VERSION ""

NS_ :

BS_:

BU_: VMCU VGGSECUSystem TECU OBDScanT2 HMIIOM EMS ECUspare2 ECUspare1 DACU CIOM BBM

BO_ 2432645412 VMCU_BB2_02P: 8 VMCU
 SG_ LevelControlInformation_UB_ISig_ : 22|1@1+ (1,0) [0|0] ""  CIOM,HMIIOM,TECU
 SG_ LiftAxle2LiftFuncSelected_ISig_4 : 11|3@1+ (1,0) [0|0] ""  HMIIOM
 SG_ StopLevelChangeAck_ISig_4 : 6|2@1+ (1,0) [0|0] ""  CIOM
 SG_ HeightAdjustmentAllowed_ISig_4 : 38|2@1+ (1,0) [0|0] ""  CIOM
 SG_ LiftAxle2UpRequestACK_ISig_4 : 0|3@1+ (1,0) [0|0] ""  CIOM,HMIIOM
 SG_ RideHeightStatus_ISig_4 : 44|4@1+ (1,0) [0|0] ""  HMIIOM,CIOM,BBM
 SG_ RideHeightOutsideTargetRange_ISi : 32|3@1+ (1,0) [0|0] ""  HMIIOM,CIOM
 SG_ LoadDistributionFuncSelected_ISi : 56|4@1+ (1,0) [0|0] ""  CIOM
 SG_ RideHeightStorageAck_ISig_4 : 30|2@1+ (1,0) [0|0] ""  CIOM
 SG_ LiftAxle2LowerACK_ISig_4 : 27|3@1+ (1,0) [0|0] ""  HMIIOM
 SG_ LiftAxle1UpRequestACK_ISig_4 : 3|3@1+ (1,0) [0|0] ""  HMIIOM,CIOM
 SG_ LiftAxle1PositionStatus_ISig_4 : 16|3@1+ (1,0) [0|0] ""  BBM,CIOM,TECU,DACU,HMIIOM
 SG_ LiftAxle2AutoLiftSelected_ISig_4 : 54|2@1+ (1,0) [0|0] ""  HMIIOM
 SG_ LiftAxle1LowerACK_ISig_4 : 24|3@1+ (1,0) [0|0] ""  HMIIOM
 SG_ LiftAxle2PositionStatus_ISig_4 : 19|3@1+ (1,0) [0|0] ""  HMIIOM,BBM,CIOM
 SG_ LevelControlInformation_ISig_4 : 48|4@1+ (1,0) [0|0] ""  TECU,HMIIOM,CIOM
 SG_ LoadDistributionChangeACK_ISig_4 : 35|3@1+ (1,0) [0|0] ""  HMIIOM,CIOM
 SG_ LiftAxle1AutoLiftSelected_ISig_4 : 52|2@1+ (1,0) [0|0] ""  HMIIOM
 SG_ LiftAxle1LiftFuncSelected_ISig_4 : 8|3@1+ (1,0) [0|0] ""  HMIIOM
 SG_ RampLevelStorageAck_ISig_4 : 14|2@1+ (1,0) [0|0] ""  CIOM
 SG_ LoadDistributionSelected_ISig_4 : 60|4@1+ (1,0) [0|0] ""  HMIIOM,BBM,CIOM
 SG_ RideHeightFunctionStatus_ISig_4 : 40|4@1+ (1,0) [0|0] ""  HMIIOM,CIOM

BO_ 2432638500 VMCU_BB2_01P: 8 VMCU
 SG_ GearSplit_Status_UB_ISig_4 : 13|1@1+ (1,0) [0|0] ""  HMIIOM,BBM
 SG_ TransmLowRangeSenseSwitch_ISig_4 : 34|2@1+ (1,0) [0|0] ""  HMIIOM,EMS
 SG_ TransmSystemPowerDown_rqst : 30|2@1+ (1,0) [0|0] ""  TECU
 SG_ TransmissionNeutralSwitch_ISig_4 : 8|2@1+ (1,0) [0|0] ""  BBM,EMS
 SG_ SecuredNeutralPosition_ISig_4 : 36|2@1+ (1,0) [0|0] ""  EMS,HMIIOM,BBM
 SG_ EngineStopRequest_ISig_4 : 4|2@1+ (1,0) [0|0] ""  EMS
 SG_ DirectionIndicatorLights_rqst_IS : 19|3@1+ (1,0) [0|0] ""  HMIIOM,DACU
 SG_ TransmissionNeutralSwitch_UB_ISi : 32|1@1+ (1,0) [0|0] ""  EMS,BBM
 SG_ ReverseGearEngaged_ISig_4 : 0|2@1+ (1,0) [0|0] ""  DACU,EMS,CIOM,BBM,HMIIOM
 SG_ TransmSystemPowerDown_rqst_UB : 33|1@1+ (1,0) [0|0] ""  TECU
 SG_ EngineCrankRequest : 14|2@1+ (1,0) [0|0] ""  EMS
 SG_ ParkBrakeActuationStatus_UB_ISig : 39|1@1+ (1,0) [0|0] ""  HMIIOM,DACU,TECU,VGGSECUSystem,BBM
 SG_ ParkBrakeActuationStatus_ISig_4 : 40|3@1+ (1,0) [0|0] ""  VGGSECUSystem,DACU,TECU,BBM,HMIIOM
 SG_ EnginePreheat_rqst : 28|2@1+ (1,0) [0|0] ""  EMS
 SG_ ReverseGearEngaged_UB_ISig_4 : 12|1@1+ (1,0) [0|0] ""  EMS,DACU,HMIIOM,CIOM,BBM
 SG_ AcceleratorPedalPositionBackup : 56|8@1+ (0.4,0) [0|102] "Percent"  EMS,TECU
 SG_ KeyPosition_ISig_4 : 16|3@1+ (1,0) [0|0] ""  VGGSECUSystem,CIOM,HMIIOM
 SG_ GearSplit_Status_ISig_4 : 2|2@1+ (1,0) [0|0] ""  HMIIOM,BBM
 SG_ FerryFunctionSwitchChangeACK_ISi : 45|2@1+ (1,0) [0|0] ""  CIOM
 SG_ SecuredNeutralPosition_UB_ISig_4 : 38|1@1+ (1,0) [0|0] ""  BBM,HMIIOM,EMS
 SG_ DirectionIndication_cmd_ISig_4 : 24|4@1+ (1,0) [0|0] ""  HMIIOM
 SG_ IdleShutdownWarning_ISig_4 : 6|2@1+ (1,0) [0|0] ""  HMIIOM
 SG_ BackToDriveReqACK_ISig_4 : 43|2@1+ (1,0) [0|0] ""  CIOM
 SG_ EngineSystemPowerDownRequest_ISi : 22|2@1+ (1,0) [0|0] ""  EMS,HMIIOM

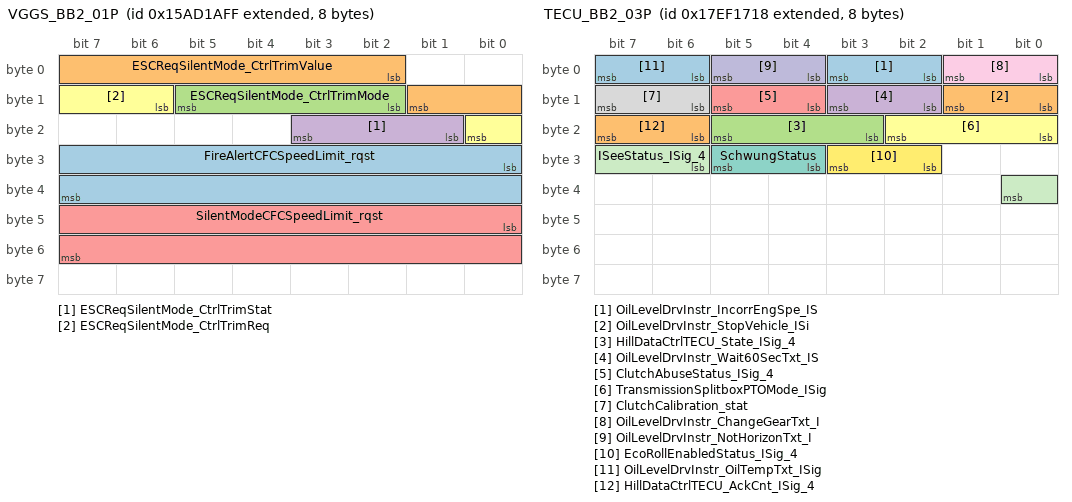
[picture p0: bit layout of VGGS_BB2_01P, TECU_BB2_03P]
BO_ 2511149823 VGGS_BB2_01P: 8 VGGSECUSystem
 SG_ FireAlertCFCSpeedLimit_rqst : 24|16@1+ (1,0) [0|65535] "rpm"  EMS
 SG_ ESCReqSilentMode_CtrlTrimValue : 2|8@1+ (10,0) [0|2550] ""  VMCU
 SG_ ESCReqSilentMode_CtrlTrimMode : 10|4@1+ (1,0) [0|0] ""  VMCU
 SG_ ESCReqSilentMode_CtrlTrimStat : 17|3@1+ (1,0) [0|0] ""  VMCU
 SG_ SilentModeCFCSpeedLimit_rqst : 40|16@1+ (1,0) [0|65535] "rpm"  EMS
 SG_ ESCReqSilentMode_CtrlTrimReq : 14|3@1+ (1,0) [0|0] ""  VMCU

BO_ 2671902706 TesterFuncDiagMsg_BB2: 8 VMCU
 SG_ FuncDiagDataTester_ISig_4 : 0|64@1+ (1,0) [0|0] ""  HMIIOM,BBM,EMS,DACU,CIOM,TECU

BO_ 2566356992 TECU_BB2_06S_FCM: 8 CIOM
 SG_ TECU_BB2_06S_FCS : 0|64@1+ (1,0) [0|0] ""  TECU

BO_ 2566356991 TECU_BB2_06S: 11 TECU
 SG_ ECU5VIN_stat : 0|88@1+ (1,0) [0|0] ""  CIOM

BO_ 2499794048 TECU_BB2_05S_FCM: 8 CIOM
 SG_ TECU_BB2_05S_FCS : 0|64@1+ (1,0) [0|0] ""  TECU

BO_ 2499794047 TECU_BB2_05S: 16 TECU
 SG_ KeyID_EncryptedGBUnlockAuth : 0|128@1+ (1,0) [0|0] ""  CIOM

BO_ 2583412505 TECU_BB2_04S_FCM: 8 HMIIOM
 SG_ TECU_BB2_04S_FCS : 0|64@1+ (1,0) [0|0] ""  TECU

BO_ 2583412504 TECU_BB2_04S: 284 TECU
 SG_ HillDataPkgTECU_ISig_4 : 0|2272@1+ (1,0) [0|0] ""  HMIIOM

BO_ 2549028632 TECU_BB2_03P: 8 TECU
 SG_ OilLevelDrvInstr_IncorrEngSpe_IS : 2|2@1+ (1,0) [0|0] ""  HMIIOM
 SG_ OilLevelDrvInstr_StopVehicle_ISi : 8|2@1+ (1,0) [0|0] ""  HMIIOM
 SG_ HillDataCtrlTECU_State_ISig_4 : 19|3@1+ (1,0) [0|0] ""  HMIIOM
 SG_ OilLevelDrvInstr_Wait60SecTxt_IS : 10|2@1+ (1,0) [0|0] ""  HMIIOM
 SG_ ClutchAbuseStatus_ISig_4 : 12|2@1+ (1,0) [0|0] ""  HMIIOM
 SG_ TransmissionSplitboxPTOMode_ISig : 16|3@1+ (1,0) [0|0] ""  HMIIOM
 SG_ SchwungStatus : 28|2@1+ (1,0) [0|0] ""  VMCU
 SG_ ClutchCalibration_stat : 14|2@1+ (1,0) [0|0] ""  HMIIOM
 SG_ OilLevelDrvInstr_ChangeGearTxt_I : 0|2@1+ (1,0) [0|0] ""  HMIIOM
 SG_ OilLevelDrvInstr_NotHorizonTxt_I : 4|2@1+ (1,0) [0|0] ""  HMIIOM
 SG_ ISeeStatus_ISig_4 : 30|3@1+ (1,0) [0|0] ""  HMIIOM
 SG_ EcoRollEnabledStatus_ISig_4 : 26|2@1+ (1,0) [0|0] ""  HMIIOM
 SG_ OilLevelDrvInstr_OilTempTxt_ISig : 6|2@1+ (1,0) [0|0] ""  HMIIOM
 SG_ HillDataCtrlTECU_AckCnt_ISig_4 : 22|2@1+ (1,0) [0|3] ""  HMIIOM

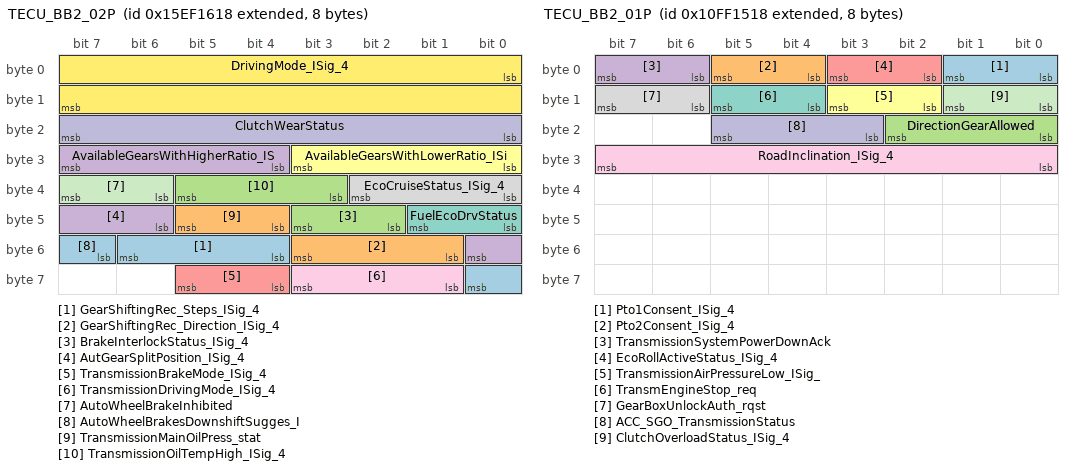
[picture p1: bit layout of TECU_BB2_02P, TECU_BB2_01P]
BO_ 2515473944 TECU_BB2_02P: 8 TECU
 SG_ GearShiftingRec_Steps_ISig_4 : 52|3@1+ (1,0) [0|0] ""  HMIIOM
 SG_ GearShiftingRec_Direction_ISig_4 : 49|3@1+ (1,0) [0|0] ""  HMIIOM
 SG_ BrakeInterlockStatus_ISig_4 : 42|2@1+ (1,0) [0|0] ""  HMIIOM
 SG_ AutGearSplitPosition_ISig_4 : 46|3@1+ (1,0) [0|0] ""  HMIIOM
 SG_ TransmissionBrakeMode_ISig_4 : 60|2@1+ (1,0) [0|0] ""  HMIIOM
 SG_ AvailableGearsWithLowerRatio_ISi : 24|4@1+ (1,0) [0|15] "Count"  HMIIOM
 SG_ FuelEcoDrvStatus : 40|2@1+ (1,0) [0|0] ""  VMCU
 SG_ EcoCruiseStatus_ISig_4 : 32|3@1+ (1,0) [0|0] ""  HMIIOM,EMS
 SG_ TransmissionDrivingMode_ISig_4 : 57|3@1+ (1,0) [0|0] ""  HMIIOM
 SG_ ClutchWearStatus : 16|8@1+ (0.4,0) [0|102] "Percent"  VMCU
 SG_ AutoWheelBrakeInhibited : 38|2@1+ (1,0) [0|0] ""  EMS
 SG_ DrivingMode_ISig_4 : 0|16@1+ (1,0) [0|0] ""  VMCU,HMIIOM
 SG_ AutoWheelBrakesDownshiftSugges_I : 55|2@1+ (1,0) [0|0] ""  HMIIOM
 SG_ TransmissionMainOilPress_stat : 44|2@1+ (1,0) [0|0] ""  HMIIOM
 SG_ TransmissionOilTempHigh_ISig_4 : 35|3@1+ (1,0) [0|0] ""  BBM,HMIIOM
 SG_ AvailableGearsWithHigherRatio_IS : 28|4@1+ (1,0) [0|15] "Count"  VMCU,HMIIOM

BO_ 2432636184 TECU_BB2_01P: 8 TECU
 SG_ Pto1Consent_ISig_4 : 0|2@1+ (1,0) [0|0] ""  BBM,VMCU
 SG_ Pto2Consent_ISig_4 : 4|2@1+ (1,0) [0|0] ""  BBM,VMCU
 SG_ DirectionGearAllowed : 16|3@1+ (1,0) [0|0] ""  HMIIOM
 SG_ TransmissionSystemPowerDownAck : 6|2@1+ (1,0) [0|0] ""  VMCU
 SG_ EcoRollActiveStatus_ISig_4 : 2|2@1+ (1,0) [0|0] ""  HMIIOM,VMCU
 SG_ TransmissionAirPressureLow_ISig_ : 10|2@1+ (1,0) [0|0] ""  HMIIOM
 SG_ TransmEngineStop_req : 12|2@1+ (1,0) [0|0] ""  EMS
 SG_ GearBoxUnlockAuth_rqst : 14|2@1+ (1,0) [0|0] ""  CIOM
 SG_ RoadInclination_ISig_4 : 24|8@1+ (0.2,-25) [-25|26] "Percent"  HMIIOM,VMCU,EMS,DACU
 SG_ ACC_SGO_TransmissionStatus : 19|3@1+ (1,0) [0|0] ""  EMS,DACU
 SG_ ClutchOverloadStatus_ISig_4 : 8|2@1+ (1,0) [0|0] ""  HMIIOM,BBM

BO_ 2365530173 Reserved_CANid_02_BB2: 8 Vector__XXX

BO_ 2365530429 Reserved_CANid_01_BB2: 8 Vector__XXX

BO_ 2671833830 PhysDiagRespMsg_F2_E6_BB2: 8 BBM
 SG_ PhysDiagRespSig_F2_E6_ISig_4 : 0|64@1+ (1,0) [0|0] ""  VMCU

BO_ 2671833829 PhysDiagRespMsg_F2_E5_BB2: 8 BBM
 SG_ PhysDiagRespSig_F2_E5_ISig_4 : 0|64@1+ (1,0) [0|0] ""  VMCU

BO_ 2671833792 PhysDiagRespMsg_F2_C0_BB2: 8 CIOM
 SG_ PhysDiagRespSig_F2_C0_ISig_4 : 0|64@1+ (1,0) [0|0] ""  VMCU

BO_ 2671833762 PhysDiagRespMsg_F2_A2_BB2: 8 CIOM
 SG_ PhysDiagRespSig_F2_A2_ISig_4 : 0|64@1+ (1,0) [0|0] ""  VMCU

BO_ 2671833761 PhysDiagRespMsg_F2_A1_BB2: 8 CIOM
 SG_ PhysDiagRespSig_F2_A1_ISig_4 : 0|64@1+ (1,0) [0|0] ""  VMCU

BO_ 2671833760 PhysDiagRespMsg_F2_A0_BB2: 8 CIOM
 SG_ PhysDiagRespSig_F2_A0_ISig_4 : 0|64@1+ (1,0) [0|0] ""  VMCU

BO_ 2671833752 PhysDiagRespMsg_F2_98_BB2: 8 CIOM
 SG_ PhysDiagRespSig_F2_98_ISig_4 : 0|64@1+ (1,0) [0|0] ""  VMCU

BO_ 2671833730 PhysDiagRespMsg_F2_82_BB2: 8 HMIIOM
 SG_ PhysDiagRespSig_F2_82_ISig_4 : 0|64@1+ (1,0) [0|0] ""  VMCU

BO_ 2671833728 PhysDiagRespMsg_F2_80_BB2: 8 HMIIOM
 SG_ PhysDiagRespSig_F2_80_ISig_4 : 0|64@1+ (1,0) [0|0] ""  VMCU

BO_ 2671833699 PhysDiagRespMsg_F2_63_BB2: 8 HMIIOM
 SG_ PhysDiagRespSig_F2_63_ISig_4 : 0|64@1+ (1,0) [0|0] ""  VMCU

BO_ 2671833698 PhysDiagRespMsg_F2_62_BB2: 8 HMIIOM
 SG_ PhysDiagRespSig_F2_62_ISig_4 : 0|64@1+ (1,0) [0|0] ""  VMCU

BO_ 2671833697 PhysDiagRespMsg_F2_61_BB2: 8 HMIIOM
 SG_ PhysDiagRespSig_F2_61_ISig_4 : 0|64@1+ (1,0) [0|0] ""  VMCU

BO_ 2671833696 PhysDiagRespMsg_F2_60_BB2: 8 HMIIOM
 SG_ PhysDiagRespSig_F2_60_ISig_4 : 0|64@1+ (1,0) [0|0] ""  VMCU

BO_ 2671833683 PhysDiagRespMsg_F2_53_BB2: 8 CIOM
 SG_ PhysDiagRespSig_F2_53_ISig_4 : 0|64@1+ (1,0) [0|0] ""  VMCU

BO_ 2671833682 PhysDiagRespMsg_F2_52_BB2: 8 DACU
 SG_ PhysDiagRespSig_F2_52_ISig_4 : 0|64@1+ (1,0) [0|0] ""  VMCU

BO_ 2671833681 PhysDiagRespMsg_F2_51_BB2: 8 DACU
 SG_ PhysDiagRespSig_F2_51_ISig_4 : 0|64@1+ (1,0) [0|0] ""  VMCU

BO_ 2671833680 PhysDiagRespMsg_F2_50_BB2: 8 DACU
 SG_ PhysDiagRespSig_F2_50_ISig_4 : 0|64@1+ (1,0) [0|0] ""  VMCU

BO_ 2671833665 PhysDiagRespMsg_F2_41_BB2: 8 HMIIOM
 SG_ PhysDiagRespSig_F2_41_ISig_4 : 0|64@1+ (1,0) [0|0] ""  VMCU

BO_ 2671833664 PhysDiagRespMsg_F2_40_BB2: 8 CIOM
 SG_ PhysDiagRespSig_F2_40_ISig_4 : 0|64@1+ (1,0) [0|0] ""  VMCU

BO_ 2671833638 PhysDiagRespMsg_F2_26_BB2: 8 CIOM
 SG_ PhysDiagRespSig_F2_26_ISig_4 : 0|64@1+ (1,0) [0|0] ""  VMCU

BO_ 2671833624 PhysDiagRespMsg_F2_18_BB2: 8 TECU
 SG_ PhysDiagRespSig_F2_18_ISig_4 : 0|64@1+ (1,0) [0|0] ""  VMCU

BO_ 2671833616 PhysDiagRespMsg_F2_10_BB2: 8 EMS
 SG_ PhysDiagRespSig_F2_10_ISig_4 : 0|64@1+ (1,0) [0|0] ""  VMCU

BO_ 2564485459 PhysDiagRespMsg_F1_53_BB2: 8 CIOM
 SG_ PhysDiagRespSig_F1_53_ISig_4 : 0|64@1+ (1,0) [0|0] ""  VMCU

BO_ 2564485392 PhysDiagRespMsg_F1_10_BB2_extra: 8 EMS
 SG_ PhysDiagRespSig_F1_10_extra : 0|64@1+ (1,0) [0|0] ""  OBDScanT2

BO_ 2671833360 PhysDiagRespMsg_F1_10_BB2: 8 EMS
 SG_ PhysDiagRespSig_F1_10_ISig_4 : 0|64@1+ (1,0) [0|0] ""  VMCU

BO_ 2671830770 PhysDiagReqMsg_E6_F2_BB2: 8 VMCU
 SG_ PhysDiagReqSig_E6_F2_ISig_4 : 0|64@1+ (1,0) [0|0] ""  BBM

BO_ 2671830514 PhysDiagReqMsg_E5_F2_BB2: 8 VMCU
 SG_ PhysDiagReqSig_E5_F2_ISig_4 : 0|64@1+ (1,0) [0|0] ""  BBM

BO_ 2671821042 PhysDiagReqMsg_C0_F2_BB2: 8 VMCU
 SG_ PhysDiagReqSig_C0_F2_ISig_4 : 0|64@1+ (1,0) [0|0] ""  CIOM

BO_ 2671813362 PhysDiagReqMsg_A2_F2_BB2: 8 VMCU
 SG_ PhysDiagReqSig_A2_F2_ISig_4 : 0|64@1+ (1,0) [0|0] ""  CIOM

BO_ 2671813106 PhysDiagReqMsg_A1_F2_BB2: 8 VMCU
 SG_ PhysDiagReqSig_A1_F2_ISig_4 : 0|64@1+ (1,0) [0|0] ""  CIOM

BO_ 2671812850 PhysDiagReqMsg_A0_F2_BB2: 8 VMCU
 SG_ PhysDiagReqSig_A0_F2_ISig_4 : 0|64@1+ (1,0) [0|0] ""  CIOM

BO_ 2671810802 PhysDiagReqMsg_98_F2_BB2: 8 VMCU
 SG_ PhysDiagReqSig_98_F2_ISig_4 : 0|64@1+ (1,0) [0|0] ""  CIOM

BO_ 2671805170 PhysDiagReqMsg_82_F2_BB2: 8 VMCU
 SG_ PhysDiagReqSig_82_F2_ISig_4 : 0|64@1+ (1,0) [0|0] ""  HMIIOM

BO_ 2671804658 PhysDiagReqMsg_80_F2_BB2: 8 VMCU
 SG_ PhysDiagReqSig_80_F2_ISig_4 : 0|64@1+ (1,0) [0|0] ""  HMIIOM

BO_ 2671797234 PhysDiagReqMsg_63_F2_BB2: 8 VMCU
 SG_ PhysDiagReqSig_63_F2_ISig_4 : 0|64@1+ (1,0) [0|0] ""  HMIIOM

BO_ 2671796978 PhysDiagReqMsg_62_F2_BB2: 8 VMCU
 SG_ PhysDiagReqSig_62_F2_ISig_4 : 0|64@1+ (1,0) [0|0] ""  HMIIOM

BO_ 2671796722 PhysDiagReqMsg_61_F2_BB2: 8 VMCU
 SG_ PhysDiagReqSig_61_F2_ISig_4 : 0|64@1+ (1,0) [0|0] ""  HMIIOM

BO_ 2671796466 PhysDiagReqMsg_60_F2_BB2: 8 VMCU
 SG_ PhysDiagReqSig_60_F2_ISig_4 : 0|64@1+ (1,0) [0|0] ""  HMIIOM

BO_ 2671793138 PhysDiagReqMsg_53_F2_BB2: 8 VMCU
 SG_ PhysDiagReqSig_53_F2_ISig_4 : 0|64@1+ (1,0) [0|0] ""  CIOM

BO_ 2564445169 PhysDiagReqMsg_53_F1_BB2: 8 VMCU
 SG_ PhysDiagReqSig_53_F1_ISig_4 : 0|64@1+ (1,0) [0|0] ""  CIOM

BO_ 2671792882 PhysDiagReqMsg_52_F2_BB2: 8 VMCU
 SG_ PhysDiagReqSig_52_F2_ISig_4 : 0|64@1+ (1,0) [0|0] ""  DACU

BO_ 2671792626 PhysDiagReqMsg_51_F2_BB2: 8 VMCU
 SG_ PhysDiagReqSig_51_F2_ISig_4 : 0|64@1+ (1,0) [0|0] ""  DACU

BO_ 2671792370 PhysDiagReqMsg_50_F2_BB2: 8 VMCU
 SG_ PhysDiagReqSig_50_F2_ISig_4 : 0|64@1+ (1,0) [0|0] ""  DACU

BO_ 2671788530 PhysDiagReqMsg_41_F2_BB2: 8 VMCU
 SG_ PhysDiagReqSig_41_F2_ISig_4 : 0|64@1+ (1,0) [0|0] ""  HMIIOM

BO_ 2671788274 PhysDiagReqMsg_40_F2_BB2: 8 VMCU
 SG_ PhysDiagReqSig_40_F2_ISig_4 : 0|64@1+ (1,0) [0|0] ""  CIOM

BO_ 2671781618 PhysDiagReqMsg_26_F2_BB2: 8 VMCU
 SG_ PhysDiagReqSig_26_F2_ISig_4 : 0|64@1+ (1,0) [0|0] ""  CIOM

BO_ 2671778034 PhysDiagReqMsg_18_F2_BB2: 8 VMCU
 SG_ PhysDiagReqSig_18_F2_ISig_4 : 0|64@1+ (1,0) [0|0] ""  TECU

BO_ 2671775986 PhysDiagReqMsg_10_F2_BB2: 8 VMCU
 SG_ PhysDiagReqSig_10_F2_ISig_4 : 0|64@1+ (1,0) [0|0] ""  EMS

BO_ 2564428017 PhysDiagReqMsg_10_F1_BB2_extra: 8 OBDScanT2
 SG_ PhysDiagReqSig_10_F1_extra : 0|64@1+ (1,0) [0|0] ""  EMS

BO_ 2671775985 PhysDiagReqMsg_10_F1_BB2: 8 VMCU
 SG_ PhysDiagReqSig_10_F1_ISig_4 : 0|64@1+ (1,0) [0|0] ""  EMS

BO_ 2564502513 OBDFuncDiagMsg_BB2_extra: 8 OBDScanT2
 SG_ FuncDiagDataOBD_extra : 0|64@1+ (1,0) [0|0] ""  EMS

BO_ 2671850481 OBDFuncDiagMsg_BB2: 8 VMCU
 SG_ FuncDiagDataOBD_ISig_4 : 0|64@1+ (1,0) [0|0] ""  EMS

BO_ 2633990180 NmAsr_VMCU_BB2: 1 VMCU

BO_ 2633990168 NmAsr_TECU_BB2: 1 TECU

BO_ 2633990240 NmAsr_HMIIOM_BB2: 1 HMIIOM

BO_ 2633990160 NmAsr_EMS_BB2: 1 EMS

BO_ 2633990224 NmAsr_DACU_BB2: 1 DACU

BO_ 2633990208 NmAsr_CIOM_BB2: 1 CIOM

BO_ 2633990374 NmAsr_BBM_BB2: 1 BBM

BO_ 2671902708 IntTesterTGW2FuncDiagMsg_BB2: 8 HMIIOM
 SG_ FuncDiagDataIntTesterTGW2_ISig_4 : 0|64@1+ (1,0) [0|0] ""  EMS,BBM,DACU,CIOM,TECU,VMCU

BO_ 2582855521 HMIIOM_BB2_S28_FCM: 8 TECU
 SG_ HMIIOM_BB2_S28_FCS : 0|64@1+ (1,0) [0|0] ""  HMIIOM

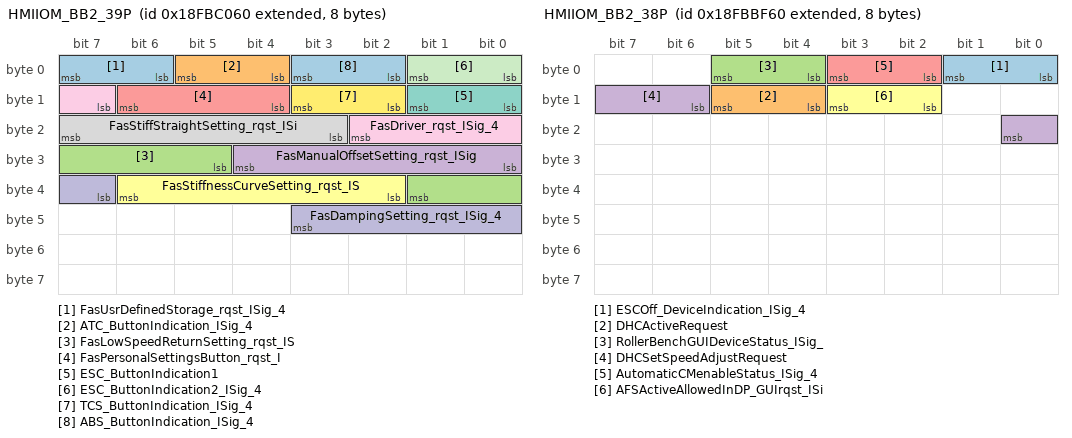
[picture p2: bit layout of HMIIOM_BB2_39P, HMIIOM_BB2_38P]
BO_ 2566635616 HMIIOM_BB2_39P: 8 HMIIOM
 SG_ FasUsrDefinedStorage_rqst_ISig_4 : 6|2@1+ (1,0) [0|0] ""  VMCU
 SG_ ATC_ButtonIndication_ISig_4 : 4|2@1+ (1,0) [0|0] ""  CIOM
 SG_ FasLowSpeedReturnSetting_rqst_IS : 29|5@1+ (1,-10) [-10|21] ""  VMCU
 SG_ FasManualOffsetSetting_rqst_ISig : 24|5@1+ (1,-10) [-10|21] ""  VMCU
 SG_ FasPersonalSettingsButton_rqst_I : 12|3@1+ (1,0) [0|0] ""  VMCU
 SG_ FasStiffnessCurveSetting_rqst_IS : 34|5@1+ (1,-10) [-10|21] ""  VMCU
 SG_ ESC_ButtonIndication1 : 8|2@1+ (1,0) [0|0] ""  CIOM
 SG_ FasStiffStraightSetting_rqst_ISi : 19|5@1+ (1,-10) [-10|21] ""  VMCU
 SG_ FasDriver_rqst_ISig_4 : 15|4@1+ (1,0) [0|0] ""  VMCU
 SG_ FasDampingSetting_rqst_ISig_4 : 39|5@1+ (1,-10) [-10|21] ""  VMCU
 SG_ ESC_ButtonIndication2_ISig_4 : 0|2@1+ (1,0) [0|0] ""  CIOM
 SG_ TCS_ButtonIndication_ISig_4 : 10|2@1+ (1,0) [0|0] ""  CIOM
 SG_ ABS_ButtonIndication_ISig_4 : 2|2@1+ (1,0) [0|0] ""  CIOM

BO_ 2566635360 HMIIOM_BB2_38P: 8 HMIIOM
 SG_ ESCOff_DeviceIndication_ISig_4 : 0|2@1+ (1,0) [0|0] ""  CIOM
 SG_ DHCActiveRequest : 12|2@1+ (1,0) [0|0] ""  VMCU
 SG_ RollerBenchGUIDeviceStatus_ISig_ : 4|2@1+ (1,0) [0|0] ""  CIOM
 SG_ DHCSetSpeedAdjustRequest : 14|3@1+ (1,0) [0|0] ""  VMCU
 SG_ AutomaticCMenableStatus_ISig_4 : 2|2@1+ (1,0) [0|0] ""  DACU
 SG_ AFSActiveAllowedInDP_GUIrqst_ISi : 10|2@1+ (1,0) [0|0] ""  VMCU

BO_ 2432637476 HMIIOM_BB2_37S: 8 HMIIOM
 SG_ AdasisMapData_ISig_4 : 7|64@0+ (1,0) [0|0] ""  TECU

BO_ 2566357089 HMIIOM_BB2_36S_FCM: 8 CIOM
 SG_ HMIIOM_BB2_36S_FCS : 0|64@1+ (1,0) [0|0] ""  HMIIOM

BO_ 2566357088 HMIIOM_BB2_36S: 36 HMIIOM
 SG_ SEM_DisplayText_stat_ISig_4 : 0|288@1+ (1,0) [0|0] ""  CIOM

BO_ 2499772257 HMIIOM_BB2_35S_FCM: 8 CIOM
 SG_ HMIIOM_BB2_35S_FCS : 0|64@1+ (1,0) [0|0] ""  HMIIOM

BO_ 2499772256 HMIIOM_BB2_35S: 98 HMIIOM
 SG_ MediaSourcesListRsp_sg_UB_ISig_4 : 782|1@1+ (1,0) [0|0] ""  CIOM
 SG_ MediaSourcesListRsp_SrcAttrib_IS : 392|384@1+ (1,0) [0|0] ""  CIOM
 SG_ MediaSourcesListRsp_SInfo_ISig_4 : 780|2@1+ (1,0) [0|0] ""  CIOM
 SG_ MediaSourcesListRsp_Name_ISig_4 : 8|384@1+ (1,0) [0|0] ""  CIOM
 SG_ MediaSourcesListRsp_PCI_ISig_4 : 0|8@1+ (1,0) [0|255] ""  CIOM
 SG_ MediaSourcesListRsp_ItemID_ISig_ : 776|4@1+ (1,0) [0|0] ""  CIOM

BO_ 2499788640 HMIIOM_BB2_34S: 8 HMIIOM
 SG_ MediaSourcesListNPRsp_ISig_4 : 0|8@1+ (1,0) [0|255] ""  CIOM
 SG_ MediaSourcesListNPRsp_UB_ISig_4 : 8|1@1+ (1,0) [0|0] ""  CIOM

BO_ 2477212768 HMIIOM_BB2_33P: 8 HMIIOM
 SG_ DirInd_StalkStatus_4 : 35|3@1+ (1,0) [0|0] ""  VMCU
 SG_ SEMMediaSourceAvail_Source04_ISi : 4|1@1+ (1,0) [0|0] ""  CIOM
 SG_ SEMMediaSourceAvail_Source10_ISi : 10|1@1+ (1,0) [0|0] ""  CIOM
 SG_ SEMMediaSourceAvail_SInfo_ISig_4 : 14|2@1+ (1,0) [0|0] ""  CIOM
 SG_ SEM_PresetIndicationCmd_ISig_4 : 25|6@1+ (1,0) [0|63] "Enumeration"  CIOM
 SG_ SEMMediaSourceAvail_Source09_ISi : 9|1@1+ (1,0) [0|0] ""  CIOM
 SG_ SEMMediaSourceAvail_Source12_ISi : 12|1@1+ (1,0) [0|0] ""  CIOM
 SG_ SEMMediaSourceAvail_Source07_ISi : 7|1@1+ (1,0) [0|0] ""  CIOM
 SG_ TripmeterReset_rqst1_ISig_4 : 38|3@1+ (1,0) [0|0] ""  VMCU
 SG_ SEMMediaSourceAvail_Source03_ISi : 3|1@1+ (1,0) [0|0] ""  CIOM
 SG_ SEMMediaSourceAvail_Source11_ISi : 11|1@1+ (1,0) [0|0] ""  CIOM
 SG_ SEM_AudioVolValIndCmd_ISig_4 : 19|6@1+ (1,0) [0|63] "Step"  CIOM
 SG_ SEMMediaSourceAvail_Source02_ISi : 2|1@1+ (1,0) [0|0] ""  CIOM
 SG_ AudioSourceStat_ISig_4 : 31|4@1+ (1,0) [0|0] ""  CIOM
 SG_ SEMMediaSourceAvail_Source06_ISi : 6|1@1+ (1,0) [0|0] ""  CIOM
 SG_ SEMMediaSourceAvail_Source00_ISi : 0|1@1+ (1,0) [0|0] ""  CIOM
 SG_ SEMMediaSourceAvail_Source01_ISi : 1|1@1+ (1,0) [0|0] ""  CIOM
 SG_ SEMMediaSourceAvail_Source08_ISi : 8|1@1+ (1,0) [0|0] ""  CIOM
 SG_ SEM_AudioMuteStat_ISig_4 : 16|3@1+ (1,0) [0|0] ""  CIOM
 SG_ SEMMediaSourceAvail_Source13_ISi : 13|1@1+ (1,0) [0|0] ""  CIOM
 SG_ SEMMediaSourceAvail_Source05_ISi : 5|1@1+ (1,0) [0|0] ""  CIOM

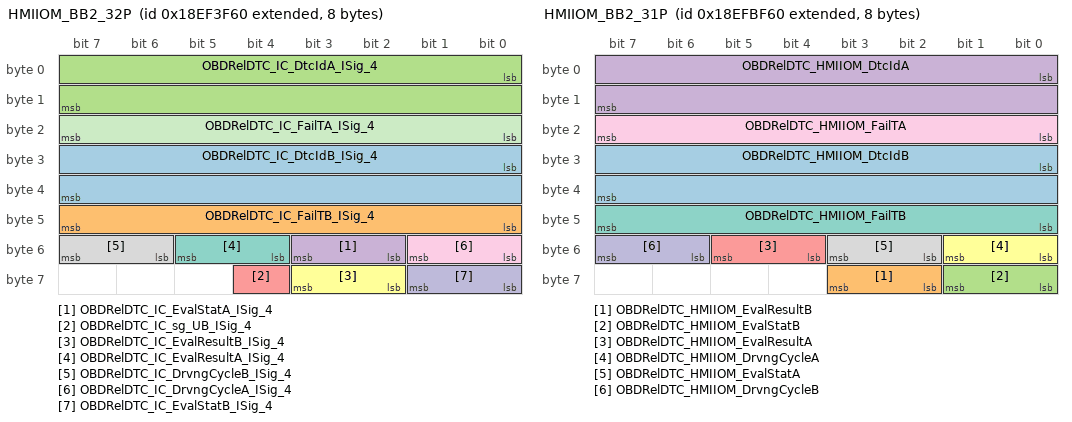
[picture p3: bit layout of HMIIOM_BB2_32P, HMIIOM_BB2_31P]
BO_ 2565816160 HMIIOM_BB2_32P: 8 HMIIOM
 SG_ OBDRelDTC_IC_DtcIdB_ISig_4 : 24|16@1+ (1,0) [0|65535] ""  VMCU
 SG_ OBDRelDTC_IC_FailTB_ISig_4 : 40|8@1+ (1,0) [0|255] ""  VMCU
 SG_ OBDRelDTC_IC_DtcIdA_ISig_4 : 0|16@1+ (1,0) [0|65535] ""  VMCU
 SG_ OBDRelDTC_IC_EvalStatA_ISig_4 : 50|2@1+ (1,0) [0|0] ""  VMCU
 SG_ OBDRelDTC_IC_sg_UB_ISig_4 : 60|1@1+ (1,0) [0|0] ""  VMCU
 SG_ OBDRelDTC_IC_EvalResultB_ISig_4 : 58|2@1+ (1,0) [0|0] ""  VMCU
 SG_ OBDRelDTC_IC_EvalResultA_ISig_4 : 52|2@1+ (1,0) [0|0] ""  VMCU
 SG_ OBDRelDTC_IC_DrvngCycleB_ISig_4 : 54|2@1+ (1,0) [0|0] ""  VMCU
 SG_ OBDRelDTC_IC_DrvngCycleA_ISig_4 : 48|2@1+ (1,0) [0|0] ""  VMCU
 SG_ OBDRelDTC_IC_EvalStatB_ISig_4 : 56|2@1+ (1,0) [0|0] ""  VMCU
 SG_ OBDRelDTC_IC_FailTA_ISig_4 : 16|8@1+ (1,0) [0|255] ""  VMCU

BO_ 2565848928 HMIIOM_BB2_31P: 8 HMIIOM
 SG_ OBDRelDTC_HMIIOM_DtcIdB : 24|16@1+ (1,0) [0|65535] ""  VMCU
 SG_ OBDRelDTC_HMIIOM_EvalResultB : 58|2@1+ (1,0) [0|0] ""  VMCU
 SG_ OBDRelDTC_HMIIOM_EvalStatB : 56|2@1+ (1,0) [0|0] ""  VMCU
 SG_ OBDRelDTC_HMIIOM_DtcIdA : 0|16@1+ (1,0) [0|65535] ""  VMCU
 SG_ OBDRelDTC_HMIIOM_EvalResultA : 52|2@1+ (1,0) [0|0] ""  VMCU
 SG_ OBDRelDTC_HMIIOM_DrvngCycleA : 48|2@1+ (1,0) [0|0] ""  VMCU
 SG_ OBDRelDTC_HMIIOM_FailTB : 40|8@1+ (1,0) [0|255] ""  VMCU
 SG_ OBDRelDTC_HMIIOM_EvalStatA : 50|2@1+ (1,0) [0|0] ""  VMCU
 SG_ OBDRelDTC_HMIIOM_FailTA : 16|8@1+ (1,0) [0|255] ""  VMCU
 SG_ OBDRelDTC_HMIIOM_DrvngCycleB : 54|2@1+ (1,0) [0|0] ""  VMCU

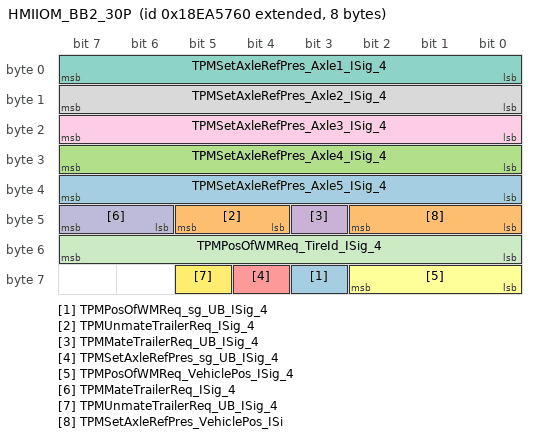
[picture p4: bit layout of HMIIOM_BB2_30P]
BO_ 2565494624 HMIIOM_BB2_30P: 8 HMIIOM
 SG_ TPMPosOfWMReq_sg_UB_ISig_4 : 59|1@1+ (1,0) [0|0] ""  VMCU
 SG_ TPMUnmateTrailerReq_ISig_4 : 44|2@1+ (1,0) [0|0] ""  VMCU
 SG_ TPMSetAxleRefPres_Axle4_ISig_4 : 24|8@1+ (10,0) [0|2550] "kPa"  VMCU
 SG_ TPMMateTrailerReq_UB_ISig_4 : 43|1@1+ (1,0) [0|0] ""  VMCU
 SG_ TPMSetAxleRefPres_sg_UB_ISig_4 : 60|1@1+ (1,0) [0|0] ""  VMCU
 SG_ TPMPosOfWMReq_VehiclePos_ISig_4 : 56|3@1+ (1,0) [0|0] ""  VMCU
 SG_ TPMSetAxleRefPres_Axle1_ISig_4 : 0|8@1+ (10,0) [0|2550] "kPa"  VMCU
 SG_ TPMSetAxleRefPres_Axle2_ISig_4 : 8|8@1+ (10,0) [0|2550] "kPa"  VMCU
 SG_ TPMSetAxleRefPres_Axle3_ISig_4 : 16|8@1+ (10,0) [0|2550] "kPa"  VMCU
 SG_ TPMMateTrailerReq_ISig_4 : 46|2@1+ (1,0) [0|0] ""  VMCU
 SG_ TPMPosOfWMReq_TireId_ISig_4 : 48|8@1+ (1,0) [0|255] "NotApplicable"  VMCU
 SG_ TPMUnmateTrailerReq_UB_ISig_4 : 61|1@1+ (1,0) [0|0] ""  VMCU
 SG_ TPMSetAxleRefPres_Axle5_ISig_4 : 32|8@1+ (10,0) [0|2550] "kPa"  VMCU
 SG_ TPMSetAxleRefPres_VehiclePos_ISi : 40|3@1+ (1,0) [0|0] ""  VMCU

CM_ SG_ 2515473944 AvailableGearsWithLowerRatio_ISi "14 Error ; 15 Not available";
CM_ SG_ 2515473944 ClutchWearStatus "254 Error ; 255 Not available";
CM_ SG_ 2515473944 AvailableGearsWithHigherRatio_IS "14 Error ; 15 Not available";
CM_ SG_ 2432636184 RoadInclination_ISig_4 "254 Error ; 255 Not available";
CM_ BO_ 2365530173 "Request to reserve CANid from Powertrain (ACM ECU)";
CM_ BO_ 2365530429 "Request to reserve CANid from Powertrain (ACM ECU)";
CM_ SG_ 2566635616 FasLowSpeedReturnSetting_rqst_IS "21-29 spare
30 Error
31 NotAvailbale";
CM_ SG_ 2566635616 FasManualOffsetSetting_rqst_ISig "21-29 spare
30 Error
31 NotAvailbale";
CM_ SG_ 2566635616 FasStiffnessCurveSetting_rqst_IS "21-29 spare
30 Error
31 NotAvailbale";
CM_ SG_ 2566635616 FasStiffStraightSetting_rqst_ISi "21-29 spare
30 Error
31 NotAvailbale";
CM_ SG_ 2566635616 FasDampingSetting_rqst_ISig_4 "21-29 spare
30 Error
31 NotAvailbale";
BA_DEF_ BO_  "GenMsgStartDelayTime" INT 0 0;
BA_DEF_ BO_  "GenMsgDelayTime" INT 0 0;
BA_DEF_ BO_  "GenMsgCycleTime" INT 0 0;
BA_DEF_ BO_  "GenMsgSendType" ENUM  "Cyclic","NotUsed","NotUsed","NotUsed","NotUsed","NotUsed","NotUsed","IfActive","NoMsgSendType","NotUsed";
BA_DEF_ SG_  "GenSigStartValue" INT 0 0;
BA_DEF_ SG_  "GenSigCycleTimeActive" INT 0 0;
BA_DEF_ SG_  "GenSigCycleTime" INT 0 0;
BA_DEF_ SG_  "GenSigSendType" ENUM  "Cyclic","OnWrite","OnWriteWithRepetition","OnChange","OnChangeWithRepetition","IfActive","IfActiveWithRepetition","NoSigSendType","NotUsed","NotUsed","NotUsed","NotUsed","NotUsed";
BA_DEF_ BO_  "VFrameFormat" ENUM  "StandardCAN","ExtendedCAN","reserved","J1939PG";
BA_DEF_ SG_  "SigType" ENUM  "Default","Range","RangeSigned","ASCII","Discrete","Control","ReferencePGN","DTC","StringDelimiter","StringLength","StringLengthControl";
BA_DEF_ SG_  "SeToolVersion_SIGNAL" STRING ;
BA_DEF_ SG_  "SeToolUniqueID_SIGNAL" STRING ;
BA_DEF_ SG_  "SeToolOwnerSigGroup_SIGNAL" STRING ;
BA_DEF_ SG_  "SeToolOwnerSigGroupID_SIGNAL" STRING ;
BA_DEF_ SG_  "SeToolName_SIGNAL" STRING ;
BA_DEF_ SG_  "SeToolItemID_SIGNAL" STRING ;
BA_DEF_ SG_  "SeToolAncestorID_SIGNAL" STRING ;
BA_DEF_ SG_  "Platform_VMCU1_Sig" ENUM  "No","Yes";
BA_DEF_ BO_  "NmAsrMessage" ENUM  "No","Yes";
BA_DEF_ SG_  "NeedsUpdateBit" ENUM  "No","Yes";
BA_DEF_ SG_  "MmAnSignal" ENUM  "No","Yes";
BA_DEF_ SG_  "GenSigMaxLatency" INT 0 65535;
BA_DEF_ SG_  "GenSigILSupport" ENUM  "Yes","No";
BA_DEF_ BO_  "GenMsgRequestable" INT 0 1;
BA_DEF_ BO_  "GenMsgILSupport" ENUM  "No","Yes";
BA_DEF_ BO_  "DiagUUDTResponse" ENUM  "No","Yes";
BA_DEF_ BO_  "DiagState" ENUM  "No","Yes";
BA_DEF_ BO_  "DiagResponse" ENUM  "No","Yes";
BA_DEF_ BO_  "DiagRequest" ENUM  "No","Yes";
BA_DEF_ BO_  "DiagConnection" HEX 0 65535;
BA_DEF_ BO_  "CanTpSTmin" INT 0 255;
BA_DEF_ BO_  "CanTpFcFrameId" HEX 0 2147483647;
BA_DEF_ BO_  "CanTpBs" INT 0 255;
BA_DEF_ SG_  "SystemSignalLongSymbol" STRING ;
BA_DEF_REL_ BU_SG_REL_  "GenSigTimeoutTime" INT 0 65535;
BA_DEF_REL_ BU_SG_REL_  "GenSigFirstTimeoutTime" INT 0 65535;
BA_DEF_DEF_  "GenMsgStartDelayTime" 0;
BA_DEF_DEF_  "GenMsgDelayTime" 0;
BA_DEF_DEF_  "GenMsgCycleTime" 0;
BA_DEF_DEF_  "GenMsgSendType" "Cyclic";
BA_DEF_DEF_  "GenSigStartValue" 0;
BA_DEF_DEF_  "GenSigCycleTimeActive" 0;
BA_DEF_DEF_  "GenSigCycleTime" 0;
BA_DEF_DEF_  "GenSigSendType" "Cyclic";
BA_DEF_DEF_  "VFrameFormat" "ExtendedCAN";
BA_DEF_DEF_  "SigType" "Default";
BA_DEF_DEF_  "SeToolVersion_SIGNAL" "";
BA_DEF_DEF_  "SeToolUniqueID_SIGNAL" "";
BA_DEF_DEF_  "SeToolOwnerSigGroup_SIGNAL" "";
BA_DEF_DEF_  "SeToolOwnerSigGroupID_SIGNAL" "";
BA_DEF_DEF_  "SeToolName_SIGNAL" "";
BA_DEF_DEF_  "SeToolItemID_SIGNAL" "";
BA_DEF_DEF_  "SeToolAncestorID_SIGNAL" "";
BA_DEF_DEF_  "Platform_VMCU1_Sig" "No";
BA_DEF_DEF_  "NmAsrMessage" "No";
BA_DEF_DEF_  "NeedsUpdateBit" "No";
BA_DEF_DEF_  "MmAnSignal" "No";
BA_DEF_DEF_  "GenSigMaxLatency" 0;
BA_DEF_DEF_  "GenSigILSupport" "Yes";
BA_DEF_DEF_  "GenMsgRequestable" 1;
BA_DEF_DEF_  "GenMsgILSupport" "Yes";
BA_DEF_DEF_  "DiagUUDTResponse" "No";
BA_DEF_DEF_  "DiagState" "No";
BA_DEF_DEF_  "DiagResponse" "No";
BA_DEF_DEF_  "DiagRequest" "No";
BA_DEF_DEF_  "DiagConnection" 0;
BA_DEF_DEF_  "CanTpSTmin" 0;
BA_DEF_DEF_  "CanTpFcFrameId" 2147483647;
BA_DEF_DEF_  "CanTpBs" 255;
BA_DEF_DEF_REL_ "GenSigTimeoutTime" 0;
BA_DEF_DEF_REL_ "GenSigFirstTimeoutTime" 0;
BA_DEF_DEF_  "SystemSignalLongSymbol" "";
BA_ "GenMsgCycleTime" BO_ 2432645412 25;
BA_ "GenMsgStartDelayTime" BO_ 2432645412 10;
BA_ "GenMsgCycleTime" BO_ 2432638500 20;
BA_ "GenMsgCycleTime" BO_ 2511149823 100;
BA_ "DiagConnection" BO_ 2671902706 62182;
BA_ "DiagState" BO_ 2671902706 1;
BA_ "GenMsgILSupport" BO_ 2671902706 0;
BA_ "GenMsgSendType" BO_ 2671902706 8;
BA_ "GenMsgILSupport" BO_ 2566356992 0;
BA_ "GenMsgSendType" BO_ 2566356992 8;
BA_ "CanTpFcFrameId" BO_ 2566356991 418873344;
BA_ "GenMsgSendType" BO_ 2566356991 8;
BA_ "GenMsgDelayTime" BO_ 2566356991 110;
BA_ "GenMsgStartDelayTime" BO_ 2566356991 50;
BA_ "GenMsgILSupport" BO_ 2499794048 0;
BA_ "GenMsgSendType" BO_ 2499794048 8;
BA_ "CanTpFcFrameId" BO_ 2499794047 352310400;
BA_ "GenMsgSendType" BO_ 2499794047 8;
BA_ "GenMsgDelayTime" BO_ 2499794047 20;
BA_ "CanTpSTmin" BO_ 2583412505 5;
BA_ "GenMsgILSupport" BO_ 2583412505 0;
BA_ "GenMsgSendType" BO_ 2583412505 8;
BA_ "CanTpFcFrameId" BO_ 2583412504 435928857;
BA_ "CanTpSTmin" BO_ 2583412504 5;
BA_ "GenMsgSendType" BO_ 2583412504 8;
BA_ "GenMsgDelayTime" BO_ 2583412504 2290;
BA_ "GenMsgStartDelayTime" BO_ 2583412504 50;
BA_ "GenMsgCycleTime" BO_ 2549028632 500;
BA_ "GenMsgStartDelayTime" BO_ 2549028632 100;
BA_ "GenMsgCycleTime" BO_ 2515473944 100;
BA_ "GenMsgStartDelayTime" BO_ 2515473944 10;
BA_ "GenMsgCycleTime" BO_ 2432636184 25;
BA_ "GenMsgStartDelayTime" BO_ 2432636184 5;
BA_ "DiagConnection" BO_ 2671833830 62182;
BA_ "DiagResponse" BO_ 2671833830 1;
BA_ "GenMsgILSupport" BO_ 2671833830 0;
BA_ "GenMsgSendType" BO_ 2671833830 8;
BA_ "DiagConnection" BO_ 2671833829 62181;
BA_ "DiagResponse" BO_ 2671833829 1;
BA_ "GenMsgILSupport" BO_ 2671833829 0;
BA_ "GenMsgSendType" BO_ 2671833829 8;
BA_ "DiagConnection" BO_ 2671833792 62144;
BA_ "DiagResponse" BO_ 2671833792 1;
BA_ "GenMsgILSupport" BO_ 2671833792 0;
BA_ "GenMsgSendType" BO_ 2671833792 8;
BA_ "DiagConnection" BO_ 2671833762 62114;
BA_ "DiagResponse" BO_ 2671833762 1;
BA_ "GenMsgILSupport" BO_ 2671833762 0;
BA_ "GenMsgSendType" BO_ 2671833762 8;
BA_ "DiagConnection" BO_ 2671833761 62113;
BA_ "DiagResponse" BO_ 2671833761 1;
BA_ "GenMsgILSupport" BO_ 2671833761 0;
BA_ "GenMsgSendType" BO_ 2671833761 8;
BA_ "DiagConnection" BO_ 2671833760 62112;
BA_ "DiagResponse" BO_ 2671833760 1;
BA_ "GenMsgILSupport" BO_ 2671833760 0;
BA_ "GenMsgSendType" BO_ 2671833760 8;
BA_ "DiagConnection" BO_ 2671833752 62104;
BA_ "DiagResponse" BO_ 2671833752 1;
BA_ "GenMsgILSupport" BO_ 2671833752 0;
BA_ "GenMsgSendType" BO_ 2671833752 8;
BA_ "DiagConnection" BO_ 2671833730 62082;
BA_ "DiagResponse" BO_ 2671833730 1;
BA_ "GenMsgILSupport" BO_ 2671833730 0;
BA_ "GenMsgSendType" BO_ 2671833730 8;
BA_ "DiagConnection" BO_ 2671833728 62080;
BA_ "DiagResponse" BO_ 2671833728 1;
BA_ "GenMsgILSupport" BO_ 2671833728 0;
BA_ "GenMsgSendType" BO_ 2671833728 8;
BA_ "DiagConnection" BO_ 2671833699 62051;
BA_ "DiagResponse" BO_ 2671833699 1;
BA_ "GenMsgILSupport" BO_ 2671833699 0;
BA_ "GenMsgSendType" BO_ 2671833699 8;
BA_ "DiagConnection" BO_ 2671833698 62050;
BA_ "DiagResponse" BO_ 2671833698 1;
BA_ "GenMsgILSupport" BO_ 2671833698 0;
BA_ "GenMsgSendType" BO_ 2671833698 8;
BA_ "DiagConnection" BO_ 2671833697 62049;
BA_ "DiagResponse" BO_ 2671833697 1;
BA_ "GenMsgILSupport" BO_ 2671833697 0;
BA_ "GenMsgSendType" BO_ 2671833697 8;
BA_ "DiagConnection" BO_ 2671833696 62048;
BA_ "DiagResponse" BO_ 2671833696 1;
BA_ "GenMsgILSupport" BO_ 2671833696 0;
BA_ "GenMsgSendType" BO_ 2671833696 8;
BA_ "DiagConnection" BO_ 2671833683 62035;
BA_ "DiagResponse" BO_ 2671833683 1;
BA_ "GenMsgILSupport" BO_ 2671833683 0;
BA_ "GenMsgSendType" BO_ 2671833683 8;
BA_ "DiagConnection" BO_ 2671833682 62034;
BA_ "DiagResponse" BO_ 2671833682 1;
BA_ "GenMsgILSupport" BO_ 2671833682 0;
BA_ "GenMsgSendType" BO_ 2671833682 8;
BA_ "DiagConnection" BO_ 2671833681 62033;
BA_ "DiagResponse" BO_ 2671833681 1;
BA_ "GenMsgILSupport" BO_ 2671833681 0;
BA_ "GenMsgSendType" BO_ 2671833681 8;
BA_ "DiagConnection" BO_ 2671833680 62032;
BA_ "DiagResponse" BO_ 2671833680 1;
BA_ "GenMsgILSupport" BO_ 2671833680 0;
BA_ "GenMsgSendType" BO_ 2671833680 8;
BA_ "DiagConnection" BO_ 2671833665 62017;
BA_ "DiagResponse" BO_ 2671833665 1;
BA_ "GenMsgILSupport" BO_ 2671833665 0;
BA_ "GenMsgSendType" BO_ 2671833665 8;
BA_ "DiagConnection" BO_ 2671833664 62016;
BA_ "DiagResponse" BO_ 2671833664 1;
BA_ "GenMsgILSupport" BO_ 2671833664 0;
BA_ "GenMsgSendType" BO_ 2671833664 8;
BA_ "DiagConnection" BO_ 2671833638 61990;
BA_ "DiagResponse" BO_ 2671833638 1;
BA_ "GenMsgILSupport" BO_ 2671833638 0;
BA_ "GenMsgSendType" BO_ 2671833638 8;
BA_ "DiagConnection" BO_ 2671833624 61976;
BA_ "DiagResponse" BO_ 2671833624 1;
BA_ "GenMsgILSupport" BO_ 2671833624 0;
BA_ "GenMsgSendType" BO_ 2671833624 8;
BA_ "DiagConnection" BO_ 2671833616 61968;
BA_ "DiagResponse" BO_ 2671833616 1;
BA_ "GenMsgILSupport" BO_ 2671833616 0;
BA_ "GenMsgSendType" BO_ 2671833616 8;
BA_ "DiagConnection" BO_ 2564485459 61779;
BA_ "DiagResponse" BO_ 2564485459 1;
BA_ "GenMsgILSupport" BO_ 2564485459 0;
BA_ "GenMsgSendType" BO_ 2564485459 8;
BA_ "DiagConnection" BO_ 2564485392 63504;
BA_ "DiagResponse" BO_ 2564485392 1;
BA_ "GenMsgILSupport" BO_ 2564485392 0;
BA_ "GenMsgSendType" BO_ 2564485392 8;
BA_ "DiagConnection" BO_ 2671833360 61712;
BA_ "DiagResponse" BO_ 2671833360 1;
BA_ "GenMsgILSupport" BO_ 2671833360 0;
BA_ "GenMsgSendType" BO_ 2671833360 8;
BA_ "DiagConnection" BO_ 2671830770 62182;
BA_ "DiagRequest" BO_ 2671830770 1;
BA_ "GenMsgILSupport" BO_ 2671830770 0;
BA_ "GenMsgSendType" BO_ 2671830770 8;
BA_ "DiagConnection" BO_ 2671830514 62181;
BA_ "DiagRequest" BO_ 2671830514 1;
BA_ "GenMsgILSupport" BO_ 2671830514 0;
BA_ "GenMsgSendType" BO_ 2671830514 8;
BA_ "DiagConnection" BO_ 2671821042 62144;
BA_ "DiagRequest" BO_ 2671821042 1;
BA_ "GenMsgILSupport" BO_ 2671821042 0;
BA_ "GenMsgSendType" BO_ 2671821042 8;
BA_ "DiagConnection" BO_ 2671813362 62114;
BA_ "DiagRequest" BO_ 2671813362 1;
BA_ "GenMsgILSupport" BO_ 2671813362 0;
BA_ "GenMsgSendType" BO_ 2671813362 8;
BA_ "DiagConnection" BO_ 2671813106 62113;
BA_ "DiagRequest" BO_ 2671813106 1;
BA_ "GenMsgILSupport" BO_ 2671813106 0;
BA_ "GenMsgSendType" BO_ 2671813106 8;
BA_ "DiagConnection" BO_ 2671812850 62112;
BA_ "DiagRequest" BO_ 2671812850 1;
BA_ "GenMsgILSupport" BO_ 2671812850 0;
BA_ "GenMsgSendType" BO_ 2671812850 8;
BA_ "DiagConnection" BO_ 2671810802 62104;
BA_ "DiagRequest" BO_ 2671810802 1;
BA_ "GenMsgILSupport" BO_ 2671810802 0;
BA_ "GenMsgSendType" BO_ 2671810802 8;
BA_ "DiagConnection" BO_ 2671805170 62082;
BA_ "DiagRequest" BO_ 2671805170 1;
BA_ "GenMsgILSupport" BO_ 2671805170 0;
BA_ "GenMsgSendType" BO_ 2671805170 8;
BA_ "DiagConnection" BO_ 2671804658 62080;
BA_ "DiagRequest" BO_ 2671804658 1;
BA_ "GenMsgILSupport" BO_ 2671804658 0;
BA_ "GenMsgSendType" BO_ 2671804658 8;
BA_ "DiagConnection" BO_ 2671797234 62051;
BA_ "DiagRequest" BO_ 2671797234 1;
BA_ "GenMsgILSupport" BO_ 2671797234 0;
BA_ "GenMsgSendType" BO_ 2671797234 8;
BA_ "DiagConnection" BO_ 2671796978 62050;
BA_ "DiagRequest" BO_ 2671796978 1;
BA_ "GenMsgILSupport" BO_ 2671796978 0;
BA_ "GenMsgSendType" BO_ 2671796978 8;
BA_ "DiagConnection" BO_ 2671796722 62049;
BA_ "DiagRequest" BO_ 2671796722 1;
BA_ "GenMsgILSupport" BO_ 2671796722 0;
BA_ "GenMsgSendType" BO_ 2671796722 8;
BA_ "DiagConnection" BO_ 2671796466 62048;
BA_ "DiagRequest" BO_ 2671796466 1;
BA_ "GenMsgILSupport" BO_ 2671796466 0;
BA_ "GenMsgSendType" BO_ 2671796466 8;
BA_ "DiagConnection" BO_ 2671793138 62035;
BA_ "DiagRequest" BO_ 2671793138 1;
BA_ "GenMsgILSupport" BO_ 2671793138 0;
BA_ "GenMsgSendType" BO_ 2671793138 8;
BA_ "DiagConnection" BO_ 2564445169 61779;
BA_ "DiagRequest" BO_ 2564445169 1;
BA_ "GenMsgILSupport" BO_ 2564445169 0;
BA_ "GenMsgSendType" BO_ 2564445169 8;
BA_ "DiagConnection" BO_ 2671792882 62034;
BA_ "DiagRequest" BO_ 2671792882 1;
BA_ "GenMsgILSupport" BO_ 2671792882 0;
BA_ "GenMsgSendType" BO_ 2671792882 8;
BA_ "DiagConnection" BO_ 2671792626 62033;
BA_ "DiagRequest" BO_ 2671792626 1;
BA_ "GenMsgILSupport" BO_ 2671792626 0;
BA_ "GenMsgSendType" BO_ 2671792626 8;
BA_ "DiagConnection" BO_ 2671792370 62032;
BA_ "DiagRequest" BO_ 2671792370 1;
BA_ "GenMsgILSupport" BO_ 2671792370 0;
BA_ "GenMsgSendType" BO_ 2671792370 8;
BA_ "DiagConnection" BO_ 2671788530 62017;
BA_ "DiagRequest" BO_ 2671788530 1;
BA_ "GenMsgILSupport" BO_ 2671788530 0;
BA_ "GenMsgSendType" BO_ 2671788530 8;
BA_ "DiagConnection" BO_ 2671788274 62016;
BA_ "DiagRequest" BO_ 2671788274 1;
BA_ "GenMsgILSupport" BO_ 2671788274 0;
BA_ "GenMsgSendType" BO_ 2671788274 8;
BA_ "DiagConnection" BO_ 2671781618 61990;
BA_ "DiagRequest" BO_ 2671781618 1;
BA_ "GenMsgILSupport" BO_ 2671781618 0;
BA_ "GenMsgSendType" BO_ 2671781618 8;
BA_ "DiagConnection" BO_ 2671778034 61976;
BA_ "DiagRequest" BO_ 2671778034 1;
BA_ "GenMsgILSupport" BO_ 2671778034 0;
BA_ "GenMsgSendType" BO_ 2671778034 8;
BA_ "DiagConnection" BO_ 2671775986 61968;
BA_ "DiagRequest" BO_ 2671775986 1;
BA_ "GenMsgILSupport" BO_ 2671775986 0;
BA_ "GenMsgSendType" BO_ 2671775986 8;
BA_ "DiagConnection" BO_ 2564428017 63504;
BA_ "DiagRequest" BO_ 2564428017 1;
BA_ "GenMsgILSupport" BO_ 2564428017 0;
BA_ "GenMsgSendType" BO_ 2564428017 8;
BA_ "DiagConnection" BO_ 2671775985 61712;
BA_ "DiagRequest" BO_ 2671775985 1;
BA_ "GenMsgILSupport" BO_ 2671775985 0;
BA_ "GenMsgSendType" BO_ 2671775985 8;
BA_ "DiagConnection" BO_ 2564502513 63504;
BA_ "DiagState" BO_ 2564502513 1;
BA_ "GenMsgILSupport" BO_ 2564502513 0;
BA_ "GenMsgSendType" BO_ 2564502513 8;
BA_ "DiagConnection" BO_ 2671850481 61712;
BA_ "DiagState" BO_ 2671850481 1;
BA_ "GenMsgILSupport" BO_ 2671850481 0;
BA_ "GenMsgSendType" BO_ 2671850481 8;
BA_ "GenMsgILSupport" BO_ 2633990180 0;
BA_ "NmAsrMessage" BO_ 2633990180 1;
BA_ "GenMsgSendType" BO_ 2633990180 8;
BA_ "GenMsgILSupport" BO_ 2633990168 0;
BA_ "NmAsrMessage" BO_ 2633990168 1;
BA_ "GenMsgSendType" BO_ 2633990168 8;
BA_ "GenMsgILSupport" BO_ 2633990240 0;
BA_ "NmAsrMessage" BO_ 2633990240 1;
BA_ "GenMsgSendType" BO_ 2633990240 8;
BA_ "GenMsgILSupport" BO_ 2633990160 0;
BA_ "NmAsrMessage" BO_ 2633990160 1;
BA_ "GenMsgSendType" BO_ 2633990160 8;
BA_ "GenMsgILSupport" BO_ 2633990224 0;
BA_ "NmAsrMessage" BO_ 2633990224 1;
BA_ "GenMsgSendType" BO_ 2633990224 8;
BA_ "GenMsgILSupport" BO_ 2633990208 0;
BA_ "NmAsrMessage" BO_ 2633990208 1;
BA_ "GenMsgSendType" BO_ 2633990208 8;
BA_ "GenMsgILSupport" BO_ 2633990374 0;
BA_ "NmAsrMessage" BO_ 2633990374 1;
BA_ "GenMsgSendType" BO_ 2633990374 8;
BA_ "DiagConnection" BO_ 2671902708 62468;
BA_ "DiagState" BO_ 2671902708 1;
BA_ "GenMsgILSupport" BO_ 2671902708 0;
BA_ "GenMsgSendType" BO_ 2671902708 8;
BA_ "CanTpSTmin" BO_ 2582855521 5;
BA_ "GenMsgILSupport" BO_ 2582855521 0;
BA_ "GenMsgSendType" BO_ 2582855521 8;
BA_ "GenMsgCycleTime" BO_ 2566635616 1000;
BA_ "GenMsgStartDelayTime" BO_ 2566635616 50;
BA_ "GenMsgCycleTime" BO_ 2566635360 100;
BA_ "GenMsgStartDelayTime" BO_ 2566635360 50;
BA_ "GenMsgSendType" BO_ 2432637476 8;
BA_ "GenMsgDelayTime" BO_ 2432637476 20;
BA_ "GenMsgILSupport" BO_ 2566357089 0;
BA_ "GenMsgSendType" BO_ 2566357089 8;
BA_ "CanTpFcFrameId" BO_ 2566357088 418873441;
BA_ "GenMsgSendType" BO_ 2566357088 8;
BA_ "GenMsgDelayTime" BO_ 2566357088 150;
BA_ "GenMsgILSupport" BO_ 2499772257 0;
BA_ "GenMsgSendType" BO_ 2499772257 8;
BA_ "CanTpFcFrameId" BO_ 2499772256 352288609;
BA_ "GenMsgSendType" BO_ 2499772256 8;
BA_ "GenMsgDelayTime" BO_ 2499772256 100;
BA_ "GenMsgSendType" BO_ 2499788640 8;
BA_ "GenMsgDelayTime" BO_ 2499788640 50;
BA_ "GenMsgCycleTime" BO_ 2477212768 50;
BA_ "GenMsgCycleTime" BO_ 2565816160 500;
BA_ "GenMsgStartDelayTime" BO_ 2565816160 75;
BA_ "GenMsgCycleTime" BO_ 2565848928 500;
BA_ "GenMsgStartDelayTime" BO_ 2565848928 65;
BA_ "GenMsgCycleTime" BO_ 2565494624 500;
BA_ "GenMsgStartDelayTime" BO_ 2565494624 120;
BA_ "GenSigSendType" SG_ 2432645412 LevelControlInformation_UB_ISig_ 7;
BA_ "Platform_VMCU1_Sig" SG_ 2432645412 LevelControlInformation_UB_ISig_ 1;
BA_ "SystemSignalLongSymbol" SG_ 2432645412 LevelControlInformation_UB_ISig_ "LevelControlInformation_UB_ISig_4";
BA_ "GenSigCycleTime" SG_ 2432645412 LiftAxle2LiftFuncSelected_ISig_4 100;
BA_ "GenSigCycleTimeActive" SG_ 2432645412 LiftAxle2LiftFuncSelected_ISig_4 100;
BA_ "GenSigStartValue" SG_ 2432645412 LiftAxle2LiftFuncSelected_ISig_4 7;
BA_ "GenSigMaxLatency" SG_ 2432645412 LiftAxle2LiftFuncSelected_ISig_4 28;
BA_ "Platform_VMCU1_Sig" SG_ 2432645412 LiftAxle2LiftFuncSelected_ISig_4 1;
BA_ "SeToolAncestorID_SIGNAL" SG_ 2432645412 LiftAxle2LiftFuncSelected_ISig_4 "x0000001D04134C4B";
BA_ "SeToolItemID_SIGNAL" SG_ 2432645412 LiftAxle2LiftFuncSelected_ISig_4 "x0000001D04134C4B";
BA_ "SeToolName_SIGNAL" SG_ 2432645412 LiftAxle2LiftFuncSelected_ISig_4 "LiftAxle2LiftAutoFunctionSelected";
BA_ "SeToolVersion_SIGNAL" SG_ 2432645412 LiftAxle2LiftFuncSelected_ISig_4 "1";
BA_ "GenSigCycleTime" SG_ 2432645412 StopLevelChangeAck_ISig_4 100;
BA_ "GenSigCycleTimeActive" SG_ 2432645412 StopLevelChangeAck_ISig_4 100;
BA_ "GenSigStartValue" SG_ 2432645412 StopLevelChangeAck_ISig_4 3;
BA_ "GenSigMaxLatency" SG_ 2432645412 StopLevelChangeAck_ISig_4 28;
BA_ "Platform_VMCU1_Sig" SG_ 2432645412 StopLevelChangeAck_ISig_4 1;
BA_ "SeToolAncestorID_SIGNAL" SG_ 2432645412 StopLevelChangeAck_ISig_4 "x0000001D0412ECBE";
BA_ "SeToolItemID_SIGNAL" SG_ 2432645412 StopLevelChangeAck_ISig_4 "x0000001D0412ECBE";
BA_ "SeToolName_SIGNAL" SG_ 2432645412 StopLevelChangeAck_ISig_4 "StopLevelChangeAck";
BA_ "SeToolVersion_SIGNAL" SG_ 2432645412 StopLevelChangeAck_ISig_4 "1";
BA_ "GenSigCycleTime" SG_ 2432645412 HeightAdjustmentAllowed_ISig_4 100;
BA_ "GenSigCycleTimeActive" SG_ 2432645412 HeightAdjustmentAllowed_ISig_4 100;
BA_ "GenSigStartValue" SG_ 2432645412 HeightAdjustmentAllowed_ISig_4 3;
BA_ "Platform_VMCU1_Sig" SG_ 2432645412 HeightAdjustmentAllowed_ISig_4 1;
BA_ "GenSigCycleTime" SG_ 2432645412 LiftAxle2UpRequestACK_ISig_4 100;
BA_ "GenSigCycleTimeActive" SG_ 2432645412 LiftAxle2UpRequestACK_ISig_4 100;
BA_ "GenSigStartValue" SG_ 2432645412 LiftAxle2UpRequestACK_ISig_4 7;
BA_ "GenSigMaxLatency" SG_ 2432645412 LiftAxle2UpRequestACK_ISig_4 28;
BA_ "Platform_VMCU1_Sig" SG_ 2432645412 LiftAxle2UpRequestACK_ISig_4 1;
BA_ "SeToolAncestorID_SIGNAL" SG_ 2432645412 LiftAxle2UpRequestACK_ISig_4 "x0000001D043E0E16";
BA_ "SeToolItemID_SIGNAL" SG_ 2432645412 LiftAxle2UpRequestACK_ISig_4 "x0000001D043E0E16";
BA_ "SeToolName_SIGNAL" SG_ 2432645412 LiftAxle2UpRequestACK_ISig_4 "LiftAxle2UpRequestACK";
BA_ "SeToolVersion_SIGNAL" SG_ 2432645412 LiftAxle2UpRequestACK_ISig_4 "1";
BA_ "GenSigCycleTime" SG_ 2432645412 RideHeightStatus_ISig_4 100;
BA_ "GenSigCycleTimeActive" SG_ 2432645412 RideHeightStatus_ISig_4 100;
BA_ "GenSigStartValue" SG_ 2432645412 RideHeightStatus_ISig_4 15;
BA_ "GenSigMaxLatency" SG_ 2432645412 RideHeightStatus_ISig_4 28;
BA_ "Platform_VMCU1_Sig" SG_ 2432645412 RideHeightStatus_ISig_4 1;
BA_ "SeToolAncestorID_SIGNAL" SG_ 2432645412 RideHeightStatus_ISig_4 "x0000001D041304DF";
BA_ "SeToolItemID_SIGNAL" SG_ 2432645412 RideHeightStatus_ISig_4 "x0000001D0442415B";
BA_ "SeToolName_SIGNAL" SG_ 2432645412 RideHeightStatus_ISig_4 "RideHeightStatus";
BA_ "SeToolVersion_SIGNAL" SG_ 2432645412 RideHeightStatus_ISig_4 "3";
BA_ "GenSigCycleTime" SG_ 2432645412 RideHeightOutsideTargetRange_ISi 100;
BA_ "GenSigCycleTimeActive" SG_ 2432645412 RideHeightOutsideTargetRange_ISi 100;
BA_ "GenSigStartValue" SG_ 2432645412 RideHeightOutsideTargetRange_ISi 7;
BA_ "GenSigMaxLatency" SG_ 2432645412 RideHeightOutsideTargetRange_ISi 28;
BA_ "Platform_VMCU1_Sig" SG_ 2432645412 RideHeightOutsideTargetRange_ISi 1;
BA_ "SeToolAncestorID_SIGNAL" SG_ 2432645412 RideHeightOutsideTargetRange_ISi "x0000001D041F15D9";
BA_ "SeToolItemID_SIGNAL" SG_ 2432645412 RideHeightOutsideTargetRange_ISi "x0000001D041F15D9";
BA_ "SeToolName_SIGNAL" SG_ 2432645412 RideHeightOutsideTargetRange_ISi "RideHeightOutsideTargetRange";
BA_ "SeToolVersion_SIGNAL" SG_ 2432645412 RideHeightOutsideTargetRange_ISi "1";
BA_ "SystemSignalLongSymbol" SG_ 2432645412 RideHeightOutsideTargetRange_ISi "RideHeightOutsideTargetRange_ISig_4";
BA_ "GenSigCycleTime" SG_ 2432645412 LoadDistributionFuncSelected_ISi 100;
BA_ "GenSigCycleTimeActive" SG_ 2432645412 LoadDistributionFuncSelected_ISi 100;
BA_ "GenSigStartValue" SG_ 2432645412 LoadDistributionFuncSelected_ISi 15;
BA_ "GenSigMaxLatency" SG_ 2432645412 LoadDistributionFuncSelected_ISi 28;
BA_ "Platform_VMCU1_Sig" SG_ 2432645412 LoadDistributionFuncSelected_ISi 1;
BA_ "SeToolAncestorID_SIGNAL" SG_ 2432645412 LoadDistributionFuncSelected_ISi "x0000001D04355313";
BA_ "SeToolItemID_SIGNAL" SG_ 2432645412 LoadDistributionFuncSelected_ISi "x0000001D043AB18A";
BA_ "SeToolName_SIGNAL" SG_ 2432645412 LoadDistributionFuncSelected_ISi "LoadDistributionRequested";
BA_ "SeToolVersion_SIGNAL" SG_ 2432645412 LoadDistributionFuncSelected_ISi "2";
BA_ "SystemSignalLongSymbol" SG_ 2432645412 LoadDistributionFuncSelected_ISi "LoadDistributionFuncSelected_ISig_4";
BA_ "GenSigCycleTime" SG_ 2432645412 RideHeightStorageAck_ISig_4 100;
BA_ "GenSigCycleTimeActive" SG_ 2432645412 RideHeightStorageAck_ISig_4 100;
BA_ "GenSigStartValue" SG_ 2432645412 RideHeightStorageAck_ISig_4 3;
BA_ "GenSigMaxLatency" SG_ 2432645412 RideHeightStorageAck_ISig_4 28;
BA_ "Platform_VMCU1_Sig" SG_ 2432645412 RideHeightStorageAck_ISig_4 1;
BA_ "SeToolAncestorID_SIGNAL" SG_ 2432645412 RideHeightStorageAck_ISig_4 "x0000001D0421D044";
BA_ "SeToolItemID_SIGNAL" SG_ 2432645412 RideHeightStorageAck_ISig_4 "x0000001D0421D044";
BA_ "SeToolName_SIGNAL" SG_ 2432645412 RideHeightStorageAck_ISig_4 "RideHeightStorageAck";
BA_ "SeToolVersion_SIGNAL" SG_ 2432645412 RideHeightStorageAck_ISig_4 "1";
BA_ "GenSigCycleTime" SG_ 2432645412 LiftAxle2LowerACK_ISig_4 100;
BA_ "GenSigCycleTimeActive" SG_ 2432645412 LiftAxle2LowerACK_ISig_4 100;
BA_ "GenSigStartValue" SG_ 2432645412 LiftAxle2LowerACK_ISig_4 7;
BA_ "Platform_VMCU1_Sig" SG_ 2432645412 LiftAxle2LowerACK_ISig_4 1;
BA_ "GenSigCycleTime" SG_ 2432645412 LiftAxle1UpRequestACK_ISig_4 100;
BA_ "GenSigCycleTimeActive" SG_ 2432645412 LiftAxle1UpRequestACK_ISig_4 100;
BA_ "GenSigStartValue" SG_ 2432645412 LiftAxle1UpRequestACK_ISig_4 7;
BA_ "GenSigMaxLatency" SG_ 2432645412 LiftAxle1UpRequestACK_ISig_4 28;
BA_ "Platform_VMCU1_Sig" SG_ 2432645412 LiftAxle1UpRequestACK_ISig_4 1;
BA_ "SeToolAncestorID_SIGNAL" SG_ 2432645412 LiftAxle1UpRequestACK_ISig_4 "x0000001D043E0DFD";
BA_ "SeToolItemID_SIGNAL" SG_ 2432645412 LiftAxle1UpRequestACK_ISig_4 "x0000001D043E0DFD";
BA_ "SeToolName_SIGNAL" SG_ 2432645412 LiftAxle1UpRequestACK_ISig_4 "LiftAxle1UpRequestACK";
BA_ "SeToolVersion_SIGNAL" SG_ 2432645412 LiftAxle1UpRequestACK_ISig_4 "1";
BA_ "GenSigCycleTime" SG_ 2432645412 LiftAxle1PositionStatus_ISig_4 100;
BA_ "GenSigCycleTimeActive" SG_ 2432645412 LiftAxle1PositionStatus_ISig_4 100;
BA_ "GenSigStartValue" SG_ 2432645412 LiftAxle1PositionStatus_ISig_4 7;
BA_ "GenSigMaxLatency" SG_ 2432645412 LiftAxle1PositionStatus_ISig_4 28;
BA_ "Platform_VMCU1_Sig" SG_ 2432645412 LiftAxle1PositionStatus_ISig_4 1;
BA_ "SeToolAncestorID_SIGNAL" SG_ 2432645412 LiftAxle1PositionStatus_ISig_4 "x0000001D04131A08";
BA_ "SeToolItemID_SIGNAL" SG_ 2432645412 LiftAxle1PositionStatus_ISig_4 "x0000001D0423C412";
BA_ "SeToolName_SIGNAL" SG_ 2432645412 LiftAxle1PositionStatus_ISig_4 "LiftAxle1PositionStatus";
BA_ "SeToolVersion_SIGNAL" SG_ 2432645412 LiftAxle1PositionStatus_ISig_4 "2";
BA_ "GenSigCycleTime" SG_ 2432645412 LiftAxle2AutoLiftSelected_ISig_4 100;
BA_ "GenSigCycleTimeActive" SG_ 2432645412 LiftAxle2AutoLiftSelected_ISig_4 100;
BA_ "GenSigStartValue" SG_ 2432645412 LiftAxle2AutoLiftSelected_ISig_4 3;
BA_ "Platform_VMCU1_Sig" SG_ 2432645412 LiftAxle2AutoLiftSelected_ISig_4 1;
BA_ "GenSigCycleTime" SG_ 2432645412 LiftAxle1LowerACK_ISig_4 100;
BA_ "GenSigCycleTimeActive" SG_ 2432645412 LiftAxle1LowerACK_ISig_4 100;
BA_ "GenSigStartValue" SG_ 2432645412 LiftAxle1LowerACK_ISig_4 7;
BA_ "Platform_VMCU1_Sig" SG_ 2432645412 LiftAxle1LowerACK_ISig_4 1;
BA_ "GenSigCycleTime" SG_ 2432645412 LiftAxle2PositionStatus_ISig_4 100;
BA_ "GenSigCycleTimeActive" SG_ 2432645412 LiftAxle2PositionStatus_ISig_4 100;
BA_ "GenSigStartValue" SG_ 2432645412 LiftAxle2PositionStatus_ISig_4 7;
BA_ "GenSigMaxLatency" SG_ 2432645412 LiftAxle2PositionStatus_ISig_4 28;
BA_ "Platform_VMCU1_Sig" SG_ 2432645412 LiftAxle2PositionStatus_ISig_4 1;
BA_ "SeToolAncestorID_SIGNAL" SG_ 2432645412 LiftAxle2PositionStatus_ISig_4 "x0000001D04131A0A";
BA_ "SeToolItemID_SIGNAL" SG_ 2432645412 LiftAxle2PositionStatus_ISig_4 "x0000001D04295880";
BA_ "SeToolName_SIGNAL" SG_ 2432645412 LiftAxle2PositionStatus_ISig_4 "LiftAxle2PositionStatus";
BA_ "SeToolVersion_SIGNAL" SG_ 2432645412 LiftAxle2PositionStatus_ISig_4 "3";
BA_ "GenSigCycleTime" SG_ 2432645412 LevelControlInformation_ISig_4 100;
BA_ "GenSigCycleTimeActive" SG_ 2432645412 LevelControlInformation_ISig_4 100;
BA_ "GenSigStartValue" SG_ 2432645412 LevelControlInformation_ISig_4 15;
BA_ "GenSigMaxLatency" SG_ 2432645412 LevelControlInformation_ISig_4 28;
BA_ "NeedsUpdateBit" SG_ 2432645412 LevelControlInformation_ISig_4 1;
BA_ "Platform_VMCU1_Sig" SG_ 2432645412 LevelControlInformation_ISig_4 1;
BA_ "SeToolAncestorID_SIGNAL" SG_ 2432645412 LevelControlInformation_ISig_4 "x0000001D04290369";
BA_ "SeToolItemID_SIGNAL" SG_ 2432645412 LevelControlInformation_ISig_4 "x0000001D04290369";
BA_ "SeToolName_SIGNAL" SG_ 2432645412 LevelControlInformation_ISig_4 "LevelControlInformation";
BA_ "SeToolVersion_SIGNAL" SG_ 2432645412 LevelControlInformation_ISig_4 "1";
BA_ "GenSigCycleTime" SG_ 2432645412 LoadDistributionChangeACK_ISig_4 100;
BA_ "GenSigCycleTimeActive" SG_ 2432645412 LoadDistributionChangeACK_ISig_4 100;
BA_ "GenSigStartValue" SG_ 2432645412 LoadDistributionChangeACK_ISig_4 7;
BA_ "GenSigMaxLatency" SG_ 2432645412 LoadDistributionChangeACK_ISig_4 28;
BA_ "Platform_VMCU1_Sig" SG_ 2432645412 LoadDistributionChangeACK_ISig_4 1;
BA_ "SeToolAncestorID_SIGNAL" SG_ 2432645412 LoadDistributionChangeACK_ISig_4 "x0000001D04176D2D";
BA_ "SeToolItemID_SIGNAL" SG_ 2432645412 LoadDistributionChangeACK_ISig_4 "x0000001D0440C942";
BA_ "SeToolName_SIGNAL" SG_ 2432645412 LoadDistributionChangeACK_ISig_4 "LoadDistributionChangeAck";
BA_ "SeToolVersion_SIGNAL" SG_ 2432645412 LoadDistributionChangeACK_ISig_4 "2";
BA_ "GenSigCycleTime" SG_ 2432645412 LiftAxle1AutoLiftSelected_ISig_4 100;
BA_ "GenSigCycleTimeActive" SG_ 2432645412 LiftAxle1AutoLiftSelected_ISig_4 100;
BA_ "GenSigStartValue" SG_ 2432645412 LiftAxle1AutoLiftSelected_ISig_4 3;
BA_ "Platform_VMCU1_Sig" SG_ 2432645412 LiftAxle1AutoLiftSelected_ISig_4 1;
BA_ "GenSigCycleTime" SG_ 2432645412 LiftAxle1LiftFuncSelected_ISig_4 100;
BA_ "GenSigCycleTimeActive" SG_ 2432645412 LiftAxle1LiftFuncSelected_ISig_4 100;
BA_ "GenSigStartValue" SG_ 2432645412 LiftAxle1LiftFuncSelected_ISig_4 7;
BA_ "GenSigMaxLatency" SG_ 2432645412 LiftAxle1LiftFuncSelected_ISig_4 28;
BA_ "Platform_VMCU1_Sig" SG_ 2432645412 LiftAxle1LiftFuncSelected_ISig_4 1;
BA_ "SeToolAncestorID_SIGNAL" SG_ 2432645412 LiftAxle1LiftFuncSelected_ISig_4 "x0000001D04134C43";
BA_ "SeToolItemID_SIGNAL" SG_ 2432645412 LiftAxle1LiftFuncSelected_ISig_4 "x0000001D04134C43";
BA_ "SeToolName_SIGNAL" SG_ 2432645412 LiftAxle1LiftFuncSelected_ISig_4 "LiftAxle1LiftAutoFunctionSelected";
BA_ "SeToolVersion_SIGNAL" SG_ 2432645412 LiftAxle1LiftFuncSelected_ISig_4 "1";
BA_ "GenSigCycleTime" SG_ 2432645412 RampLevelStorageAck_ISig_4 100;
BA_ "GenSigCycleTimeActive" SG_ 2432645412 RampLevelStorageAck_ISig_4 100;
BA_ "GenSigStartValue" SG_ 2432645412 RampLevelStorageAck_ISig_4 3;
BA_ "GenSigMaxLatency" SG_ 2432645412 RampLevelStorageAck_ISig_4 28;
BA_ "Platform_VMCU1_Sig" SG_ 2432645412 RampLevelStorageAck_ISig_4 1;
BA_ "SeToolAncestorID_SIGNAL" SG_ 2432645412 RampLevelStorageAck_ISig_4 "x0000001D0421FE10";
BA_ "SeToolItemID_SIGNAL" SG_ 2432645412 RampLevelStorageAck_ISig_4 "x0000001D0421FE10";
BA_ "SeToolName_SIGNAL" SG_ 2432645412 RampLevelStorageAck_ISig_4 "RampLevelStorageAck";
BA_ "SeToolVersion_SIGNAL" SG_ 2432645412 RampLevelStorageAck_ISig_4 "1";
BA_ "GenSigCycleTime" SG_ 2432645412 LoadDistributionSelected_ISig_4 100;
BA_ "GenSigCycleTimeActive" SG_ 2432645412 LoadDistributionSelected_ISig_4 100;
BA_ "GenSigStartValue" SG_ 2432645412 LoadDistributionSelected_ISig_4 15;
BA_ "GenSigMaxLatency" SG_ 2432645412 LoadDistributionSelected_ISig_4 112;
BA_ "Platform_VMCU1_Sig" SG_ 2432645412 LoadDistributionSelected_ISig_4 1;
BA_ "GenSigCycleTime" SG_ 2432645412 RideHeightFunctionStatus_ISig_4 100;
BA_ "GenSigCycleTimeActive" SG_ 2432645412 RideHeightFunctionStatus_ISig_4 100;
BA_ "GenSigStartValue" SG_ 2432645412 RideHeightFunctionStatus_ISig_4 15;
BA_ "GenSigMaxLatency" SG_ 2432645412 RideHeightFunctionStatus_ISig_4 28;
BA_ "Platform_VMCU1_Sig" SG_ 2432645412 RideHeightFunctionStatus_ISig_4 1;
BA_ "SeToolAncestorID_SIGNAL" SG_ 2432645412 RideHeightFunctionStatus_ISig_4 "x0000001D042186C7";
BA_ "SeToolItemID_SIGNAL" SG_ 2432645412 RideHeightFunctionStatus_ISig_4 "x0000001D043FB877";
BA_ "SeToolName_SIGNAL" SG_ 2432645412 RideHeightFunctionStatus_ISig_4 "RideHeightFunctionStatus";
BA_ "SeToolVersion_SIGNAL" SG_ 2432645412 RideHeightFunctionStatus_ISig_4 "2";
BA_ "GenSigSendType" SG_ 2432638500 GearSplit_Status_UB_ISig_4 7;
BA_ "Platform_VMCU1_Sig" SG_ 2432638500 GearSplit_Status_UB_ISig_4 1;
BA_ "GenSigCycleTime" SG_ 2432638500 TransmLowRangeSenseSwitch_ISig_4 100;
BA_ "GenSigCycleTimeActive" SG_ 2432638500 TransmLowRangeSenseSwitch_ISig_4 100;
BA_ "GenSigStartValue" SG_ 2432638500 TransmLowRangeSenseSwitch_ISig_4 3;
BA_ "Platform_VMCU1_Sig" SG_ 2432638500 TransmLowRangeSenseSwitch_ISig_4 1;
BA_ "GenSigCycleTime" SG_ 2432638500 TransmSystemPowerDown_rqst 100;
BA_ "GenSigCycleTimeActive" SG_ 2432638500 TransmSystemPowerDown_rqst 100;
BA_ "GenSigStartValue" SG_ 2432638500 TransmSystemPowerDown_rqst 3;
BA_ "GenSigMaxLatency" SG_ 2432638500 TransmSystemPowerDown_rqst 26;
BA_ "NeedsUpdateBit" SG_ 2432638500 TransmSystemPowerDown_rqst 1;
BA_ "Platform_VMCU1_Sig" SG_ 2432638500 TransmSystemPowerDown_rqst 1;
BA_ "SeToolAncestorID_SIGNAL" SG_ 2432638500 TransmSystemPowerDown_rqst "x0000001D0437CB03";
BA_ "SeToolItemID_SIGNAL" SG_ 2432638500 TransmSystemPowerDown_rqst "x0000001D0437CB03";
BA_ "SeToolName_SIGNAL" SG_ 2432638500 TransmSystemPowerDown_rqst "TransmissionSystemPowerDownRequest";
BA_ "SeToolVersion_SIGNAL" SG_ 2432638500 TransmSystemPowerDown_rqst "1";
BA_ "GenSigCycleTime" SG_ 2432638500 TransmissionNeutralSwitch_ISig_4 100;
BA_ "GenSigCycleTimeActive" SG_ 2432638500 TransmissionNeutralSwitch_ISig_4 100;
BA_ "GenSigStartValue" SG_ 2432638500 TransmissionNeutralSwitch_ISig_4 3;
BA_ "GenSigMaxLatency" SG_ 2432638500 TransmissionNeutralSwitch_ISig_4 26;
BA_ "NeedsUpdateBit" SG_ 2432638500 TransmissionNeutralSwitch_ISig_4 1;
BA_ "Platform_VMCU1_Sig" SG_ 2432638500 TransmissionNeutralSwitch_ISig_4 1;
BA_ "SeToolAncestorID_SIGNAL" SG_ 2432638500 TransmissionNeutralSwitch_ISig_4 "x0000001D0412E2B6";
BA_ "SeToolItemID_SIGNAL" SG_ 2432638500 TransmissionNeutralSwitch_ISig_4 "x0000001D042FD0C5";
BA_ "SeToolName_SIGNAL" SG_ 2432638500 TransmissionNeutralSwitch_ISig_4 "TransmissionNeutralSwitch";
BA_ "SeToolVersion_SIGNAL" SG_ 2432638500 TransmissionNeutralSwitch_ISig_4 "2";
BA_ "GenSigCycleTime" SG_ 2432638500 SecuredNeutralPosition_ISig_4 100;
BA_ "GenSigCycleTimeActive" SG_ 2432638500 SecuredNeutralPosition_ISig_4 100;
BA_ "GenSigStartValue" SG_ 2432638500 SecuredNeutralPosition_ISig_4 3;
BA_ "NeedsUpdateBit" SG_ 2432638500 SecuredNeutralPosition_ISig_4 1;
BA_ "Platform_VMCU1_Sig" SG_ 2432638500 SecuredNeutralPosition_ISig_4 1;
BA_ "SeToolAncestorID_SIGNAL" SG_ 2432638500 SecuredNeutralPosition_ISig_4 "x0000001D04127A25";
BA_ "SeToolItemID_SIGNAL" SG_ 2432638500 SecuredNeutralPosition_ISig_4 "x0000001D043C813E";
BA_ "SeToolName_SIGNAL" SG_ 2432638500 SecuredNeutralPosition_ISig_4 "SecuredNeutralPosition";
BA_ "SeToolVersion_SIGNAL" SG_ 2432638500 SecuredNeutralPosition_ISig_4 "2";
BA_ "GenSigCycleTime" SG_ 2432638500 EngineStopRequest_ISig_4 100;
BA_ "GenSigCycleTimeActive" SG_ 2432638500 EngineStopRequest_ISig_4 100;
BA_ "GenSigStartValue" SG_ 2432638500 EngineStopRequest_ISig_4 3;
BA_ "GenSigMaxLatency" SG_ 2432638500 EngineStopRequest_ISig_4 26;
BA_ "Platform_VMCU1_Sig" SG_ 2432638500 EngineStopRequest_ISig_4 1;
BA_ "SeToolAncestorID_SIGNAL" SG_ 2432638500 EngineStopRequest_ISig_4 "x0000001D042883AC";
BA_ "SeToolItemID_SIGNAL" SG_ 2432638500 EngineStopRequest_ISig_4 "x0000001D042883AC";
BA_ "SeToolName_SIGNAL" SG_ 2432638500 EngineStopRequest_ISig_4 "EngineStopRequest";
BA_ "SeToolVersion_SIGNAL" SG_ 2432638500 EngineStopRequest_ISig_4 "1";
BA_ "GenSigCycleTime" SG_ 2432638500 DirectionIndicatorLights_rqst_IS 100;
BA_ "GenSigCycleTimeActive" SG_ 2432638500 DirectionIndicatorLights_rqst_IS 100;
BA_ "GenSigStartValue" SG_ 2432638500 DirectionIndicatorLights_rqst_IS 7;
BA_ "GenSigMaxLatency" SG_ 2432638500 DirectionIndicatorLights_rqst_IS 26;
BA_ "Platform_VMCU1_Sig" SG_ 2432638500 DirectionIndicatorLights_rqst_IS 1;
BA_ "SeToolAncestorID_SIGNAL" SG_ 2432638500 DirectionIndicatorLights_rqst_IS "x0000001D04134ABF";
BA_ "SeToolItemID_SIGNAL" SG_ 2432638500 DirectionIndicatorLights_rqst_IS "x0000001D042DB5E8";
BA_ "SeToolName_SIGNAL" SG_ 2432638500 DirectionIndicatorLights_rqst_IS "DirectionIndicatorLights_rqst";
BA_ "SeToolVersion_SIGNAL" SG_ 2432638500 DirectionIndicatorLights_rqst_IS "3";
BA_ "SystemSignalLongSymbol" SG_ 2432638500 DirectionIndicatorLights_rqst_IS "DirectionIndicatorLights_rqst_ISig_4";
BA_ "GenSigSendType" SG_ 2432638500 TransmissionNeutralSwitch_UB_ISi 7;
BA_ "Platform_VMCU1_Sig" SG_ 2432638500 TransmissionNeutralSwitch_UB_ISi 1;
BA_ "SystemSignalLongSymbol" SG_ 2432638500 TransmissionNeutralSwitch_UB_ISi "TransmissionNeutralSwitch_UB_ISig_4";
BA_ "GenSigCycleTime" SG_ 2432638500 ReverseGearEngaged_ISig_4 100;
BA_ "GenSigCycleTimeActive" SG_ 2432638500 ReverseGearEngaged_ISig_4 100;
BA_ "GenSigStartValue" SG_ 2432638500 ReverseGearEngaged_ISig_4 3;
BA_ "GenSigMaxLatency" SG_ 2432638500 ReverseGearEngaged_ISig_4 26;
BA_ "NeedsUpdateBit" SG_ 2432638500 ReverseGearEngaged_ISig_4 1;
BA_ "Platform_VMCU1_Sig" SG_ 2432638500 ReverseGearEngaged_ISig_4 1;
BA_ "SeToolAncestorID_SIGNAL" SG_ 2432638500 ReverseGearEngaged_ISig_4 "x0000001D0413A2F1";
BA_ "SeToolItemID_SIGNAL" SG_ 2432638500 ReverseGearEngaged_ISig_4 "x0000001D0413A2F1";
BA_ "SeToolName_SIGNAL" SG_ 2432638500 ReverseGearEngaged_ISig_4 "ReverseGearEngaged";
BA_ "SeToolVersion_SIGNAL" SG_ 2432638500 ReverseGearEngaged_ISig_4 "1";
BA_ "GenSigSendType" SG_ 2432638500 TransmSystemPowerDown_rqst_UB 7;
BA_ "Platform_VMCU1_Sig" SG_ 2432638500 TransmSystemPowerDown_rqst_UB 1;
BA_ "GenSigCycleTime" SG_ 2432638500 EngineCrankRequest 100;
BA_ "GenSigCycleTimeActive" SG_ 2432638500 EngineCrankRequest 100;
BA_ "GenSigStartValue" SG_ 2432638500 EngineCrankRequest 3;
BA_ "GenSigMaxLatency" SG_ 2432638500 EngineCrankRequest 26;
BA_ "Platform_VMCU1_Sig" SG_ 2432638500 EngineCrankRequest 1;
BA_ "SeToolAncestorID_SIGNAL" SG_ 2432638500 EngineCrankRequest "x0000001D0418E20E";
BA_ "SeToolItemID_SIGNAL" SG_ 2432638500 EngineCrankRequest "x0000001D0421DFDE";
BA_ "SeToolName_SIGNAL" SG_ 2432638500 EngineCrankRequest "EngineCrankRequest";
BA_ "SeToolVersion_SIGNAL" SG_ 2432638500 EngineCrankRequest "2";
BA_ "GenSigSendType" SG_ 2432638500 ParkBrakeActuationStatus_UB_ISig 7;
BA_ "Platform_VMCU1_Sig" SG_ 2432638500 ParkBrakeActuationStatus_UB_ISig 1;
BA_ "SystemSignalLongSymbol" SG_ 2432638500 ParkBrakeActuationStatus_UB_ISig "ParkBrakeActuationStatus_UB_ISig_4";
BA_ "GenSigCycleTime" SG_ 2432638500 ParkBrakeActuationStatus_ISig_4 100;
BA_ "GenSigCycleTimeActive" SG_ 2432638500 ParkBrakeActuationStatus_ISig_4 100;
BA_ "GenSigStartValue" SG_ 2432638500 ParkBrakeActuationStatus_ISig_4 7;
BA_ "NeedsUpdateBit" SG_ 2432638500 ParkBrakeActuationStatus_ISig_4 1;
BA_ "Platform_VMCU1_Sig" SG_ 2432638500 ParkBrakeActuationStatus_ISig_4 1;
BA_ "SeToolAncestorID_SIGNAL" SG_ 2432638500 ParkBrakeActuationStatus_ISig_4 "x0000001D041497B7";
BA_ "SeToolItemID_SIGNAL" SG_ 2432638500 ParkBrakeActuationStatus_ISig_4 "x0000001D0433084A";
BA_ "SeToolName_SIGNAL" SG_ 2432638500 ParkBrakeActuationStatus_ISig_4 "ParkBrakeActuationStatus";
BA_ "SeToolVersion_SIGNAL" SG_ 2432638500 ParkBrakeActuationStatus_ISig_4 "2";
BA_ "GenSigCycleTime" SG_ 2432638500 EnginePreheat_rqst 100;
BA_ "GenSigCycleTimeActive" SG_ 2432638500 EnginePreheat_rqst 100;
BA_ "GenSigStartValue" SG_ 2432638500 EnginePreheat_rqst 3;
BA_ "GenSigMaxLatency" SG_ 2432638500 EnginePreheat_rqst 26;
BA_ "Platform_VMCU1_Sig" SG_ 2432638500 EnginePreheat_rqst 1;
BA_ "SeToolAncestorID_SIGNAL" SG_ 2432638500 EnginePreheat_rqst "x0000001D0419A3FC";
BA_ "SeToolItemID_SIGNAL" SG_ 2432638500 EnginePreheat_rqst "x0000001D04218951";
BA_ "SeToolName_SIGNAL" SG_ 2432638500 EnginePreheat_rqst "EnginePreheat_rqst";
BA_ "SeToolVersion_SIGNAL" SG_ 2432638500 EnginePreheat_rqst "2";
BA_ "GenSigSendType" SG_ 2432638500 ReverseGearEngaged_UB_ISig_4 7;
BA_ "Platform_VMCU1_Sig" SG_ 2432638500 ReverseGearEngaged_UB_ISig_4 1;
BA_ "GenSigCycleTime" SG_ 2432638500 AcceleratorPedalPositionBackup 100;
BA_ "GenSigCycleTimeActive" SG_ 2432638500 AcceleratorPedalPositionBackup 100;
BA_ "GenSigStartValue" SG_ 2432638500 AcceleratorPedalPositionBackup 255;
BA_ "Platform_VMCU1_Sig" SG_ 2432638500 AcceleratorPedalPositionBackup 1;
BA_ "GenSigCycleTime" SG_ 2432638500 KeyPosition_ISig_4 100;
BA_ "GenSigCycleTimeActive" SG_ 2432638500 KeyPosition_ISig_4 100;
BA_ "GenSigStartValue" SG_ 2432638500 KeyPosition_ISig_4 7;
BA_ "GenSigMaxLatency" SG_ 2432638500 KeyPosition_ISig_4 26;
BA_ "Platform_VMCU1_Sig" SG_ 2432638500 KeyPosition_ISig_4 1;
BA_ "SeToolAncestorID_SIGNAL" SG_ 2432638500 KeyPosition_ISig_4 "x0000001D0410D5F7";
BA_ "SeToolItemID_SIGNAL" SG_ 2432638500 KeyPosition_ISig_4 "x0000001D0410D5F7";
BA_ "SeToolName_SIGNAL" SG_ 2432638500 KeyPosition_ISig_4 "KeyPosition";
BA_ "SeToolVersion_SIGNAL" SG_ 2432638500 KeyPosition_ISig_4 "1";
BA_ "GenSigCycleTime" SG_ 2432638500 GearSplit_Status_ISig_4 100;
BA_ "GenSigCycleTimeActive" SG_ 2432638500 GearSplit_Status_ISig_4 100;
BA_ "GenSigStartValue" SG_ 2432638500 GearSplit_Status_ISig_4 3;
BA_ "NeedsUpdateBit" SG_ 2432638500 GearSplit_Status_ISig_4 1;
BA_ "Platform_VMCU1_Sig" SG_ 2432638500 GearSplit_Status_ISig_4 1;
BA_ "GenSigCycleTime" SG_ 2432638500 FerryFunctionSwitchChangeACK_ISi 100;
BA_ "GenSigCycleTimeActive" SG_ 2432638500 FerryFunctionSwitchChangeACK_ISi 100;
BA_ "GenSigStartValue" SG_ 2432638500 FerryFunctionSwitchChangeACK_ISi 3;
BA_ "Platform_VMCU1_Sig" SG_ 2432638500 FerryFunctionSwitchChangeACK_ISi 1;
BA_ "SystemSignalLongSymbol" SG_ 2432638500 FerryFunctionSwitchChangeACK_ISi "FerryFunctionSwitchChangeACK_ISig_4";
BA_ "GenSigSendType" SG_ 2432638500 SecuredNeutralPosition_UB_ISig_4 7;
BA_ "Platform_VMCU1_Sig" SG_ 2432638500 SecuredNeutralPosition_UB_ISig_4 1;
BA_ "GenSigCycleTime" SG_ 2432638500 DirectionIndication_cmd_ISig_4 100;
BA_ "GenSigCycleTimeActive" SG_ 2432638500 DirectionIndication_cmd_ISig_4 100;
BA_ "GenSigStartValue" SG_ 2432638500 DirectionIndication_cmd_ISig_4 15;
BA_ "GenSigMaxLatency" SG_ 2432638500 DirectionIndication_cmd_ISig_4 26;
BA_ "Platform_VMCU1_Sig" SG_ 2432638500 DirectionIndication_cmd_ISig_4 1;
BA_ "SeToolAncestorID_SIGNAL" SG_ 2432638500 DirectionIndication_cmd_ISig_4 "x0000001D042C9D17";
BA_ "SeToolItemID_SIGNAL" SG_ 2432638500 DirectionIndication_cmd_ISig_4 "x0000001D0433EF63";
BA_ "SeToolName_SIGNAL" SG_ 2432638500 DirectionIndication_cmd_ISig_4 "DirectionIndication_cmd";
BA_ "SeToolVersion_SIGNAL" SG_ 2432638500 DirectionIndication_cmd_ISig_4 "2";
BA_ "GenSigCycleTime" SG_ 2432638500 IdleShutdownWarning_ISig_4 100;
BA_ "GenSigCycleTimeActive" SG_ 2432638500 IdleShutdownWarning_ISig_4 100;
BA_ "GenSigStartValue" SG_ 2432638500 IdleShutdownWarning_ISig_4 3;
BA_ "GenSigMaxLatency" SG_ 2432638500 IdleShutdownWarning_ISig_4 26;
BA_ "Platform_VMCU1_Sig" SG_ 2432638500 IdleShutdownWarning_ISig_4 1;
BA_ "SeToolAncestorID_SIGNAL" SG_ 2432638500 IdleShutdownWarning_ISig_4 "x0000001D0417E7DE";
BA_ "SeToolItemID_SIGNAL" SG_ 2432638500 IdleShutdownWarning_ISig_4 "x0000001D0417E7DE";
BA_ "SeToolName_SIGNAL" SG_ 2432638500 IdleShutdownWarning_ISig_4 "IdleShutdownWarning";
BA_ "SeToolVersion_SIGNAL" SG_ 2432638500 IdleShutdownWarning_ISig_4 "1";
BA_ "GenSigCycleTime" SG_ 2432638500 BackToDriveReqACK_ISig_4 100;
BA_ "GenSigCycleTimeActive" SG_ 2432638500 BackToDriveReqACK_ISig_4 100;
BA_ "GenSigStartValue" SG_ 2432638500 BackToDriveReqACK_ISig_4 3;
BA_ "Platform_VMCU1_Sig" SG_ 2432638500 BackToDriveReqACK_ISig_4 1;
BA_ "GenSigCycleTime" SG_ 2432638500 EngineSystemPowerDownRequest_ISi 100;
BA_ "GenSigCycleTimeActive" SG_ 2432638500 EngineSystemPowerDownRequest_ISi 100;
BA_ "GenSigStartValue" SG_ 2432638500 EngineSystemPowerDownRequest_ISi 3;
BA_ "GenSigMaxLatency" SG_ 2432638500 EngineSystemPowerDownRequest_ISi 26;
BA_ "Platform_VMCU1_Sig" SG_ 2432638500 EngineSystemPowerDownRequest_ISi 1;
BA_ "SeToolAncestorID_SIGNAL" SG_ 2432638500 EngineSystemPowerDownRequest_ISi "x0000001D0436C642";
BA_ "SeToolItemID_SIGNAL" SG_ 2432638500 EngineSystemPowerDownRequest_ISi "x0000001D0436C642";
BA_ "SeToolName_SIGNAL" SG_ 2432638500 EngineSystemPowerDownRequest_ISi "EngineSystemPowerDownRequest";
BA_ "SeToolVersion_SIGNAL" SG_ 2432638500 EngineSystemPowerDownRequest_ISi "1";
BA_ "SystemSignalLongSymbol" SG_ 2432638500 EngineSystemPowerDownRequest_ISi "EngineSystemPowerDownRequest_ISig_4";
BA_ "GenSigCycleTime" SG_ 2511149823 FireAlertCFCSpeedLimit_rqst 100;
BA_ "GenSigCycleTimeActive" SG_ 2511149823 FireAlertCFCSpeedLimit_rqst 100;
BA_ "GenSigStartValue" SG_ 2511149823 FireAlertCFCSpeedLimit_rqst 65535;
BA_ "Platform_VMCU1_Sig" SG_ 2511149823 FireAlertCFCSpeedLimit_rqst 1;
BA_ "GenSigCycleTime" SG_ 2511149823 ESCReqSilentMode_CtrlTrimValue 100;
BA_ "GenSigCycleTimeActive" SG_ 2511149823 ESCReqSilentMode_CtrlTrimValue 100;
BA_ "GenSigStartValue" SG_ 2511149823 ESCReqSilentMode_CtrlTrimValue 255;
BA_ "Platform_VMCU1_Sig" SG_ 2511149823 ESCReqSilentMode_CtrlTrimValue 1;
BA_ "GenSigCycleTime" SG_ 2511149823 ESCReqSilentMode_CtrlTrimMode 100;
BA_ "GenSigCycleTimeActive" SG_ 2511149823 ESCReqSilentMode_CtrlTrimMode 100;
BA_ "GenSigStartValue" SG_ 2511149823 ESCReqSilentMode_CtrlTrimMode 15;
BA_ "Platform_VMCU1_Sig" SG_ 2511149823 ESCReqSilentMode_CtrlTrimMode 1;
BA_ "GenSigCycleTime" SG_ 2511149823 ESCReqSilentMode_CtrlTrimStat 100;
BA_ "GenSigCycleTimeActive" SG_ 2511149823 ESCReqSilentMode_CtrlTrimStat 100;
BA_ "GenSigStartValue" SG_ 2511149823 ESCReqSilentMode_CtrlTrimStat 7;
BA_ "Platform_VMCU1_Sig" SG_ 2511149823 ESCReqSilentMode_CtrlTrimStat 1;
BA_ "GenSigCycleTime" SG_ 2511149823 SilentModeCFCSpeedLimit_rqst 100;
BA_ "GenSigCycleTimeActive" SG_ 2511149823 SilentModeCFCSpeedLimit_rqst 100;
BA_ "GenSigStartValue" SG_ 2511149823 SilentModeCFCSpeedLimit_rqst 65535;
BA_ "Platform_VMCU1_Sig" SG_ 2511149823 SilentModeCFCSpeedLimit_rqst 1;
BA_ "GenSigCycleTime" SG_ 2511149823 ESCReqSilentMode_CtrlTrimReq 100;
BA_ "GenSigCycleTimeActive" SG_ 2511149823 ESCReqSilentMode_CtrlTrimReq 100;
BA_ "GenSigStartValue" SG_ 2511149823 ESCReqSilentMode_CtrlTrimReq 7;
BA_ "Platform_VMCU1_Sig" SG_ 2511149823 ESCReqSilentMode_CtrlTrimReq 1;
BA_ "GenSigSendType" SG_ 2671902706 FuncDiagDataTester_ISig_4 7;
BA_ "Platform_VMCU1_Sig" SG_ 2671902706 FuncDiagDataTester_ISig_4 1;
BA_ "GenSigSendType" SG_ 2566356992 TECU_BB2_06S_FCS 7;
BA_ "GenSigSendType" SG_ 2566356991 ECU5VIN_stat 1;
BA_ "GenSigMaxLatency" SG_ 2566356991 ECU5VIN_stat 137;
BA_ "GenSigSendType" SG_ 2499794048 TECU_BB2_05S_FCS 7;
BA_ "GenSigSendType" SG_ 2499794047 KeyID_EncryptedGBUnlockAuth 1;
BA_ "GenSigMaxLatency" SG_ 2499794047 KeyID_EncryptedGBUnlockAuth 100;
BA_ "GenSigSendType" SG_ 2583412505 TECU_BB2_04S_FCS 7;
BA_ "Platform_VMCU1_Sig" SG_ 2583412505 TECU_BB2_04S_FCS 1;
BA_ "GenSigSendType" SG_ 2583412504 HillDataPkgTECU_ISig_4 1;
BA_ "GenSigMaxLatency" SG_ 2583412504 HillDataPkgTECU_ISig_4 2500;
BA_ "Platform_VMCU1_Sig" SG_ 2583412504 HillDataPkgTECU_ISig_4 1;
BA_ "GenSigCycleTime" SG_ 2549028632 OilLevelDrvInstr_IncorrEngSpe_IS 100;
BA_ "GenSigCycleTimeActive" SG_ 2549028632 OilLevelDrvInstr_IncorrEngSpe_IS 100;
BA_ "GenSigStartValue" SG_ 2549028632 OilLevelDrvInstr_IncorrEngSpe_IS 3;
BA_ "Platform_VMCU1_Sig" SG_ 2549028632 OilLevelDrvInstr_IncorrEngSpe_IS 1;
BA_ "SystemSignalLongSymbol" SG_ 2549028632 OilLevelDrvInstr_IncorrEngSpe_IS "OilLevelDrvInstr_IncorrEngSpe_ISig_4";
BA_ "GenSigCycleTime" SG_ 2549028632 OilLevelDrvInstr_StopVehicle_ISi 100;
BA_ "GenSigCycleTimeActive" SG_ 2549028632 OilLevelDrvInstr_StopVehicle_ISi 100;
BA_ "GenSigStartValue" SG_ 2549028632 OilLevelDrvInstr_StopVehicle_ISi 3;
BA_ "Platform_VMCU1_Sig" SG_ 2549028632 OilLevelDrvInstr_StopVehicle_ISi 1;
BA_ "SystemSignalLongSymbol" SG_ 2549028632 OilLevelDrvInstr_StopVehicle_ISi "OilLevelDrvInstr_StopVehicle_ISig_4";
BA_ "GenSigCycleTime" SG_ 2549028632 HillDataCtrlTECU_State_ISig_4 100;
BA_ "GenSigCycleTimeActive" SG_ 2549028632 HillDataCtrlTECU_State_ISig_4 100;
BA_ "GenSigStartValue" SG_ 2549028632 HillDataCtrlTECU_State_ISig_4 7;
BA_ "Platform_VMCU1_Sig" SG_ 2549028632 HillDataCtrlTECU_State_ISig_4 1;
BA_ "GenSigCycleTime" SG_ 2549028632 OilLevelDrvInstr_Wait60SecTxt_IS 100;
BA_ "GenSigCycleTimeActive" SG_ 2549028632 OilLevelDrvInstr_Wait60SecTxt_IS 100;
BA_ "GenSigStartValue" SG_ 2549028632 OilLevelDrvInstr_Wait60SecTxt_IS 3;
BA_ "Platform_VMCU1_Sig" SG_ 2549028632 OilLevelDrvInstr_Wait60SecTxt_IS 1;
BA_ "SystemSignalLongSymbol" SG_ 2549028632 OilLevelDrvInstr_Wait60SecTxt_IS "OilLevelDrvInstr_Wait60SecTxt_ISig_4";
BA_ "GenSigCycleTime" SG_ 2549028632 ClutchAbuseStatus_ISig_4 100;
BA_ "GenSigCycleTimeActive" SG_ 2549028632 ClutchAbuseStatus_ISig_4 100;
BA_ "GenSigStartValue" SG_ 2549028632 ClutchAbuseStatus_ISig_4 3;
BA_ "Platform_VMCU1_Sig" SG_ 2549028632 ClutchAbuseStatus_ISig_4 1;
BA_ "GenSigCycleTime" SG_ 2549028632 TransmissionSplitboxPTOMode_ISig 100;
BA_ "GenSigCycleTimeActive" SG_ 2549028632 TransmissionSplitboxPTOMode_ISig 100;
BA_ "GenSigStartValue" SG_ 2549028632 TransmissionSplitboxPTOMode_ISig 7;
BA_ "SystemSignalLongSymbol" SG_ 2549028632 TransmissionSplitboxPTOMode_ISig "TransmissionSplitboxPTOMode_ISig_4";
BA_ "GenSigCycleTime" SG_ 2549028632 SchwungStatus 100;
BA_ "GenSigCycleTimeActive" SG_ 2549028632 SchwungStatus 100;
BA_ "GenSigStartValue" SG_ 2549028632 SchwungStatus 3;
BA_ "GenSigCycleTime" SG_ 2549028632 ClutchCalibration_stat 100;
BA_ "GenSigCycleTimeActive" SG_ 2549028632 ClutchCalibration_stat 100;
BA_ "GenSigStartValue" SG_ 2549028632 ClutchCalibration_stat 3;
BA_ "GenSigCycleTime" SG_ 2549028632 OilLevelDrvInstr_ChangeGearTxt_I 100;
BA_ "GenSigCycleTimeActive" SG_ 2549028632 OilLevelDrvInstr_ChangeGearTxt_I 100;
BA_ "GenSigStartValue" SG_ 2549028632 OilLevelDrvInstr_ChangeGearTxt_I 3;
BA_ "Platform_VMCU1_Sig" SG_ 2549028632 OilLevelDrvInstr_ChangeGearTxt_I 1;
BA_ "SystemSignalLongSymbol" SG_ 2549028632 OilLevelDrvInstr_ChangeGearTxt_I "OilLevelDrvInstr_ChangeGearTxt_ISig_4";
BA_ "GenSigCycleTime" SG_ 2549028632 OilLevelDrvInstr_NotHorizonTxt_I 100;
BA_ "GenSigCycleTimeActive" SG_ 2549028632 OilLevelDrvInstr_NotHorizonTxt_I 100;
BA_ "GenSigStartValue" SG_ 2549028632 OilLevelDrvInstr_NotHorizonTxt_I 3;
BA_ "Platform_VMCU1_Sig" SG_ 2549028632 OilLevelDrvInstr_NotHorizonTxt_I 1;
BA_ "SystemSignalLongSymbol" SG_ 2549028632 OilLevelDrvInstr_NotHorizonTxt_I "OilLevelDrvInstr_NotHorizonTxt_ISig_4";
BA_ "GenSigCycleTime" SG_ 2549028632 ISeeStatus_ISig_4 100;
BA_ "GenSigCycleTimeActive" SG_ 2549028632 ISeeStatus_ISig_4 100;
BA_ "GenSigStartValue" SG_ 2549028632 ISeeStatus_ISig_4 7;
BA_ "GenSigCycleTime" SG_ 2549028632 EcoRollEnabledStatus_ISig_4 100;
BA_ "GenSigCycleTimeActive" SG_ 2549028632 EcoRollEnabledStatus_ISig_4 100;
BA_ "GenSigStartValue" SG_ 2549028632 EcoRollEnabledStatus_ISig_4 3;
BA_ "GenSigCycleTime" SG_ 2549028632 OilLevelDrvInstr_OilTempTxt_ISig 100;
BA_ "GenSigCycleTimeActive" SG_ 2549028632 OilLevelDrvInstr_OilTempTxt_ISig 100;
BA_ "GenSigStartValue" SG_ 2549028632 OilLevelDrvInstr_OilTempTxt_ISig 3;
BA_ "Platform_VMCU1_Sig" SG_ 2549028632 OilLevelDrvInstr_OilTempTxt_ISig 1;
BA_ "SystemSignalLongSymbol" SG_ 2549028632 OilLevelDrvInstr_OilTempTxt_ISig "OilLevelDrvInstr_OilTempTxt_ISig_4";
BA_ "GenSigCycleTime" SG_ 2549028632 HillDataCtrlTECU_AckCnt_ISig_4 100;
BA_ "GenSigCycleTimeActive" SG_ 2549028632 HillDataCtrlTECU_AckCnt_ISig_4 100;
BA_ "Platform_VMCU1_Sig" SG_ 2549028632 HillDataCtrlTECU_AckCnt_ISig_4 1;
BA_ "GenSigCycleTime" SG_ 2515473944 GearShiftingRec_Steps_ISig_4 100;
BA_ "GenSigCycleTimeActive" SG_ 2515473944 GearShiftingRec_Steps_ISig_4 100;
BA_ "GenSigStartValue" SG_ 2515473944 GearShiftingRec_Steps_ISig_4 7;
BA_ "GenSigCycleTime" SG_ 2515473944 GearShiftingRec_Direction_ISig_4 100;
BA_ "GenSigCycleTimeActive" SG_ 2515473944 GearShiftingRec_Direction_ISig_4 100;
BA_ "GenSigStartValue" SG_ 2515473944 GearShiftingRec_Direction_ISig_4 7;
BA_ "GenSigCycleTime" SG_ 2515473944 BrakeInterlockStatus_ISig_4 100;
BA_ "GenSigCycleTimeActive" SG_ 2515473944 BrakeInterlockStatus_ISig_4 100;
BA_ "Platform_VMCU1_Sig" SG_ 2515473944 BrakeInterlockStatus_ISig_4 1;
BA_ "GenSigCycleTime" SG_ 2515473944 AutGearSplitPosition_ISig_4 100;
BA_ "GenSigCycleTimeActive" SG_ 2515473944 AutGearSplitPosition_ISig_4 100;
BA_ "GenSigStartValue" SG_ 2515473944 AutGearSplitPosition_ISig_4 7;
BA_ "Platform_VMCU1_Sig" SG_ 2515473944 AutGearSplitPosition_ISig_4 1;
BA_ "GenSigCycleTime" SG_ 2515473944 TransmissionBrakeMode_ISig_4 100;
BA_ "GenSigCycleTimeActive" SG_ 2515473944 TransmissionBrakeMode_ISig_4 100;
BA_ "GenSigStartValue" SG_ 2515473944 TransmissionBrakeMode_ISig_4 3;
BA_ "GenSigCycleTime" SG_ 2515473944 AvailableGearsWithLowerRatio_ISi 100;
BA_ "GenSigCycleTimeActive" SG_ 2515473944 AvailableGearsWithLowerRatio_ISi 100;
BA_ "GenSigStartValue" SG_ 2515473944 AvailableGearsWithLowerRatio_ISi 15;
BA_ "GenSigMaxLatency" SG_ 2515473944 AvailableGearsWithLowerRatio_ISi 26;
BA_ "Platform_VMCU1_Sig" SG_ 2515473944 AvailableGearsWithLowerRatio_ISi 1;
BA_ "SeToolAncestorID_SIGNAL" SG_ 2515473944 AvailableGearsWithLowerRatio_ISi "x0000001D0416F544";
BA_ "SeToolItemID_SIGNAL" SG_ 2515473944 AvailableGearsWithLowerRatio_ISi "x0000001D0436DC28";
BA_ "SeToolName_SIGNAL" SG_ 2515473944 AvailableGearsWithLowerRatio_ISi "NumberOfAvailableGearsWithLowerRatio";
BA_ "SeToolVersion_SIGNAL" SG_ 2515473944 AvailableGearsWithLowerRatio_ISi "2";
BA_ "SystemSignalLongSymbol" SG_ 2515473944 AvailableGearsWithLowerRatio_ISi "AvailableGearsWithLowerRatio_ISig_4";
BA_ "GenSigCycleTime" SG_ 2515473944 FuelEcoDrvStatus 100;
BA_ "GenSigCycleTimeActive" SG_ 2515473944 FuelEcoDrvStatus 100;
BA_ "GenSigStartValue" SG_ 2515473944 FuelEcoDrvStatus 3;
BA_ "Platform_VMCU1_Sig" SG_ 2515473944 FuelEcoDrvStatus 1;
BA_ "GenSigCycleTime" SG_ 2515473944 EcoCruiseStatus_ISig_4 100;
BA_ "GenSigCycleTimeActive" SG_ 2515473944 EcoCruiseStatus_ISig_4 100;
BA_ "GenSigStartValue" SG_ 2515473944 EcoCruiseStatus_ISig_4 7;
BA_ "Platform_VMCU1_Sig" SG_ 2515473944 EcoCruiseStatus_ISig_4 1;
BA_ "GenSigCycleTime" SG_ 2515473944 TransmissionDrivingMode_ISig_4 100;
BA_ "GenSigCycleTimeActive" SG_ 2515473944 TransmissionDrivingMode_ISig_4 100;
BA_ "GenSigStartValue" SG_ 2515473944 TransmissionDrivingMode_ISig_4 7;
BA_ "GenSigCycleTime" SG_ 2515473944 ClutchWearStatus 100;
BA_ "GenSigCycleTimeActive" SG_ 2515473944 ClutchWearStatus 100;
BA_ "GenSigStartValue" SG_ 2515473944 ClutchWearStatus 255;
BA_ "GenSigMaxLatency" SG_ 2515473944 ClutchWearStatus 26;
BA_ "Platform_VMCU1_Sig" SG_ 2515473944 ClutchWearStatus 1;
BA_ "SeToolAncestorID_SIGNAL" SG_ 2515473944 ClutchWearStatus "x0000001D0419DCE7";
BA_ "SeToolItemID_SIGNAL" SG_ 2515473944 ClutchWearStatus "x0000001D0419DCE7";
BA_ "SeToolName_SIGNAL" SG_ 2515473944 ClutchWearStatus "ClutchWearStatus";
BA_ "SeToolVersion_SIGNAL" SG_ 2515473944 ClutchWearStatus "1";
BA_ "GenSigCycleTime" SG_ 2515473944 AutoWheelBrakeInhibited 100;
BA_ "GenSigCycleTimeActive" SG_ 2515473944 AutoWheelBrakeInhibited 100;
BA_ "GenSigStartValue" SG_ 2515473944 AutoWheelBrakeInhibited 3;
BA_ "Platform_VMCU1_Sig" SG_ 2515473944 AutoWheelBrakeInhibited 1;
BA_ "GenSigCycleTime" SG_ 2515473944 DrivingMode_ISig_4 100;
BA_ "GenSigCycleTimeActive" SG_ 2515473944 DrivingMode_ISig_4 100;
BA_ "GenSigMaxLatency" SG_ 2515473944 DrivingMode_ISig_4 26;
BA_ "Platform_VMCU1_Sig" SG_ 2515473944 DrivingMode_ISig_4 1;
BA_ "SigType" SG_ 2515473944 DrivingMode_ISig_4 3;
BA_ "SeToolAncestorID_SIGNAL" SG_ 2515473944 DrivingMode_ISig_4 "x0000001D0413D7DC";
BA_ "SeToolItemID_SIGNAL" SG_ 2515473944 DrivingMode_ISig_4 "x0000001D0435EBD7";
BA_ "SeToolName_SIGNAL" SG_ 2515473944 DrivingMode_ISig_4 "DrivingMode";
BA_ "SeToolVersion_SIGNAL" SG_ 2515473944 DrivingMode_ISig_4 "4";
BA_ "GenSigCycleTime" SG_ 2515473944 AutoWheelBrakesDownshiftSugges_I 100;
BA_ "GenSigCycleTimeActive" SG_ 2515473944 AutoWheelBrakesDownshiftSugges_I 100;
BA_ "GenSigStartValue" SG_ 2515473944 AutoWheelBrakesDownshiftSugges_I 3;
BA_ "SystemSignalLongSymbol" SG_ 2515473944 AutoWheelBrakesDownshiftSugges_I "AutoWheelBrakesDownshiftSugges_ISig_4";
BA_ "GenSigCycleTime" SG_ 2515473944 TransmissionMainOilPress_stat 100;
BA_ "GenSigCycleTimeActive" SG_ 2515473944 TransmissionMainOilPress_stat 100;
BA_ "GenSigStartValue" SG_ 2515473944 TransmissionMainOilPress_stat 3;
BA_ "Platform_VMCU1_Sig" SG_ 2515473944 TransmissionMainOilPress_stat 1;
BA_ "GenSigCycleTime" SG_ 2515473944 TransmissionOilTempHigh_ISig_4 100;
BA_ "GenSigCycleTimeActive" SG_ 2515473944 TransmissionOilTempHigh_ISig_4 100;
BA_ "GenSigStartValue" SG_ 2515473944 TransmissionOilTempHigh_ISig_4 7;
BA_ "GenSigMaxLatency" SG_ 2515473944 TransmissionOilTempHigh_ISig_4 26;
BA_ "Platform_VMCU1_Sig" SG_ 2515473944 TransmissionOilTempHigh_ISig_4 1;
BA_ "SeToolAncestorID_SIGNAL" SG_ 2515473944 TransmissionOilTempHigh_ISig_4 "x0000001D0415A8B5";
BA_ "SeToolItemID_SIGNAL" SG_ 2515473944 TransmissionOilTempHigh_ISig_4 "x0000001D04239BC4";
BA_ "SeToolName_SIGNAL" SG_ 2515473944 TransmissionOilTempHigh_ISig_4 "TransmissionOilTempHigh";
BA_ "SeToolVersion_SIGNAL" SG_ 2515473944 TransmissionOilTempHigh_ISig_4 "2";
BA_ "GenSigCycleTime" SG_ 2515473944 AvailableGearsWithHigherRatio_IS 100;
BA_ "GenSigCycleTimeActive" SG_ 2515473944 AvailableGearsWithHigherRatio_IS 100;
BA_ "GenSigStartValue" SG_ 2515473944 AvailableGearsWithHigherRatio_IS 15;
BA_ "GenSigMaxLatency" SG_ 2515473944 AvailableGearsWithHigherRatio_IS 26;
BA_ "Platform_VMCU1_Sig" SG_ 2515473944 AvailableGearsWithHigherRatio_IS 1;
BA_ "SeToolAncestorID_SIGNAL" SG_ 2515473944 AvailableGearsWithHigherRatio_IS "x0000001D0416F542";
BA_ "SeToolItemID_SIGNAL" SG_ 2515473944 AvailableGearsWithHigherRatio_IS "x0000001D0436D7D6";
BA_ "SeToolName_SIGNAL" SG_ 2515473944 AvailableGearsWithHigherRatio_IS "NumberOfAvailableGearsWithHigherRatio";
BA_ "SeToolVersion_SIGNAL" SG_ 2515473944 AvailableGearsWithHigherRatio_IS "2";
BA_ "SystemSignalLongSymbol" SG_ 2515473944 AvailableGearsWithHigherRatio_IS "AvailableGearsWithHigherRatio_ISig_4";
BA_ "GenSigCycleTime" SG_ 2432636184 Pto1Consent_ISig_4 100;
BA_ "GenSigCycleTimeActive" SG_ 2432636184 Pto1Consent_ISig_4 100;
BA_ "GenSigStartValue" SG_ 2432636184 Pto1Consent_ISig_4 3;
BA_ "GenSigMaxLatency" SG_ 2432636184 Pto1Consent_ISig_4 26;
BA_ "Platform_VMCU1_Sig" SG_ 2432636184 Pto1Consent_ISig_4 1;
BA_ "SeToolAncestorID_SIGNAL" SG_ 2432636184 Pto1Consent_ISig_4 "x0000001D04156EBD";
BA_ "SeToolItemID_SIGNAL" SG_ 2432636184 Pto1Consent_ISig_4 "x0000001D043A5CEC";
BA_ "SeToolName_SIGNAL" SG_ 2432636184 Pto1Consent_ISig_4 "Pto1Consent";
BA_ "SeToolVersion_SIGNAL" SG_ 2432636184 Pto1Consent_ISig_4 "2";
BA_ "GenSigCycleTime" SG_ 2432636184 Pto2Consent_ISig_4 100;
BA_ "GenSigCycleTimeActive" SG_ 2432636184 Pto2Consent_ISig_4 100;
BA_ "GenSigStartValue" SG_ 2432636184 Pto2Consent_ISig_4 3;
BA_ "GenSigMaxLatency" SG_ 2432636184 Pto2Consent_ISig_4 26;
BA_ "Platform_VMCU1_Sig" SG_ 2432636184 Pto2Consent_ISig_4 1;
BA_ "SeToolAncestorID_SIGNAL" SG_ 2432636184 Pto2Consent_ISig_4 "x0000001D04156EBF";
BA_ "SeToolItemID_SIGNAL" SG_ 2432636184 Pto2Consent_ISig_4 "x0000001D043A5D14";
BA_ "SeToolName_SIGNAL" SG_ 2432636184 Pto2Consent_ISig_4 "Pto2Consent";
BA_ "SeToolVersion_SIGNAL" SG_ 2432636184 Pto2Consent_ISig_4 "2";
BA_ "GenSigCycleTime" SG_ 2432636184 DirectionGearAllowed 100;
BA_ "GenSigCycleTimeActive" SG_ 2432636184 DirectionGearAllowed 100;
BA_ "GenSigStartValue" SG_ 2432636184 DirectionGearAllowed 7;
BA_ "GenSigMaxLatency" SG_ 2432636184 DirectionGearAllowed 26;
BA_ "Platform_VMCU1_Sig" SG_ 2432636184 DirectionGearAllowed 1;
BA_ "SeToolAncestorID_SIGNAL" SG_ 2432636184 DirectionGearAllowed "x0000001D0416F6B7";
BA_ "SeToolItemID_SIGNAL" SG_ 2432636184 DirectionGearAllowed "x0000001D0416F6B7";
BA_ "SeToolName_SIGNAL" SG_ 2432636184 DirectionGearAllowed "DirectionGearAllowed";
BA_ "SeToolVersion_SIGNAL" SG_ 2432636184 DirectionGearAllowed "1";
BA_ "GenSigCycleTime" SG_ 2432636184 TransmissionSystemPowerDownAck 100;
BA_ "GenSigCycleTimeActive" SG_ 2432636184 TransmissionSystemPowerDownAck 100;
BA_ "GenSigStartValue" SG_ 2432636184 TransmissionSystemPowerDownAck 3;
BA_ "GenSigMaxLatency" SG_ 2432636184 TransmissionSystemPowerDownAck 26;
BA_ "Platform_VMCU1_Sig" SG_ 2432636184 TransmissionSystemPowerDownAck 1;
BA_ "SeToolAncestorID_SIGNAL" SG_ 2432636184 TransmissionSystemPowerDownAck "x0000001D0437CB4B";
BA_ "SeToolItemID_SIGNAL" SG_ 2432636184 TransmissionSystemPowerDownAck "x0000001D0437CB4B";
BA_ "SeToolName_SIGNAL" SG_ 2432636184 TransmissionSystemPowerDownAck "TransmissionSystemPowerDownAck";
BA_ "SeToolVersion_SIGNAL" SG_ 2432636184 TransmissionSystemPowerDownAck "1";
BA_ "GenSigCycleTime" SG_ 2432636184 EcoRollActiveStatus_ISig_4 100;
BA_ "GenSigCycleTimeActive" SG_ 2432636184 EcoRollActiveStatus_ISig_4 100;
BA_ "GenSigStartValue" SG_ 2432636184 EcoRollActiveStatus_ISig_4 3;
BA_ "GenSigMaxLatency" SG_ 2432636184 EcoRollActiveStatus_ISig_4 26;
BA_ "Platform_VMCU1_Sig" SG_ 2432636184 EcoRollActiveStatus_ISig_4 1;
BA_ "SeToolAncestorID_SIGNAL" SG_ 2432636184 EcoRollActiveStatus_ISig_4 "x0000001D043EEFC6";
BA_ "SeToolItemID_SIGNAL" SG_ 2432636184 EcoRollActiveStatus_ISig_4 "x0000001D043EEFC6";
BA_ "SeToolName_SIGNAL" SG_ 2432636184 EcoRollActiveStatus_ISig_4 "Eco-RollActiveStatus";
BA_ "SeToolVersion_SIGNAL" SG_ 2432636184 EcoRollActiveStatus_ISig_4 "1";
BA_ "GenSigCycleTime" SG_ 2432636184 TransmissionAirPressureLow_ISig_ 100;
BA_ "GenSigCycleTimeActive" SG_ 2432636184 TransmissionAirPressureLow_ISig_ 100;
BA_ "GenSigStartValue" SG_ 2432636184 TransmissionAirPressureLow_ISig_ 3;
BA_ "GenSigMaxLatency" SG_ 2432636184 TransmissionAirPressureLow_ISig_ 26;
BA_ "Platform_VMCU1_Sig" SG_ 2432636184 TransmissionAirPressureLow_ISig_ 1;
BA_ "SeToolAncestorID_SIGNAL" SG_ 2432636184 TransmissionAirPressureLow_ISig_ "x0000001D04215F7D";
BA_ "SeToolItemID_SIGNAL" SG_ 2432636184 TransmissionAirPressureLow_ISig_ "x0000001D04215F7D";
BA_ "SeToolName_SIGNAL" SG_ 2432636184 TransmissionAirPressureLow_ISig_ "TransmissionAirPressureLow";
BA_ "SeToolVersion_SIGNAL" SG_ 2432636184 TransmissionAirPressureLow_ISig_ "1";
BA_ "SystemSignalLongSymbol" SG_ 2432636184 TransmissionAirPressureLow_ISig_ "TransmissionAirPressureLow_ISig_4";
BA_ "GenSigCycleTime" SG_ 2432636184 TransmEngineStop_req 100;
BA_ "GenSigCycleTimeActive" SG_ 2432636184 TransmEngineStop_req 100;
BA_ "GenSigStartValue" SG_ 2432636184 TransmEngineStop_req 3;
BA_ "GenSigMaxLatency" SG_ 2432636184 TransmEngineStop_req 26;
BA_ "Platform_VMCU1_Sig" SG_ 2432636184 TransmEngineStop_req 1;
BA_ "GenSigCycleTime" SG_ 2432636184 GearBoxUnlockAuth_rqst 100;
BA_ "GenSigCycleTimeActive" SG_ 2432636184 GearBoxUnlockAuth_rqst 100;
BA_ "GenSigStartValue" SG_ 2432636184 GearBoxUnlockAuth_rqst 3;
BA_ "GenSigMaxLatency" SG_ 2432636184 GearBoxUnlockAuth_rqst 100;
BA_ "GenSigCycleTime" SG_ 2432636184 RoadInclination_ISig_4 100;
BA_ "GenSigCycleTimeActive" SG_ 2432636184 RoadInclination_ISig_4 100;
BA_ "GenSigStartValue" SG_ 2432636184 RoadInclination_ISig_4 255;
BA_ "GenSigMaxLatency" SG_ 2432636184 RoadInclination_ISig_4 26;
BA_ "Platform_VMCU1_Sig" SG_ 2432636184 RoadInclination_ISig_4 1;
BA_ "SeToolAncestorID_SIGNAL" SG_ 2432636184 RoadInclination_ISig_4 "x0000001D043FA322";
BA_ "SeToolItemID_SIGNAL" SG_ 2432636184 RoadInclination_ISig_4 "x0000001D043FA322";
BA_ "SeToolName_SIGNAL" SG_ 2432636184 RoadInclination_ISig_4 "RoadInclination";
BA_ "SeToolVersion_SIGNAL" SG_ 2432636184 RoadInclination_ISig_4 "1";
BA_ "GenSigCycleTime" SG_ 2432636184 ACC_SGO_TransmissionStatus 100;
BA_ "GenSigCycleTimeActive" SG_ 2432636184 ACC_SGO_TransmissionStatus 100;
BA_ "GenSigStartValue" SG_ 2432636184 ACC_SGO_TransmissionStatus 7;
BA_ "Platform_VMCU1_Sig" SG_ 2432636184 ACC_SGO_TransmissionStatus 1;
BA_ "GenSigCycleTime" SG_ 2432636184 ClutchOverloadStatus_ISig_4 100;
BA_ "GenSigCycleTimeActive" SG_ 2432636184 ClutchOverloadStatus_ISig_4 100;
BA_ "GenSigStartValue" SG_ 2432636184 ClutchOverloadStatus_ISig_4 3;
BA_ "GenSigMaxLatency" SG_ 2432636184 ClutchOverloadStatus_ISig_4 26;
BA_ "Platform_VMCU1_Sig" SG_ 2432636184 ClutchOverloadStatus_ISig_4 1;
BA_ "SeToolAncestorID_SIGNAL" SG_ 2432636184 ClutchOverloadStatus_ISig_4 "x0000001D041744A1";
BA_ "SeToolItemID_SIGNAL" SG_ 2432636184 ClutchOverloadStatus_ISig_4 "x0000001D041744A1";
BA_ "SeToolName_SIGNAL" SG_ 2432636184 ClutchOverloadStatus_ISig_4 "ClutchOverloadStatus";
BA_ "SeToolVersion_SIGNAL" SG_ 2432636184 ClutchOverloadStatus_ISig_4 "1";
BA_ "GenSigSendType" SG_ 2671833830 PhysDiagRespSig_F2_E6_ISig_4 7;
BA_ "Platform_VMCU1_Sig" SG_ 2671833830 PhysDiagRespSig_F2_E6_ISig_4 1;
BA_ "GenSigSendType" SG_ 2671833829 PhysDiagRespSig_F2_E5_ISig_4 7;
BA_ "GenSigSendType" SG_ 2671833792 PhysDiagRespSig_F2_C0_ISig_4 7;
BA_ "Platform_VMCU1_Sig" SG_ 2671833792 PhysDiagRespSig_F2_C0_ISig_4 1;
BA_ "GenSigSendType" SG_ 2671833762 PhysDiagRespSig_F2_A2_ISig_4 7;
BA_ "Platform_VMCU1_Sig" SG_ 2671833762 PhysDiagRespSig_F2_A2_ISig_4 1;
BA_ "GenSigSendType" SG_ 2671833761 PhysDiagRespSig_F2_A1_ISig_4 7;
BA_ "Platform_VMCU1_Sig" SG_ 2671833761 PhysDiagRespSig_F2_A1_ISig_4 1;
BA_ "GenSigSendType" SG_ 2671833760 PhysDiagRespSig_F2_A0_ISig_4 7;
BA_ "Platform_VMCU1_Sig" SG_ 2671833760 PhysDiagRespSig_F2_A0_ISig_4 1;
BA_ "GenSigSendType" SG_ 2671833752 PhysDiagRespSig_F2_98_ISig_4 7;
BA_ "Platform_VMCU1_Sig" SG_ 2671833752 PhysDiagRespSig_F2_98_ISig_4 1;
BA_ "GenSigSendType" SG_ 2671833730 PhysDiagRespSig_F2_82_ISig_4 7;
BA_ "Platform_VMCU1_Sig" SG_ 2671833730 PhysDiagRespSig_F2_82_ISig_4 1;
BA_ "GenSigSendType" SG_ 2671833728 PhysDiagRespSig_F2_80_ISig_4 7;
BA_ "Platform_VMCU1_Sig" SG_ 2671833728 PhysDiagRespSig_F2_80_ISig_4 1;
BA_ "GenSigSendType" SG_ 2671833699 PhysDiagRespSig_F2_63_ISig_4 7;
BA_ "Platform_VMCU1_Sig" SG_ 2671833699 PhysDiagRespSig_F2_63_ISig_4 1;
BA_ "GenSigSendType" SG_ 2671833698 PhysDiagRespSig_F2_62_ISig_4 7;
BA_ "Platform_VMCU1_Sig" SG_ 2671833698 PhysDiagRespSig_F2_62_ISig_4 1;
BA_ "GenSigSendType" SG_ 2671833697 PhysDiagRespSig_F2_61_ISig_4 7;
BA_ "Platform_VMCU1_Sig" SG_ 2671833697 PhysDiagRespSig_F2_61_ISig_4 1;
BA_ "GenSigSendType" SG_ 2671833696 PhysDiagRespSig_F2_60_ISig_4 7;
BA_ "Platform_VMCU1_Sig" SG_ 2671833696 PhysDiagRespSig_F2_60_ISig_4 1;
BA_ "GenSigSendType" SG_ 2671833683 PhysDiagRespSig_F2_53_ISig_4 7;
BA_ "Platform_VMCU1_Sig" SG_ 2671833683 PhysDiagRespSig_F2_53_ISig_4 1;
BA_ "GenSigSendType" SG_ 2671833682 PhysDiagRespSig_F2_52_ISig_4 7;
BA_ "Platform_VMCU1_Sig" SG_ 2671833682 PhysDiagRespSig_F2_52_ISig_4 1;
BA_ "GenSigSendType" SG_ 2671833681 PhysDiagRespSig_F2_51_ISig_4 7;
BA_ "Platform_VMCU1_Sig" SG_ 2671833681 PhysDiagRespSig_F2_51_ISig_4 1;
BA_ "GenSigSendType" SG_ 2671833680 PhysDiagRespSig_F2_50_ISig_4 7;
BA_ "Platform_VMCU1_Sig" SG_ 2671833680 PhysDiagRespSig_F2_50_ISig_4 1;
BA_ "GenSigSendType" SG_ 2671833665 PhysDiagRespSig_F2_41_ISig_4 7;
BA_ "Platform_VMCU1_Sig" SG_ 2671833665 PhysDiagRespSig_F2_41_ISig_4 1;
BA_ "GenSigSendType" SG_ 2671833664 PhysDiagRespSig_F2_40_ISig_4 7;
BA_ "Platform_VMCU1_Sig" SG_ 2671833664 PhysDiagRespSig_F2_40_ISig_4 1;
BA_ "GenSigSendType" SG_ 2671833638 PhysDiagRespSig_F2_26_ISig_4 7;
BA_ "Platform_VMCU1_Sig" SG_ 2671833638 PhysDiagRespSig_F2_26_ISig_4 1;
BA_ "GenSigSendType" SG_ 2671833624 PhysDiagRespSig_F2_18_ISig_4 7;
BA_ "Platform_VMCU1_Sig" SG_ 2671833624 PhysDiagRespSig_F2_18_ISig_4 1;
BA_ "GenSigSendType" SG_ 2671833616 PhysDiagRespSig_F2_10_ISig_4 7;
BA_ "Platform_VMCU1_Sig" SG_ 2671833616 PhysDiagRespSig_F2_10_ISig_4 1;
BA_ "GenSigSendType" SG_ 2564485459 PhysDiagRespSig_F1_53_ISig_4 7;
BA_ "Platform_VMCU1_Sig" SG_ 2564485459 PhysDiagRespSig_F1_53_ISig_4 1;
BA_ "GenSigSendType" SG_ 2564485392 PhysDiagRespSig_F1_10_extra 7;
BA_ "Platform_VMCU1_Sig" SG_ 2564485392 PhysDiagRespSig_F1_10_extra 1;
BA_ "GenSigSendType" SG_ 2671833360 PhysDiagRespSig_F1_10_ISig_4 7;
BA_ "Platform_VMCU1_Sig" SG_ 2671833360 PhysDiagRespSig_F1_10_ISig_4 1;
BA_ "GenSigSendType" SG_ 2671830770 PhysDiagReqSig_E6_F2_ISig_4 7;
BA_ "Platform_VMCU1_Sig" SG_ 2671830770 PhysDiagReqSig_E6_F2_ISig_4 1;
BA_ "GenSigSendType" SG_ 2671830514 PhysDiagReqSig_E5_F2_ISig_4 7;
BA_ "GenSigSendType" SG_ 2671821042 PhysDiagReqSig_C0_F2_ISig_4 7;
BA_ "Platform_VMCU1_Sig" SG_ 2671821042 PhysDiagReqSig_C0_F2_ISig_4 1;
BA_ "GenSigSendType" SG_ 2671813362 PhysDiagReqSig_A2_F2_ISig_4 7;
BA_ "Platform_VMCU1_Sig" SG_ 2671813362 PhysDiagReqSig_A2_F2_ISig_4 1;
BA_ "GenSigSendType" SG_ 2671813106 PhysDiagReqSig_A1_F2_ISig_4 7;
BA_ "Platform_VMCU1_Sig" SG_ 2671813106 PhysDiagReqSig_A1_F2_ISig_4 1;
BA_ "GenSigSendType" SG_ 2671812850 PhysDiagReqSig_A0_F2_ISig_4 7;
BA_ "Platform_VMCU1_Sig" SG_ 2671812850 PhysDiagReqSig_A0_F2_ISig_4 1;
BA_ "GenSigSendType" SG_ 2671810802 PhysDiagReqSig_98_F2_ISig_4 7;
BA_ "Platform_VMCU1_Sig" SG_ 2671810802 PhysDiagReqSig_98_F2_ISig_4 1;
BA_ "GenSigSendType" SG_ 2671805170 PhysDiagReqSig_82_F2_ISig_4 7;
BA_ "Platform_VMCU1_Sig" SG_ 2671805170 PhysDiagReqSig_82_F2_ISig_4 1;
BA_ "GenSigSendType" SG_ 2671804658 PhysDiagReqSig_80_F2_ISig_4 7;
BA_ "Platform_VMCU1_Sig" SG_ 2671804658 PhysDiagReqSig_80_F2_ISig_4 1;
BA_ "GenSigSendType" SG_ 2671797234 PhysDiagReqSig_63_F2_ISig_4 7;
BA_ "Platform_VMCU1_Sig" SG_ 2671797234 PhysDiagReqSig_63_F2_ISig_4 1;
BA_ "GenSigSendType" SG_ 2671796978 PhysDiagReqSig_62_F2_ISig_4 7;
BA_ "Platform_VMCU1_Sig" SG_ 2671796978 PhysDiagReqSig_62_F2_ISig_4 1;
BA_ "GenSigSendType" SG_ 2671796722 PhysDiagReqSig_61_F2_ISig_4 7;
BA_ "Platform_VMCU1_Sig" SG_ 2671796722 PhysDiagReqSig_61_F2_ISig_4 1;
BA_ "GenSigSendType" SG_ 2671796466 PhysDiagReqSig_60_F2_ISig_4 7;
BA_ "Platform_VMCU1_Sig" SG_ 2671796466 PhysDiagReqSig_60_F2_ISig_4 1;
BA_ "GenSigSendType" SG_ 2671793138 PhysDiagReqSig_53_F2_ISig_4 7;
BA_ "Platform_VMCU1_Sig" SG_ 2671793138 PhysDiagReqSig_53_F2_ISig_4 1;
BA_ "GenSigSendType" SG_ 2564445169 PhysDiagReqSig_53_F1_ISig_4 7;
BA_ "Platform_VMCU1_Sig" SG_ 2564445169 PhysDiagReqSig_53_F1_ISig_4 1;
BA_ "GenSigSendType" SG_ 2671792882 PhysDiagReqSig_52_F2_ISig_4 7;
BA_ "Platform_VMCU1_Sig" SG_ 2671792882 PhysDiagReqSig_52_F2_ISig_4 1;
BA_ "GenSigSendType" SG_ 2671792626 PhysDiagReqSig_51_F2_ISig_4 7;
BA_ "Platform_VMCU1_Sig" SG_ 2671792626 PhysDiagReqSig_51_F2_ISig_4 1;
BA_ "GenSigSendType" SG_ 2671792370 PhysDiagReqSig_50_F2_ISig_4 7;
BA_ "Platform_VMCU1_Sig" SG_ 2671792370 PhysDiagReqSig_50_F2_ISig_4 1;
BA_ "GenSigSendType" SG_ 2671788530 PhysDiagReqSig_41_F2_ISig_4 7;
BA_ "Platform_VMCU1_Sig" SG_ 2671788530 PhysDiagReqSig_41_F2_ISig_4 1;
BA_ "GenSigSendType" SG_ 2671788274 PhysDiagReqSig_40_F2_ISig_4 7;
BA_ "Platform_VMCU1_Sig" SG_ 2671788274 PhysDiagReqSig_40_F2_ISig_4 1;
BA_ "GenSigSendType" SG_ 2671781618 PhysDiagReqSig_26_F2_ISig_4 7;
BA_ "Platform_VMCU1_Sig" SG_ 2671781618 PhysDiagReqSig_26_F2_ISig_4 1;
BA_ "GenSigSendType" SG_ 2671778034 PhysDiagReqSig_18_F2_ISig_4 7;
BA_ "Platform_VMCU1_Sig" SG_ 2671778034 PhysDiagReqSig_18_F2_ISig_4 1;
BA_ "GenSigSendType" SG_ 2671775986 PhysDiagReqSig_10_F2_ISig_4 7;
BA_ "Platform_VMCU1_Sig" SG_ 2671775986 PhysDiagReqSig_10_F2_ISig_4 1;
BA_ "GenSigSendType" SG_ 2564428017 PhysDiagReqSig_10_F1_extra 7;
BA_ "Platform_VMCU1_Sig" SG_ 2564428017 PhysDiagReqSig_10_F1_extra 1;
BA_ "GenSigSendType" SG_ 2671775985 PhysDiagReqSig_10_F1_ISig_4 7;
BA_ "Platform_VMCU1_Sig" SG_ 2671775985 PhysDiagReqSig_10_F1_ISig_4 1;
BA_ "GenSigSendType" SG_ 2564502513 FuncDiagDataOBD_extra 7;
BA_ "Platform_VMCU1_Sig" SG_ 2564502513 FuncDiagDataOBD_extra 1;
BA_ "GenSigSendType" SG_ 2671850481 FuncDiagDataOBD_ISig_4 7;
BA_ "Platform_VMCU1_Sig" SG_ 2671850481 FuncDiagDataOBD_ISig_4 1;
BA_ "GenSigSendType" SG_ 2671902708 FuncDiagDataIntTesterTGW2_ISig_4 7;
BA_ "Platform_VMCU1_Sig" SG_ 2671902708 FuncDiagDataIntTesterTGW2_ISig_4 1;
BA_ "GenSigSendType" SG_ 2582855521 HMIIOM_BB2_S28_FCS 7;
BA_ "Platform_VMCU1_Sig" SG_ 2582855521 HMIIOM_BB2_S28_FCS 1;
BA_ "GenSigCycleTime" SG_ 2566635616 FasUsrDefinedStorage_rqst_ISig_4 100;
BA_ "GenSigCycleTimeActive" SG_ 2566635616 FasUsrDefinedStorage_rqst_ISig_4 100;
BA_ "GenSigStartValue" SG_ 2566635616 FasUsrDefinedStorage_rqst_ISig_4 3;
BA_ "GenSigMaxLatency" SG_ 2566635616 FasUsrDefinedStorage_rqst_ISig_4 1037;
BA_ "GenSigCycleTime" SG_ 2566635616 ATC_ButtonIndication_ISig_4 100;
BA_ "GenSigCycleTimeActive" SG_ 2566635616 ATC_ButtonIndication_ISig_4 100;
BA_ "GenSigMaxLatency" SG_ 2566635616 ATC_ButtonIndication_ISig_4 1037;
BA_ "GenSigCycleTime" SG_ 2566635616 FasLowSpeedReturnSetting_rqst_IS 100;
BA_ "GenSigCycleTimeActive" SG_ 2566635616 FasLowSpeedReturnSetting_rqst_IS 100;
BA_ "GenSigStartValue" SG_ 2566635616 FasLowSpeedReturnSetting_rqst_IS 31;
BA_ "GenSigMaxLatency" SG_ 2566635616 FasLowSpeedReturnSetting_rqst_IS 1037;
BA_ "SystemSignalLongSymbol" SG_ 2566635616 FasLowSpeedReturnSetting_rqst_IS "FasLowSpeedReturnSetting_rqst_ISig_4";
BA_ "GenSigCycleTime" SG_ 2566635616 FasManualOffsetSetting_rqst_ISig 100;
BA_ "GenSigCycleTimeActive" SG_ 2566635616 FasManualOffsetSetting_rqst_ISig 100;
BA_ "GenSigStartValue" SG_ 2566635616 FasManualOffsetSetting_rqst_ISig 31;
BA_ "GenSigMaxLatency" SG_ 2566635616 FasManualOffsetSetting_rqst_ISig 1037;
BA_ "SystemSignalLongSymbol" SG_ 2566635616 FasManualOffsetSetting_rqst_ISig "FasManualOffsetSetting_rqst_ISig_4";
BA_ "GenSigCycleTime" SG_ 2566635616 FasPersonalSettingsButton_rqst_I 100;
BA_ "GenSigCycleTimeActive" SG_ 2566635616 FasPersonalSettingsButton_rqst_I 100;
BA_ "GenSigStartValue" SG_ 2566635616 FasPersonalSettingsButton_rqst_I 7;
BA_ "GenSigMaxLatency" SG_ 2566635616 FasPersonalSettingsButton_rqst_I 1037;
BA_ "SystemSignalLongSymbol" SG_ 2566635616 FasPersonalSettingsButton_rqst_I "FasPersonalSettingsButton_rqst_ISig_4";
BA_ "GenSigCycleTime" SG_ 2566635616 FasStiffnessCurveSetting_rqst_IS 100;
BA_ "GenSigCycleTimeActive" SG_ 2566635616 FasStiffnessCurveSetting_rqst_IS 100;
BA_ "GenSigStartValue" SG_ 2566635616 FasStiffnessCurveSetting_rqst_IS 31;
BA_ "GenSigMaxLatency" SG_ 2566635616 FasStiffnessCurveSetting_rqst_IS 1037;
BA_ "SystemSignalLongSymbol" SG_ 2566635616 FasStiffnessCurveSetting_rqst_IS "FasStiffnessCurveSetting_rqst_ISig_4";
BA_ "GenSigCycleTime" SG_ 2566635616 ESC_ButtonIndication1 100;
BA_ "GenSigCycleTimeActive" SG_ 2566635616 ESC_ButtonIndication1 100;
BA_ "GenSigMaxLatency" SG_ 2566635616 ESC_ButtonIndication1 1037;
BA_ "GenSigCycleTime" SG_ 2566635616 FasStiffStraightSetting_rqst_ISi 100;
BA_ "GenSigCycleTimeActive" SG_ 2566635616 FasStiffStraightSetting_rqst_ISi 100;
BA_ "GenSigStartValue" SG_ 2566635616 FasStiffStraightSetting_rqst_ISi 31;
BA_ "GenSigMaxLatency" SG_ 2566635616 FasStiffStraightSetting_rqst_ISi 1037;
BA_ "SystemSignalLongSymbol" SG_ 2566635616 FasStiffStraightSetting_rqst_ISi "FasStiffStraightSetting_rqst_ISig_4";
BA_ "GenSigCycleTime" SG_ 2566635616 FasDriver_rqst_ISig_4 100;
BA_ "GenSigCycleTimeActive" SG_ 2566635616 FasDriver_rqst_ISig_4 100;
BA_ "GenSigStartValue" SG_ 2566635616 FasDriver_rqst_ISig_4 15;
BA_ "GenSigMaxLatency" SG_ 2566635616 FasDriver_rqst_ISig_4 1037;
BA_ "GenSigCycleTime" SG_ 2566635616 FasDampingSetting_rqst_ISig_4 100;
BA_ "GenSigCycleTimeActive" SG_ 2566635616 FasDampingSetting_rqst_ISig_4 100;
BA_ "GenSigStartValue" SG_ 2566635616 FasDampingSetting_rqst_ISig_4 31;
BA_ "GenSigMaxLatency" SG_ 2566635616 FasDampingSetting_rqst_ISig_4 1037;
BA_ "GenSigCycleTime" SG_ 2566635616 ESC_ButtonIndication2_ISig_4 100;
BA_ "GenSigCycleTimeActive" SG_ 2566635616 ESC_ButtonIndication2_ISig_4 100;
BA_ "GenSigMaxLatency" SG_ 2566635616 ESC_ButtonIndication2_ISig_4 1037;
BA_ "GenSigCycleTime" SG_ 2566635616 TCS_ButtonIndication_ISig_4 100;
BA_ "GenSigCycleTimeActive" SG_ 2566635616 TCS_ButtonIndication_ISig_4 100;
BA_ "GenSigMaxLatency" SG_ 2566635616 TCS_ButtonIndication_ISig_4 1037;
BA_ "GenSigCycleTime" SG_ 2566635616 ABS_ButtonIndication_ISig_4 100;
BA_ "GenSigCycleTimeActive" SG_ 2566635616 ABS_ButtonIndication_ISig_4 100;
BA_ "GenSigMaxLatency" SG_ 2566635616 ABS_ButtonIndication_ISig_4 1037;
BA_ "GenSigCycleTime" SG_ 2566635360 ESCOff_DeviceIndication_ISig_4 100;
BA_ "GenSigCycleTimeActive" SG_ 2566635360 ESCOff_DeviceIndication_ISig_4 100;
BA_ "GenSigStartValue" SG_ 2566635360 ESCOff_DeviceIndication_ISig_4 3;
BA_ "GenSigMaxLatency" SG_ 2566635360 ESCOff_DeviceIndication_ISig_4 102;
BA_ "Platform_VMCU1_Sig" SG_ 2566635360 ESCOff_DeviceIndication_ISig_4 1;
BA_ "GenSigCycleTime" SG_ 2566635360 DHCActiveRequest 100;
BA_ "GenSigCycleTimeActive" SG_ 2566635360 DHCActiveRequest 100;
BA_ "GenSigStartValue" SG_ 2566635360 DHCActiveRequest 3;
BA_ "GenSigCycleTime" SG_ 2566635360 RollerBenchGUIDeviceStatus_ISig_ 100;
BA_ "GenSigCycleTimeActive" SG_ 2566635360 RollerBenchGUIDeviceStatus_ISig_ 100;
BA_ "GenSigStartValue" SG_ 2566635360 RollerBenchGUIDeviceStatus_ISig_ 3;
BA_ "GenSigMaxLatency" SG_ 2566635360 RollerBenchGUIDeviceStatus_ISig_ 102;
BA_ "Platform_VMCU1_Sig" SG_ 2566635360 RollerBenchGUIDeviceStatus_ISig_ 1;
BA_ "SystemSignalLongSymbol" SG_ 2566635360 RollerBenchGUIDeviceStatus_ISig_ "RollerBenchGUIDeviceStatus_ISig_4";
BA_ "GenSigCycleTime" SG_ 2566635360 DHCSetSpeedAdjustRequest 100;
BA_ "GenSigCycleTimeActive" SG_ 2566635360 DHCSetSpeedAdjustRequest 100;
BA_ "GenSigStartValue" SG_ 2566635360 DHCSetSpeedAdjustRequest 7;
BA_ "GenSigCycleTime" SG_ 2566635360 AutomaticCMenableStatus_ISig_4 100;
BA_ "GenSigCycleTimeActive" SG_ 2566635360 AutomaticCMenableStatus_ISig_4 100;
BA_ "GenSigStartValue" SG_ 2566635360 AutomaticCMenableStatus_ISig_4 3;
BA_ "GenSigMaxLatency" SG_ 2566635360 AutomaticCMenableStatus_ISig_4 102;
BA_ "Platform_VMCU1_Sig" SG_ 2566635360 AutomaticCMenableStatus_ISig_4 1;
BA_ "GenSigCycleTime" SG_ 2566635360 AFSActiveAllowedInDP_GUIrqst_ISi 100;
BA_ "GenSigCycleTimeActive" SG_ 2566635360 AFSActiveAllowedInDP_GUIrqst_ISi 100;
BA_ "GenSigStartValue" SG_ 2566635360 AFSActiveAllowedInDP_GUIrqst_ISi 3;
BA_ "SystemSignalLongSymbol" SG_ 2566635360 AFSActiveAllowedInDP_GUIrqst_ISi "AFSActiveAllowedInDP_GUIrqst_ISig_4";
BA_ "GenSigSendType" SG_ 2432637476 AdasisMapData_ISig_4 1;
BA_ "GenSigCycleTime" SG_ 2432637476 AdasisMapData_ISig_4 100;
BA_ "GenSigCycleTimeActive" SG_ 2432637476 AdasisMapData_ISig_4 100;
BA_ "Platform_VMCU1_Sig" SG_ 2432637476 AdasisMapData_ISig_4 1;
BA_ "GenSigSendType" SG_ 2566357089 HMIIOM_BB2_36S_FCS 7;
BA_ "Platform_VMCU1_Sig" SG_ 2566357089 HMIIOM_BB2_36S_FCS 1;
BA_ "GenSigSendType" SG_ 2566357088 SEM_DisplayText_stat_ISig_4 1;
BA_ "GenSigMaxLatency" SG_ 2566357088 SEM_DisplayText_stat_ISig_4 170;
BA_ "Platform_VMCU1_Sig" SG_ 2566357088 SEM_DisplayText_stat_ISig_4 1;
BA_ "GenSigSendType" SG_ 2499772257 HMIIOM_BB2_35S_FCS 7;
BA_ "Platform_VMCU1_Sig" SG_ 2499772257 HMIIOM_BB2_35S_FCS 1;
BA_ "GenSigSendType" SG_ 2499772256 MediaSourcesListRsp_sg_UB_ISig_4 7;
BA_ "Platform_VMCU1_Sig" SG_ 2499772256 MediaSourcesListRsp_sg_UB_ISig_4 1;
BA_ "GenSigSendType" SG_ 2499772256 MediaSourcesListRsp_SrcAttrib_IS 1;
BA_ "GenSigMaxLatency" SG_ 2499772256 MediaSourcesListRsp_SrcAttrib_IS 100;
BA_ "NeedsUpdateBit" SG_ 2499772256 MediaSourcesListRsp_SrcAttrib_IS 1;
BA_ "Platform_VMCU1_Sig" SG_ 2499772256 MediaSourcesListRsp_SrcAttrib_IS 1;
BA_ "SystemSignalLongSymbol" SG_ 2499772256 MediaSourcesListRsp_SrcAttrib_IS "MediaSourcesListRsp_SrcAttrib_ISig_4";
BA_ "GenSigSendType" SG_ 2499772256 MediaSourcesListRsp_SInfo_ISig_4 1;
BA_ "GenSigStartValue" SG_ 2499772256 MediaSourcesListRsp_SInfo_ISig_4 3;
BA_ "GenSigMaxLatency" SG_ 2499772256 MediaSourcesListRsp_SInfo_ISig_4 100;
BA_ "NeedsUpdateBit" SG_ 2499772256 MediaSourcesListRsp_SInfo_ISig_4 1;
BA_ "Platform_VMCU1_Sig" SG_ 2499772256 MediaSourcesListRsp_SInfo_ISig_4 1;
BA_ "GenSigSendType" SG_ 2499772256 MediaSourcesListRsp_Name_ISig_4 1;
BA_ "GenSigMaxLatency" SG_ 2499772256 MediaSourcesListRsp_Name_ISig_4 100;
BA_ "NeedsUpdateBit" SG_ 2499772256 MediaSourcesListRsp_Name_ISig_4 1;
BA_ "Platform_VMCU1_Sig" SG_ 2499772256 MediaSourcesListRsp_Name_ISig_4 1;
BA_ "GenSigSendType" SG_ 2499772256 MediaSourcesListRsp_PCI_ISig_4 1;
BA_ "GenSigMaxLatency" SG_ 2499772256 MediaSourcesListRsp_PCI_ISig_4 100;
BA_ "NeedsUpdateBit" SG_ 2499772256 MediaSourcesListRsp_PCI_ISig_4 1;
BA_ "Platform_VMCU1_Sig" SG_ 2499772256 MediaSourcesListRsp_PCI_ISig_4 1;
BA_ "GenSigSendType" SG_ 2499772256 MediaSourcesListRsp_ItemID_ISig_ 1;
BA_ "GenSigMaxLatency" SG_ 2499772256 MediaSourcesListRsp_ItemID_ISig_ 100;
BA_ "NeedsUpdateBit" SG_ 2499772256 MediaSourcesListRsp_ItemID_ISig_ 1;
BA_ "Platform_VMCU1_Sig" SG_ 2499772256 MediaSourcesListRsp_ItemID_ISig_ 1;
BA_ "SystemSignalLongSymbol" SG_ 2499772256 MediaSourcesListRsp_ItemID_ISig_ "MediaSourcesListRsp_ItemID_ISig_4";
BA_ "GenSigSendType" SG_ 2499788640 MediaSourcesListNPRsp_ISig_4 1;
BA_ "GenSigMaxLatency" SG_ 2499788640 MediaSourcesListNPRsp_ISig_4 50;
BA_ "NeedsUpdateBit" SG_ 2499788640 MediaSourcesListNPRsp_ISig_4 1;
BA_ "Platform_VMCU1_Sig" SG_ 2499788640 MediaSourcesListNPRsp_ISig_4 1;
BA_ "GenSigSendType" SG_ 2499788640 MediaSourcesListNPRsp_UB_ISig_4 7;
BA_ "Platform_VMCU1_Sig" SG_ 2499788640 MediaSourcesListNPRsp_UB_ISig_4 1;
BA_ "GenSigCycleTime" SG_ 2477212768 DirInd_StalkStatus_4 100;
BA_ "GenSigCycleTimeActive" SG_ 2477212768 DirInd_StalkStatus_4 100;
BA_ "GenSigStartValue" SG_ 2477212768 DirInd_StalkStatus_4 7;
BA_ "Platform_VMCU1_Sig" SG_ 2477212768 DirInd_StalkStatus_4 1;
BA_ "GenSigCycleTime" SG_ 2477212768 SEMMediaSourceAvail_Source04_ISi 100;
BA_ "GenSigCycleTimeActive" SG_ 2477212768 SEMMediaSourceAvail_Source04_ISi 100;
BA_ "Platform_VMCU1_Sig" SG_ 2477212768 SEMMediaSourceAvail_Source04_ISi 1;
BA_ "SystemSignalLongSymbol" SG_ 2477212768 SEMMediaSourceAvail_Source04_ISi "SEMMediaSourceAvail_Source04_ISig_4";
BA_ "GenSigCycleTime" SG_ 2477212768 SEMMediaSourceAvail_Source10_ISi 100;
BA_ "GenSigCycleTimeActive" SG_ 2477212768 SEMMediaSourceAvail_Source10_ISi 100;
BA_ "Platform_VMCU1_Sig" SG_ 2477212768 SEMMediaSourceAvail_Source10_ISi 1;
BA_ "SystemSignalLongSymbol" SG_ 2477212768 SEMMediaSourceAvail_Source10_ISi "SEMMediaSourceAvail_Source10_ISig_4";
BA_ "GenSigCycleTime" SG_ 2477212768 SEMMediaSourceAvail_SInfo_ISig_4 100;
BA_ "GenSigCycleTimeActive" SG_ 2477212768 SEMMediaSourceAvail_SInfo_ISig_4 100;
BA_ "GenSigStartValue" SG_ 2477212768 SEMMediaSourceAvail_SInfo_ISig_4 3;
BA_ "Platform_VMCU1_Sig" SG_ 2477212768 SEMMediaSourceAvail_SInfo_ISig_4 1;
BA_ "GenSigCycleTime" SG_ 2477212768 SEM_PresetIndicationCmd_ISig_4 100;
BA_ "GenSigCycleTimeActive" SG_ 2477212768 SEM_PresetIndicationCmd_ISig_4 100;
BA_ "GenSigStartValue" SG_ 2477212768 SEM_PresetIndicationCmd_ISig_4 63;
BA_ "Platform_VMCU1_Sig" SG_ 2477212768 SEM_PresetIndicationCmd_ISig_4 1;
BA_ "GenSigCycleTime" SG_ 2477212768 SEMMediaSourceAvail_Source09_ISi 100;
BA_ "GenSigCycleTimeActive" SG_ 2477212768 SEMMediaSourceAvail_Source09_ISi 100;
BA_ "Platform_VMCU1_Sig" SG_ 2477212768 SEMMediaSourceAvail_Source09_ISi 1;
BA_ "SystemSignalLongSymbol" SG_ 2477212768 SEMMediaSourceAvail_Source09_ISi "SEMMediaSourceAvail_Source09_ISig_4";
BA_ "GenSigCycleTime" SG_ 2477212768 SEMMediaSourceAvail_Source12_ISi 100;
BA_ "GenSigCycleTimeActive" SG_ 2477212768 SEMMediaSourceAvail_Source12_ISi 100;
BA_ "Platform_VMCU1_Sig" SG_ 2477212768 SEMMediaSourceAvail_Source12_ISi 1;
BA_ "SystemSignalLongSymbol" SG_ 2477212768 SEMMediaSourceAvail_Source12_ISi "SEMMediaSourceAvail_Source12_ISig_4";
BA_ "GenSigCycleTime" SG_ 2477212768 SEMMediaSourceAvail_Source07_ISi 100;
BA_ "GenSigCycleTimeActive" SG_ 2477212768 SEMMediaSourceAvail_Source07_ISi 100;
BA_ "Platform_VMCU1_Sig" SG_ 2477212768 SEMMediaSourceAvail_Source07_ISi 1;
BA_ "SystemSignalLongSymbol" SG_ 2477212768 SEMMediaSourceAvail_Source07_ISi "SEMMediaSourceAvail_Source07_ISig_4";
BA_ "GenSigCycleTime" SG_ 2477212768 TripmeterReset_rqst1_ISig_4 100;
BA_ "GenSigCycleTimeActive" SG_ 2477212768 TripmeterReset_rqst1_ISig_4 100;
BA_ "GenSigStartValue" SG_ 2477212768 TripmeterReset_rqst1_ISig_4 7;
BA_ "Platform_VMCU1_Sig" SG_ 2477212768 TripmeterReset_rqst1_ISig_4 1;
BA_ "GenSigCycleTime" SG_ 2477212768 SEMMediaSourceAvail_Source03_ISi 100;
BA_ "GenSigCycleTimeActive" SG_ 2477212768 SEMMediaSourceAvail_Source03_ISi 100;
BA_ "Platform_VMCU1_Sig" SG_ 2477212768 SEMMediaSourceAvail_Source03_ISi 1;
BA_ "SystemSignalLongSymbol" SG_ 2477212768 SEMMediaSourceAvail_Source03_ISi "SEMMediaSourceAvail_Source03_ISig_4";
BA_ "GenSigCycleTime" SG_ 2477212768 SEMMediaSourceAvail_Source11_ISi 100;
BA_ "GenSigCycleTimeActive" SG_ 2477212768 SEMMediaSourceAvail_Source11_ISi 100;
BA_ "Platform_VMCU1_Sig" SG_ 2477212768 SEMMediaSourceAvail_Source11_ISi 1;
BA_ "SystemSignalLongSymbol" SG_ 2477212768 SEMMediaSourceAvail_Source11_ISi "SEMMediaSourceAvail_Source11_ISig_4";
BA_ "GenSigCycleTime" SG_ 2477212768 SEM_AudioVolValIndCmd_ISig_4 100;
BA_ "GenSigCycleTimeActive" SG_ 2477212768 SEM_AudioVolValIndCmd_ISig_4 100;
BA_ "Platform_VMCU1_Sig" SG_ 2477212768 SEM_AudioVolValIndCmd_ISig_4 1;
BA_ "GenSigCycleTime" SG_ 2477212768 SEMMediaSourceAvail_Source02_ISi 100;
BA_ "GenSigCycleTimeActive" SG_ 2477212768 SEMMediaSourceAvail_Source02_ISi 100;
BA_ "Platform_VMCU1_Sig" SG_ 2477212768 SEMMediaSourceAvail_Source02_ISi 1;
BA_ "SystemSignalLongSymbol" SG_ 2477212768 SEMMediaSourceAvail_Source02_ISi "SEMMediaSourceAvail_Source02_ISig_4";
BA_ "GenSigCycleTime" SG_ 2477212768 AudioSourceStat_ISig_4 100;
BA_ "GenSigCycleTimeActive" SG_ 2477212768 AudioSourceStat_ISig_4 100;
BA_ "GenSigStartValue" SG_ 2477212768 AudioSourceStat_ISig_4 15;
BA_ "Platform_VMCU1_Sig" SG_ 2477212768 AudioSourceStat_ISig_4 1;
BA_ "GenSigCycleTime" SG_ 2477212768 SEMMediaSourceAvail_Source06_ISi 100;
BA_ "GenSigCycleTimeActive" SG_ 2477212768 SEMMediaSourceAvail_Source06_ISi 100;
BA_ "Platform_VMCU1_Sig" SG_ 2477212768 SEMMediaSourceAvail_Source06_ISi 1;
BA_ "SystemSignalLongSymbol" SG_ 2477212768 SEMMediaSourceAvail_Source06_ISi "SEMMediaSourceAvail_Source06_ISig_4";
BA_ "GenSigCycleTime" SG_ 2477212768 SEMMediaSourceAvail_Source00_ISi 100;
BA_ "GenSigCycleTimeActive" SG_ 2477212768 SEMMediaSourceAvail_Source00_ISi 100;
BA_ "Platform_VMCU1_Sig" SG_ 2477212768 SEMMediaSourceAvail_Source00_ISi 1;
BA_ "SystemSignalLongSymbol" SG_ 2477212768 SEMMediaSourceAvail_Source00_ISi "SEMMediaSourceAvail_Source00_ISig_4";
BA_ "GenSigCycleTime" SG_ 2477212768 SEMMediaSourceAvail_Source01_ISi 100;
BA_ "GenSigCycleTimeActive" SG_ 2477212768 SEMMediaSourceAvail_Source01_ISi 100;
BA_ "Platform_VMCU1_Sig" SG_ 2477212768 SEMMediaSourceAvail_Source01_ISi 1;
BA_ "SystemSignalLongSymbol" SG_ 2477212768 SEMMediaSourceAvail_Source01_ISi "SEMMediaSourceAvail_Source01_ISig_4";
BA_ "GenSigCycleTime" SG_ 2477212768 SEMMediaSourceAvail_Source08_ISi 100;
BA_ "GenSigCycleTimeActive" SG_ 2477212768 SEMMediaSourceAvail_Source08_ISi 100;
BA_ "Platform_VMCU1_Sig" SG_ 2477212768 SEMMediaSourceAvail_Source08_ISi 1;
BA_ "SystemSignalLongSymbol" SG_ 2477212768 SEMMediaSourceAvail_Source08_ISi "SEMMediaSourceAvail_Source08_ISig_4";
BA_ "GenSigCycleTime" SG_ 2477212768 SEM_AudioMuteStat_ISig_4 100;
BA_ "GenSigCycleTimeActive" SG_ 2477212768 SEM_AudioMuteStat_ISig_4 100;
BA_ "GenSigStartValue" SG_ 2477212768 SEM_AudioMuteStat_ISig_4 7;
BA_ "Platform_VMCU1_Sig" SG_ 2477212768 SEM_AudioMuteStat_ISig_4 1;
BA_ "GenSigCycleTime" SG_ 2477212768 SEMMediaSourceAvail_Source13_ISi 100;
BA_ "GenSigCycleTimeActive" SG_ 2477212768 SEMMediaSourceAvail_Source13_ISi 100;
BA_ "Platform_VMCU1_Sig" SG_ 2477212768 SEMMediaSourceAvail_Source13_ISi 1;
BA_ "SystemSignalLongSymbol" SG_ 2477212768 SEMMediaSourceAvail_Source13_ISi "SEMMediaSourceAvail_Source13_ISig_4";
BA_ "GenSigCycleTime" SG_ 2477212768 SEMMediaSourceAvail_Source05_ISi 100;
BA_ "GenSigCycleTimeActive" SG_ 2477212768 SEMMediaSourceAvail_Source05_ISi 100;
BA_ "Platform_VMCU1_Sig" SG_ 2477212768 SEMMediaSourceAvail_Source05_ISi 1;
BA_ "SystemSignalLongSymbol" SG_ 2477212768 SEMMediaSourceAvail_Source05_ISi "SEMMediaSourceAvail_Source05_ISig_4";
BA_ "GenSigCycleTime" SG_ 2565816160 OBDRelDTC_IC_DtcIdB_ISig_4 100;
BA_ "GenSigCycleTimeActive" SG_ 2565816160 OBDRelDTC_IC_DtcIdB_ISig_4 100;
BA_ "GenSigMaxLatency" SG_ 2565816160 OBDRelDTC_IC_DtcIdB_ISig_4 97;
BA_ "NeedsUpdateBit" SG_ 2565816160 OBDRelDTC_IC_DtcIdB_ISig_4 1;
BA_ "Platform_VMCU1_Sig" SG_ 2565816160 OBDRelDTC_IC_DtcIdB_ISig_4 1;
BA_ "GenSigCycleTime" SG_ 2565816160 OBDRelDTC_IC_FailTB_ISig_4 100;
BA_ "GenSigCycleTimeActive" SG_ 2565816160 OBDRelDTC_IC_FailTB_ISig_4 100;
BA_ "GenSigMaxLatency" SG_ 2565816160 OBDRelDTC_IC_FailTB_ISig_4 97;
BA_ "NeedsUpdateBit" SG_ 2565816160 OBDRelDTC_IC_FailTB_ISig_4 1;
BA_ "Platform_VMCU1_Sig" SG_ 2565816160 OBDRelDTC_IC_FailTB_ISig_4 1;
BA_ "GenSigCycleTime" SG_ 2565816160 OBDRelDTC_IC_DtcIdA_ISig_4 100;
BA_ "GenSigCycleTimeActive" SG_ 2565816160 OBDRelDTC_IC_DtcIdA_ISig_4 100;
BA_ "GenSigMaxLatency" SG_ 2565816160 OBDRelDTC_IC_DtcIdA_ISig_4 97;
BA_ "NeedsUpdateBit" SG_ 2565816160 OBDRelDTC_IC_DtcIdA_ISig_4 1;
BA_ "Platform_VMCU1_Sig" SG_ 2565816160 OBDRelDTC_IC_DtcIdA_ISig_4 1;
BA_ "GenSigCycleTime" SG_ 2565816160 OBDRelDTC_IC_EvalStatA_ISig_4 100;
BA_ "GenSigCycleTimeActive" SG_ 2565816160 OBDRelDTC_IC_EvalStatA_ISig_4 100;
BA_ "GenSigStartValue" SG_ 2565816160 OBDRelDTC_IC_EvalStatA_ISig_4 3;
BA_ "GenSigMaxLatency" SG_ 2565816160 OBDRelDTC_IC_EvalStatA_ISig_4 97;
BA_ "NeedsUpdateBit" SG_ 2565816160 OBDRelDTC_IC_EvalStatA_ISig_4 1;
BA_ "Platform_VMCU1_Sig" SG_ 2565816160 OBDRelDTC_IC_EvalStatA_ISig_4 1;
BA_ "GenSigSendType" SG_ 2565816160 OBDRelDTC_IC_sg_UB_ISig_4 7;
BA_ "Platform_VMCU1_Sig" SG_ 2565816160 OBDRelDTC_IC_sg_UB_ISig_4 1;
BA_ "GenSigCycleTime" SG_ 2565816160 OBDRelDTC_IC_EvalResultB_ISig_4 100;
BA_ "GenSigCycleTimeActive" SG_ 2565816160 OBDRelDTC_IC_EvalResultB_ISig_4 100;
BA_ "GenSigStartValue" SG_ 2565816160 OBDRelDTC_IC_EvalResultB_ISig_4 3;
BA_ "GenSigMaxLatency" SG_ 2565816160 OBDRelDTC_IC_EvalResultB_ISig_4 97;
BA_ "NeedsUpdateBit" SG_ 2565816160 OBDRelDTC_IC_EvalResultB_ISig_4 1;
BA_ "Platform_VMCU1_Sig" SG_ 2565816160 OBDRelDTC_IC_EvalResultB_ISig_4 1;
BA_ "GenSigCycleTime" SG_ 2565816160 OBDRelDTC_IC_EvalResultA_ISig_4 100;
BA_ "GenSigCycleTimeActive" SG_ 2565816160 OBDRelDTC_IC_EvalResultA_ISig_4 100;
BA_ "GenSigStartValue" SG_ 2565816160 OBDRelDTC_IC_EvalResultA_ISig_4 3;
BA_ "GenSigMaxLatency" SG_ 2565816160 OBDRelDTC_IC_EvalResultA_ISig_4 97;
BA_ "NeedsUpdateBit" SG_ 2565816160 OBDRelDTC_IC_EvalResultA_ISig_4 1;
BA_ "Platform_VMCU1_Sig" SG_ 2565816160 OBDRelDTC_IC_EvalResultA_ISig_4 1;
BA_ "GenSigCycleTime" SG_ 2565816160 OBDRelDTC_IC_DrvngCycleB_ISig_4 100;
BA_ "GenSigCycleTimeActive" SG_ 2565816160 OBDRelDTC_IC_DrvngCycleB_ISig_4 100;
BA_ "GenSigStartValue" SG_ 2565816160 OBDRelDTC_IC_DrvngCycleB_ISig_4 3;
BA_ "GenSigMaxLatency" SG_ 2565816160 OBDRelDTC_IC_DrvngCycleB_ISig_4 97;
BA_ "NeedsUpdateBit" SG_ 2565816160 OBDRelDTC_IC_DrvngCycleB_ISig_4 1;
BA_ "Platform_VMCU1_Sig" SG_ 2565816160 OBDRelDTC_IC_DrvngCycleB_ISig_4 1;
BA_ "GenSigCycleTime" SG_ 2565816160 OBDRelDTC_IC_DrvngCycleA_ISig_4 100;
BA_ "GenSigCycleTimeActive" SG_ 2565816160 OBDRelDTC_IC_DrvngCycleA_ISig_4 100;
BA_ "GenSigStartValue" SG_ 2565816160 OBDRelDTC_IC_DrvngCycleA_ISig_4 3;
BA_ "GenSigMaxLatency" SG_ 2565816160 OBDRelDTC_IC_DrvngCycleA_ISig_4 97;
BA_ "NeedsUpdateBit" SG_ 2565816160 OBDRelDTC_IC_DrvngCycleA_ISig_4 1;
BA_ "Platform_VMCU1_Sig" SG_ 2565816160 OBDRelDTC_IC_DrvngCycleA_ISig_4 1;
BA_ "GenSigCycleTime" SG_ 2565816160 OBDRelDTC_IC_EvalStatB_ISig_4 100;
BA_ "GenSigCycleTimeActive" SG_ 2565816160 OBDRelDTC_IC_EvalStatB_ISig_4 100;
BA_ "GenSigStartValue" SG_ 2565816160 OBDRelDTC_IC_EvalStatB_ISig_4 3;
BA_ "GenSigMaxLatency" SG_ 2565816160 OBDRelDTC_IC_EvalStatB_ISig_4 97;
BA_ "NeedsUpdateBit" SG_ 2565816160 OBDRelDTC_IC_EvalStatB_ISig_4 1;
BA_ "Platform_VMCU1_Sig" SG_ 2565816160 OBDRelDTC_IC_EvalStatB_ISig_4 1;
BA_ "GenSigCycleTime" SG_ 2565816160 OBDRelDTC_IC_FailTA_ISig_4 100;
BA_ "GenSigCycleTimeActive" SG_ 2565816160 OBDRelDTC_IC_FailTA_ISig_4 100;
BA_ "GenSigMaxLatency" SG_ 2565816160 OBDRelDTC_IC_FailTA_ISig_4 97;
BA_ "NeedsUpdateBit" SG_ 2565816160 OBDRelDTC_IC_FailTA_ISig_4 1;
BA_ "Platform_VMCU1_Sig" SG_ 2565816160 OBDRelDTC_IC_FailTA_ISig_4 1;
BA_ "GenSigCycleTime" SG_ 2565848928 OBDRelDTC_HMIIOM_DtcIdB 100;
BA_ "GenSigCycleTimeActive" SG_ 2565848928 OBDRelDTC_HMIIOM_DtcIdB 100;
BA_ "GenSigMaxLatency" SG_ 2565848928 OBDRelDTC_HMIIOM_DtcIdB 98;
BA_ "Platform_VMCU1_Sig" SG_ 2565848928 OBDRelDTC_HMIIOM_DtcIdB 1;
BA_ "GenSigCycleTime" SG_ 2565848928 OBDRelDTC_HMIIOM_EvalResultB 100;
BA_ "GenSigCycleTimeActive" SG_ 2565848928 OBDRelDTC_HMIIOM_EvalResultB 100;
BA_ "GenSigStartValue" SG_ 2565848928 OBDRelDTC_HMIIOM_EvalResultB 3;
BA_ "GenSigMaxLatency" SG_ 2565848928 OBDRelDTC_HMIIOM_EvalResultB 98;
BA_ "Platform_VMCU1_Sig" SG_ 2565848928 OBDRelDTC_HMIIOM_EvalResultB 1;
BA_ "GenSigCycleTime" SG_ 2565848928 OBDRelDTC_HMIIOM_EvalStatB 100;
BA_ "GenSigCycleTimeActive" SG_ 2565848928 OBDRelDTC_HMIIOM_EvalStatB 100;
BA_ "GenSigStartValue" SG_ 2565848928 OBDRelDTC_HMIIOM_EvalStatB 3;
BA_ "GenSigMaxLatency" SG_ 2565848928 OBDRelDTC_HMIIOM_EvalStatB 98;
BA_ "Platform_VMCU1_Sig" SG_ 2565848928 OBDRelDTC_HMIIOM_EvalStatB 1;
BA_ "GenSigCycleTime" SG_ 2565848928 OBDRelDTC_HMIIOM_DtcIdA 100;
BA_ "GenSigCycleTimeActive" SG_ 2565848928 OBDRelDTC_HMIIOM_DtcIdA 100;
BA_ "GenSigMaxLatency" SG_ 2565848928 OBDRelDTC_HMIIOM_DtcIdA 98;
BA_ "Platform_VMCU1_Sig" SG_ 2565848928 OBDRelDTC_HMIIOM_DtcIdA 1;
BA_ "GenSigCycleTime" SG_ 2565848928 OBDRelDTC_HMIIOM_EvalResultA 100;
BA_ "GenSigCycleTimeActive" SG_ 2565848928 OBDRelDTC_HMIIOM_EvalResultA 100;
BA_ "GenSigStartValue" SG_ 2565848928 OBDRelDTC_HMIIOM_EvalResultA 3;
BA_ "GenSigMaxLatency" SG_ 2565848928 OBDRelDTC_HMIIOM_EvalResultA 98;
BA_ "Platform_VMCU1_Sig" SG_ 2565848928 OBDRelDTC_HMIIOM_EvalResultA 1;
BA_ "GenSigCycleTime" SG_ 2565848928 OBDRelDTC_HMIIOM_DrvngCycleA 100;
BA_ "GenSigCycleTimeActive" SG_ 2565848928 OBDRelDTC_HMIIOM_DrvngCycleA 100;
BA_ "GenSigStartValue" SG_ 2565848928 OBDRelDTC_HMIIOM_DrvngCycleA 3;
BA_ "GenSigMaxLatency" SG_ 2565848928 OBDRelDTC_HMIIOM_DrvngCycleA 98;
BA_ "Platform_VMCU1_Sig" SG_ 2565848928 OBDRelDTC_HMIIOM_DrvngCycleA 1;
BA_ "GenSigCycleTime" SG_ 2565848928 OBDRelDTC_HMIIOM_FailTB 100;
BA_ "GenSigCycleTimeActive" SG_ 2565848928 OBDRelDTC_HMIIOM_FailTB 100;
BA_ "GenSigMaxLatency" SG_ 2565848928 OBDRelDTC_HMIIOM_FailTB 98;
BA_ "Platform_VMCU1_Sig" SG_ 2565848928 OBDRelDTC_HMIIOM_FailTB 1;
BA_ "GenSigCycleTime" SG_ 2565848928 OBDRelDTC_HMIIOM_EvalStatA 100;
BA_ "GenSigCycleTimeActive" SG_ 2565848928 OBDRelDTC_HMIIOM_EvalStatA 100;
BA_ "GenSigStartValue" SG_ 2565848928 OBDRelDTC_HMIIOM_EvalStatA 3;
BA_ "GenSigMaxLatency" SG_ 2565848928 OBDRelDTC_HMIIOM_EvalStatA 98;
BA_ "Platform_VMCU1_Sig" SG_ 2565848928 OBDRelDTC_HMIIOM_EvalStatA 1;
BA_ "GenSigCycleTime" SG_ 2565848928 OBDRelDTC_HMIIOM_FailTA 100;
BA_ "GenSigCycleTimeActive" SG_ 2565848928 OBDRelDTC_HMIIOM_FailTA 100;
BA_ "GenSigMaxLatency" SG_ 2565848928 OBDRelDTC_HMIIOM_FailTA 98;
BA_ "Platform_VMCU1_Sig" SG_ 2565848928 OBDRelDTC_HMIIOM_FailTA 1;
BA_ "GenSigCycleTime" SG_ 2565848928 OBDRelDTC_HMIIOM_DrvngCycleB 100;
BA_ "GenSigCycleTimeActive" SG_ 2565848928 OBDRelDTC_HMIIOM_DrvngCycleB 100;
BA_ "GenSigStartValue" SG_ 2565848928 OBDRelDTC_HMIIOM_DrvngCycleB 3;
BA_ "GenSigMaxLatency" SG_ 2565848928 OBDRelDTC_HMIIOM_DrvngCycleB 98;
BA_ "Platform_VMCU1_Sig" SG_ 2565848928 OBDRelDTC_HMIIOM_DrvngCycleB 1;
BA_ "GenSigSendType" SG_ 2565494624 TPMPosOfWMReq_sg_UB_ISig_4 7;
BA_ "GenSigCycleTime" SG_ 2565494624 TPMPosOfWMReq_sg_UB_ISig_4 100;
BA_ "GenSigCycleTimeActive" SG_ 2565494624 TPMPosOfWMReq_sg_UB_ISig_4 100;
BA_ "Platform_VMCU1_Sig" SG_ 2565494624 TPMPosOfWMReq_sg_UB_ISig_4 1;
BA_ "GenSigCycleTime" SG_ 2565494624 TPMUnmateTrailerReq_ISig_4 100;
BA_ "GenSigCycleTimeActive" SG_ 2565494624 TPMUnmateTrailerReq_ISig_4 100;
BA_ "GenSigStartValue" SG_ 2565494624 TPMUnmateTrailerReq_ISig_4 3;
BA_ "NeedsUpdateBit" SG_ 2565494624 TPMUnmateTrailerReq_ISig_4 1;
BA_ "Platform_VMCU1_Sig" SG_ 2565494624 TPMUnmateTrailerReq_ISig_4 1;
BA_ "GenSigCycleTime" SG_ 2565494624 TPMSetAxleRefPres_Axle4_ISig_4 100;
BA_ "GenSigCycleTimeActive" SG_ 2565494624 TPMSetAxleRefPres_Axle4_ISig_4 100;
BA_ "GenSigStartValue" SG_ 2565494624 TPMSetAxleRefPres_Axle4_ISig_4 255;
BA_ "NeedsUpdateBit" SG_ 2565494624 TPMSetAxleRefPres_Axle4_ISig_4 1;
BA_ "Platform_VMCU1_Sig" SG_ 2565494624 TPMSetAxleRefPres_Axle4_ISig_4 1;
BA_ "GenSigSendType" SG_ 2565494624 TPMMateTrailerReq_UB_ISig_4 7;
BA_ "GenSigCycleTime" SG_ 2565494624 TPMMateTrailerReq_UB_ISig_4 100;
BA_ "GenSigCycleTimeActive" SG_ 2565494624 TPMMateTrailerReq_UB_ISig_4 100;
BA_ "Platform_VMCU1_Sig" SG_ 2565494624 TPMMateTrailerReq_UB_ISig_4 1;
BA_ "GenSigSendType" SG_ 2565494624 TPMSetAxleRefPres_sg_UB_ISig_4 7;
BA_ "GenSigCycleTime" SG_ 2565494624 TPMSetAxleRefPres_sg_UB_ISig_4 100;
BA_ "GenSigCycleTimeActive" SG_ 2565494624 TPMSetAxleRefPres_sg_UB_ISig_4 100;
BA_ "Platform_VMCU1_Sig" SG_ 2565494624 TPMSetAxleRefPres_sg_UB_ISig_4 1;
BA_ "GenSigCycleTime" SG_ 2565494624 TPMPosOfWMReq_VehiclePos_ISig_4 100;
BA_ "GenSigCycleTimeActive" SG_ 2565494624 TPMPosOfWMReq_VehiclePos_ISig_4 100;
BA_ "GenSigStartValue" SG_ 2565494624 TPMPosOfWMReq_VehiclePos_ISig_4 7;
BA_ "NeedsUpdateBit" SG_ 2565494624 TPMPosOfWMReq_VehiclePos_ISig_4 1;
BA_ "Platform_VMCU1_Sig" SG_ 2565494624 TPMPosOfWMReq_VehiclePos_ISig_4 1;
BA_ "GenSigCycleTime" SG_ 2565494624 TPMSetAxleRefPres_Axle1_ISig_4 100;
BA_ "GenSigCycleTimeActive" SG_ 2565494624 TPMSetAxleRefPres_Axle1_ISig_4 100;
BA_ "GenSigStartValue" SG_ 2565494624 TPMSetAxleRefPres_Axle1_ISig_4 255;
BA_ "NeedsUpdateBit" SG_ 2565494624 TPMSetAxleRefPres_Axle1_ISig_4 1;
BA_ "Platform_VMCU1_Sig" SG_ 2565494624 TPMSetAxleRefPres_Axle1_ISig_4 1;
BA_ "GenSigCycleTime" SG_ 2565494624 TPMSetAxleRefPres_Axle2_ISig_4 100;
BA_ "GenSigCycleTimeActive" SG_ 2565494624 TPMSetAxleRefPres_Axle2_ISig_4 100;
BA_ "GenSigStartValue" SG_ 2565494624 TPMSetAxleRefPres_Axle2_ISig_4 255;
BA_ "NeedsUpdateBit" SG_ 2565494624 TPMSetAxleRefPres_Axle2_ISig_4 1;
BA_ "Platform_VMCU1_Sig" SG_ 2565494624 TPMSetAxleRefPres_Axle2_ISig_4 1;
BA_ "GenSigCycleTime" SG_ 2565494624 TPMSetAxleRefPres_Axle3_ISig_4 100;
BA_ "GenSigCycleTimeActive" SG_ 2565494624 TPMSetAxleRefPres_Axle3_ISig_4 100;
BA_ "GenSigStartValue" SG_ 2565494624 TPMSetAxleRefPres_Axle3_ISig_4 255;
BA_ "NeedsUpdateBit" SG_ 2565494624 TPMSetAxleRefPres_Axle3_ISig_4 1;
BA_ "Platform_VMCU1_Sig" SG_ 2565494624 TPMSetAxleRefPres_Axle3_ISig_4 1;
BA_ "GenSigCycleTime" SG_ 2565494624 TPMMateTrailerReq_ISig_4 100;
BA_ "GenSigCycleTimeActive" SG_ 2565494624 TPMMateTrailerReq_ISig_4 100;
BA_ "GenSigStartValue" SG_ 2565494624 TPMMateTrailerReq_ISig_4 3;
BA_ "NeedsUpdateBit" SG_ 2565494624 TPMMateTrailerReq_ISig_4 1;
BA_ "Platform_VMCU1_Sig" SG_ 2565494624 TPMMateTrailerReq_ISig_4 1;
BA_ "GenSigCycleTime" SG_ 2565494624 TPMPosOfWMReq_TireId_ISig_4 100;
BA_ "GenSigCycleTimeActive" SG_ 2565494624 TPMPosOfWMReq_TireId_ISig_4 100;
BA_ "NeedsUpdateBit" SG_ 2565494624 TPMPosOfWMReq_TireId_ISig_4 1;
BA_ "Platform_VMCU1_Sig" SG_ 2565494624 TPMPosOfWMReq_TireId_ISig_4 1;
BA_ "GenSigSendType" SG_ 2565494624 TPMUnmateTrailerReq_UB_ISig_4 7;
BA_ "GenSigCycleTime" SG_ 2565494624 TPMUnmateTrailerReq_UB_ISig_4 100;
BA_ "GenSigCycleTimeActive" SG_ 2565494624 TPMUnmateTrailerReq_UB_ISig_4 100;
BA_ "Platform_VMCU1_Sig" SG_ 2565494624 TPMUnmateTrailerReq_UB_ISig_4 1;
BA_ "GenSigCycleTime" SG_ 2565494624 TPMSetAxleRefPres_Axle5_ISig_4 100;
BA_ "GenSigCycleTimeActive" SG_ 2565494624 TPMSetAxleRefPres_Axle5_ISig_4 100;
BA_ "GenSigStartValue" SG_ 2565494624 TPMSetAxleRefPres_Axle5_ISig_4 255;
BA_ "NeedsUpdateBit" SG_ 2565494624 TPMSetAxleRefPres_Axle5_ISig_4 1;
BA_ "Platform_VMCU1_Sig" SG_ 2565494624 TPMSetAxleRefPres_Axle5_ISig_4 1;
BA_ "GenSigCycleTime" SG_ 2565494624 TPMSetAxleRefPres_VehiclePos_ISi 100;
BA_ "GenSigCycleTimeActive" SG_ 2565494624 TPMSetAxleRefPres_VehiclePos_ISi 100;
BA_ "GenSigStartValue" SG_ 2565494624 TPMSetAxleRefPres_VehiclePos_ISi 7;
BA_ "NeedsUpdateBit" SG_ 2565494624 TPMSetAxleRefPres_VehiclePos_ISi 1;
BA_ "Platform_VMCU1_Sig" SG_ 2565494624 TPMSetAxleRefPres_VehiclePos_ISi 1;
BA_ "SystemSignalLongSymbol" SG_ 2565494624 TPMSetAxleRefPres_VehiclePos_ISi "TPMSetAxleRefPres_VehiclePos_ISig_4";
BA_REL_ "GenSigFirstTimeoutTime" BU_SG_REL_ HMIIOM SG_ 2432645412 LiftAxle2LiftFuncSelected_ISig_4 3000;
BA_REL_ "GenSigTimeoutTime" BU_SG_REL_ HMIIOM SG_ 2432645412 LiftAxle2LiftFuncSelected_ISig_4 150;
BA_REL_ "GenSigFirstTimeoutTime" BU_SG_REL_ CIOM SG_ 2432645412 StopLevelChangeAck_ISig_4 3000;
BA_REL_ "GenSigTimeoutTime" BU_SG_REL_ CIOM SG_ 2432645412 StopLevelChangeAck_ISig_4 150;
BA_REL_ "GenSigFirstTimeoutTime" BU_SG_REL_ CIOM SG_ 2432645412 HeightAdjustmentAllowed_ISig_4 3000;
BA_REL_ "GenSigTimeoutTime" BU_SG_REL_ CIOM SG_ 2432645412 HeightAdjustmentAllowed_ISig_4 150;
BA_REL_ "GenSigFirstTimeoutTime" BU_SG_REL_ CIOM SG_ 2432645412 LiftAxle2UpRequestACK_ISig_4 3000;
BA_REL_ "GenSigTimeoutTime" BU_SG_REL_ CIOM SG_ 2432645412 LiftAxle2UpRequestACK_ISig_4 150;
BA_REL_ "GenSigFirstTimeoutTime" BU_SG_REL_ HMIIOM SG_ 2432645412 LiftAxle2UpRequestACK_ISig_4 3000;
BA_REL_ "GenSigTimeoutTime" BU_SG_REL_ HMIIOM SG_ 2432645412 LiftAxle2UpRequestACK_ISig_4 150;
BA_REL_ "GenSigFirstTimeoutTime" BU_SG_REL_ HMIIOM SG_ 2432645412 RideHeightStatus_ISig_4 3000;
BA_REL_ "GenSigTimeoutTime" BU_SG_REL_ HMIIOM SG_ 2432645412 RideHeightStatus_ISig_4 150;
BA_REL_ "GenSigFirstTimeoutTime" BU_SG_REL_ CIOM SG_ 2432645412 RideHeightStatus_ISig_4 3000;
BA_REL_ "GenSigTimeoutTime" BU_SG_REL_ CIOM SG_ 2432645412 RideHeightStatus_ISig_4 150;
BA_REL_ "GenSigFirstTimeoutTime" BU_SG_REL_ BBM SG_ 2432645412 RideHeightStatus_ISig_4 3000;
BA_REL_ "GenSigTimeoutTime" BU_SG_REL_ BBM SG_ 2432645412 RideHeightStatus_ISig_4 150;
BA_REL_ "GenSigFirstTimeoutTime" BU_SG_REL_ HMIIOM SG_ 2432645412 RideHeightOutsideTargetRange_ISi 3000;
BA_REL_ "GenSigTimeoutTime" BU_SG_REL_ HMIIOM SG_ 2432645412 RideHeightOutsideTargetRange_ISi 150;
BA_REL_ "GenSigFirstTimeoutTime" BU_SG_REL_ CIOM SG_ 2432645412 RideHeightOutsideTargetRange_ISi 3000;
BA_REL_ "GenSigTimeoutTime" BU_SG_REL_ CIOM SG_ 2432645412 RideHeightOutsideTargetRange_ISi 150;
BA_REL_ "GenSigFirstTimeoutTime" BU_SG_REL_ CIOM SG_ 2432645412 LoadDistributionFuncSelected_ISi 3000;
BA_REL_ "GenSigTimeoutTime" BU_SG_REL_ CIOM SG_ 2432645412 LoadDistributionFuncSelected_ISi 150;
BA_REL_ "GenSigFirstTimeoutTime" BU_SG_REL_ CIOM SG_ 2432645412 RideHeightStorageAck_ISig_4 3000;
BA_REL_ "GenSigTimeoutTime" BU_SG_REL_ CIOM SG_ 2432645412 RideHeightStorageAck_ISig_4 150;
BA_REL_ "GenSigFirstTimeoutTime" BU_SG_REL_ HMIIOM SG_ 2432645412 LiftAxle2LowerACK_ISig_4 3000;
BA_REL_ "GenSigTimeoutTime" BU_SG_REL_ HMIIOM SG_ 2432645412 LiftAxle2LowerACK_ISig_4 150;
BA_REL_ "GenSigFirstTimeoutTime" BU_SG_REL_ HMIIOM SG_ 2432645412 LiftAxle1UpRequestACK_ISig_4 3000;
BA_REL_ "GenSigTimeoutTime" BU_SG_REL_ HMIIOM SG_ 2432645412 LiftAxle1UpRequestACK_ISig_4 150;
BA_REL_ "GenSigFirstTimeoutTime" BU_SG_REL_ CIOM SG_ 2432645412 LiftAxle1UpRequestACK_ISig_4 3000;
BA_REL_ "GenSigTimeoutTime" BU_SG_REL_ CIOM SG_ 2432645412 LiftAxle1UpRequestACK_ISig_4 150;
BA_REL_ "GenSigFirstTimeoutTime" BU_SG_REL_ BBM SG_ 2432645412 LiftAxle1PositionStatus_ISig_4 3000;
BA_REL_ "GenSigTimeoutTime" BU_SG_REL_ BBM SG_ 2432645412 LiftAxle1PositionStatus_ISig_4 150;
BA_REL_ "GenSigFirstTimeoutTime" BU_SG_REL_ CIOM SG_ 2432645412 LiftAxle1PositionStatus_ISig_4 3000;
BA_REL_ "GenSigTimeoutTime" BU_SG_REL_ CIOM SG_ 2432645412 LiftAxle1PositionStatus_ISig_4 150;
BA_REL_ "GenSigFirstTimeoutTime" BU_SG_REL_ TECU SG_ 2432645412 LiftAxle1PositionStatus_ISig_4 3000;
BA_REL_ "GenSigTimeoutTime" BU_SG_REL_ TECU SG_ 2432645412 LiftAxle1PositionStatus_ISig_4 600;
BA_REL_ "GenSigFirstTimeoutTime" BU_SG_REL_ DACU SG_ 2432645412 LiftAxle1PositionStatus_ISig_4 3000;
BA_REL_ "GenSigTimeoutTime" BU_SG_REL_ DACU SG_ 2432645412 LiftAxle1PositionStatus_ISig_4 600;
BA_REL_ "GenSigFirstTimeoutTime" BU_SG_REL_ HMIIOM SG_ 2432645412 LiftAxle1PositionStatus_ISig_4 3000;
BA_REL_ "GenSigTimeoutTime" BU_SG_REL_ HMIIOM SG_ 2432645412 LiftAxle1PositionStatus_ISig_4 150;
BA_REL_ "GenSigFirstTimeoutTime" BU_SG_REL_ HMIIOM SG_ 2432645412 LiftAxle2AutoLiftSelected_ISig_4 3000;
BA_REL_ "GenSigTimeoutTime" BU_SG_REL_ HMIIOM SG_ 2432645412 LiftAxle2AutoLiftSelected_ISig_4 150;
BA_REL_ "GenSigFirstTimeoutTime" BU_SG_REL_ HMIIOM SG_ 2432645412 LiftAxle1LowerACK_ISig_4 3000;
BA_REL_ "GenSigTimeoutTime" BU_SG_REL_ HMIIOM SG_ 2432645412 LiftAxle1LowerACK_ISig_4 150;
BA_REL_ "GenSigFirstTimeoutTime" BU_SG_REL_ HMIIOM SG_ 2432645412 LiftAxle2PositionStatus_ISig_4 3000;
BA_REL_ "GenSigTimeoutTime" BU_SG_REL_ HMIIOM SG_ 2432645412 LiftAxle2PositionStatus_ISig_4 150;
BA_REL_ "GenSigFirstTimeoutTime" BU_SG_REL_ BBM SG_ 2432645412 LiftAxle2PositionStatus_ISig_4 3000;
BA_REL_ "GenSigTimeoutTime" BU_SG_REL_ BBM SG_ 2432645412 LiftAxle2PositionStatus_ISig_4 150;
BA_REL_ "GenSigFirstTimeoutTime" BU_SG_REL_ CIOM SG_ 2432645412 LiftAxle2PositionStatus_ISig_4 3000;
BA_REL_ "GenSigTimeoutTime" BU_SG_REL_ CIOM SG_ 2432645412 LiftAxle2PositionStatus_ISig_4 150;
BA_REL_ "GenSigFirstTimeoutTime" BU_SG_REL_ TECU SG_ 2432645412 LevelControlInformation_ISig_4 3000;
BA_REL_ "GenSigTimeoutTime" BU_SG_REL_ TECU SG_ 2432645412 LevelControlInformation_ISig_4 500;
BA_REL_ "GenSigFirstTimeoutTime" BU_SG_REL_ HMIIOM SG_ 2432645412 LevelControlInformation_ISig_4 3000;
BA_REL_ "GenSigTimeoutTime" BU_SG_REL_ HMIIOM SG_ 2432645412 LevelControlInformation_ISig_4 500;
BA_REL_ "GenSigFirstTimeoutTime" BU_SG_REL_ CIOM SG_ 2432645412 LevelControlInformation_ISig_4 3000;
BA_REL_ "GenSigTimeoutTime" BU_SG_REL_ CIOM SG_ 2432645412 LevelControlInformation_ISig_4 500;
BA_REL_ "GenSigFirstTimeoutTime" BU_SG_REL_ HMIIOM SG_ 2432645412 LoadDistributionChangeACK_ISig_4 3000;
BA_REL_ "GenSigTimeoutTime" BU_SG_REL_ HMIIOM SG_ 2432645412 LoadDistributionChangeACK_ISig_4 150;
BA_REL_ "GenSigFirstTimeoutTime" BU_SG_REL_ CIOM SG_ 2432645412 LoadDistributionChangeACK_ISig_4 3000;
BA_REL_ "GenSigTimeoutTime" BU_SG_REL_ CIOM SG_ 2432645412 LoadDistributionChangeACK_ISig_4 150;
BA_REL_ "GenSigFirstTimeoutTime" BU_SG_REL_ HMIIOM SG_ 2432645412 LiftAxle1AutoLiftSelected_ISig_4 3000;
BA_REL_ "GenSigTimeoutTime" BU_SG_REL_ HMIIOM SG_ 2432645412 LiftAxle1AutoLiftSelected_ISig_4 150;
BA_REL_ "GenSigFirstTimeoutTime" BU_SG_REL_ HMIIOM SG_ 2432645412 LiftAxle1LiftFuncSelected_ISig_4 3000;
BA_REL_ "GenSigTimeoutTime" BU_SG_REL_ HMIIOM SG_ 2432645412 LiftAxle1LiftFuncSelected_ISig_4 150;
BA_REL_ "GenSigFirstTimeoutTime" BU_SG_REL_ CIOM SG_ 2432645412 RampLevelStorageAck_ISig_4 3000;
BA_REL_ "GenSigTimeoutTime" BU_SG_REL_ CIOM SG_ 2432645412 RampLevelStorageAck_ISig_4 150;
BA_REL_ "GenSigFirstTimeoutTime" BU_SG_REL_ HMIIOM SG_ 2432645412 LoadDistributionSelected_ISig_4 3000;
BA_REL_ "GenSigTimeoutTime" BU_SG_REL_ HMIIOM SG_ 2432645412 LoadDistributionSelected_ISig_4 150;
BA_REL_ "GenSigFirstTimeoutTime" BU_SG_REL_ BBM SG_ 2432645412 LoadDistributionSelected_ISig_4 3000;
BA_REL_ "GenSigTimeoutTime" BU_SG_REL_ BBM SG_ 2432645412 LoadDistributionSelected_ISig_4 150;
BA_REL_ "GenSigFirstTimeoutTime" BU_SG_REL_ CIOM SG_ 2432645412 LoadDistributionSelected_ISig_4 3000;
BA_REL_ "GenSigTimeoutTime" BU_SG_REL_ CIOM SG_ 2432645412 LoadDistributionSelected_ISig_4 150;
BA_REL_ "GenSigFirstTimeoutTime" BU_SG_REL_ HMIIOM SG_ 2432645412 RideHeightFunctionStatus_ISig_4 3000;
BA_REL_ "GenSigTimeoutTime" BU_SG_REL_ HMIIOM SG_ 2432645412 RideHeightFunctionStatus_ISig_4 150;
BA_REL_ "GenSigFirstTimeoutTime" BU_SG_REL_ CIOM SG_ 2432645412 RideHeightFunctionStatus_ISig_4 3000;
BA_REL_ "GenSigTimeoutTime" BU_SG_REL_ CIOM SG_ 2432645412 RideHeightFunctionStatus_ISig_4 150;
BA_REL_ "GenSigFirstTimeoutTime" BU_SG_REL_ HMIIOM SG_ 2432638500 TransmLowRangeSenseSwitch_ISig_4 3000;
BA_REL_ "GenSigTimeoutTime" BU_SG_REL_ HMIIOM SG_ 2432638500 TransmLowRangeSenseSwitch_ISig_4 120;
BA_REL_ "GenSigFirstTimeoutTime" BU_SG_REL_ EMS SG_ 2432638500 TransmLowRangeSenseSwitch_ISig_4 3000;
BA_REL_ "GenSigTimeoutTime" BU_SG_REL_ EMS SG_ 2432638500 TransmLowRangeSenseSwitch_ISig_4 120;
BA_REL_ "GenSigFirstTimeoutTime" BU_SG_REL_ TECU SG_ 2432638500 TransmSystemPowerDown_rqst 3000;
BA_REL_ "GenSigTimeoutTime" BU_SG_REL_ TECU SG_ 2432638500 TransmSystemPowerDown_rqst 500;
BA_REL_ "GenSigFirstTimeoutTime" BU_SG_REL_ BBM SG_ 2432638500 TransmissionNeutralSwitch_ISig_4 3000;
BA_REL_ "GenSigTimeoutTime" BU_SG_REL_ BBM SG_ 2432638500 TransmissionNeutralSwitch_ISig_4 500;
BA_REL_ "GenSigFirstTimeoutTime" BU_SG_REL_ EMS SG_ 2432638500 TransmissionNeutralSwitch_ISig_4 3000;
BA_REL_ "GenSigTimeoutTime" BU_SG_REL_ EMS SG_ 2432638500 TransmissionNeutralSwitch_ISig_4 500;
BA_REL_ "GenSigFirstTimeoutTime" BU_SG_REL_ EMS SG_ 2432638500 SecuredNeutralPosition_ISig_4 3000;
BA_REL_ "GenSigTimeoutTime" BU_SG_REL_ EMS SG_ 2432638500 SecuredNeutralPosition_ISig_4 500;
BA_REL_ "GenSigFirstTimeoutTime" BU_SG_REL_ HMIIOM SG_ 2432638500 SecuredNeutralPosition_ISig_4 3000;
BA_REL_ "GenSigTimeoutTime" BU_SG_REL_ HMIIOM SG_ 2432638500 SecuredNeutralPosition_ISig_4 500;
BA_REL_ "GenSigFirstTimeoutTime" BU_SG_REL_ BBM SG_ 2432638500 SecuredNeutralPosition_ISig_4 6000;
BA_REL_ "GenSigTimeoutTime" BU_SG_REL_ BBM SG_ 2432638500 SecuredNeutralPosition_ISig_4 500;
BA_REL_ "GenSigFirstTimeoutTime" BU_SG_REL_ EMS SG_ 2432638500 EngineStopRequest_ISig_4 3000;
BA_REL_ "GenSigTimeoutTime" BU_SG_REL_ EMS SG_ 2432638500 EngineStopRequest_ISig_4 120;
BA_REL_ "GenSigFirstTimeoutTime" BU_SG_REL_ HMIIOM SG_ 2432638500 DirectionIndicatorLights_rqst_IS 3000;
BA_REL_ "GenSigTimeoutTime" BU_SG_REL_ HMIIOM SG_ 2432638500 DirectionIndicatorLights_rqst_IS 120;
BA_REL_ "GenSigFirstTimeoutTime" BU_SG_REL_ DACU SG_ 2432638500 DirectionIndicatorLights_rqst_IS 3000;
BA_REL_ "GenSigTimeoutTime" BU_SG_REL_ DACU SG_ 2432638500 DirectionIndicatorLights_rqst_IS 120;
BA_REL_ "GenSigFirstTimeoutTime" BU_SG_REL_ DACU SG_ 2432638500 ReverseGearEngaged_ISig_4 3000;
BA_REL_ "GenSigTimeoutTime" BU_SG_REL_ DACU SG_ 2432638500 ReverseGearEngaged_ISig_4 500;
BA_REL_ "GenSigFirstTimeoutTime" BU_SG_REL_ EMS SG_ 2432638500 ReverseGearEngaged_ISig_4 3000;
BA_REL_ "GenSigTimeoutTime" BU_SG_REL_ EMS SG_ 2432638500 ReverseGearEngaged_ISig_4 500;
BA_REL_ "GenSigFirstTimeoutTime" BU_SG_REL_ CIOM SG_ 2432638500 ReverseGearEngaged_ISig_4 3000;
BA_REL_ "GenSigTimeoutTime" BU_SG_REL_ CIOM SG_ 2432638500 ReverseGearEngaged_ISig_4 500;
BA_REL_ "GenSigFirstTimeoutTime" BU_SG_REL_ BBM SG_ 2432638500 ReverseGearEngaged_ISig_4 3000;
BA_REL_ "GenSigTimeoutTime" BU_SG_REL_ BBM SG_ 2432638500 ReverseGearEngaged_ISig_4 500;
BA_REL_ "GenSigFirstTimeoutTime" BU_SG_REL_ HMIIOM SG_ 2432638500 ReverseGearEngaged_ISig_4 3000;
BA_REL_ "GenSigTimeoutTime" BU_SG_REL_ HMIIOM SG_ 2432638500 ReverseGearEngaged_ISig_4 500;
BA_REL_ "GenSigFirstTimeoutTime" BU_SG_REL_ EMS SG_ 2432638500 EngineCrankRequest 3000;
BA_REL_ "GenSigTimeoutTime" BU_SG_REL_ EMS SG_ 2432638500 EngineCrankRequest 120;
BA_REL_ "GenSigFirstTimeoutTime" BU_SG_REL_ VGGSECUSystem SG_ 2432638500 ParkBrakeActuationStatus_ISig_4 3000;
BA_REL_ "GenSigTimeoutTime" BU_SG_REL_ VGGSECUSystem SG_ 2432638500 ParkBrakeActuationStatus_ISig_4 120;
BA_REL_ "GenSigFirstTimeoutTime" BU_SG_REL_ DACU SG_ 2432638500 ParkBrakeActuationStatus_ISig_4 3000;
BA_REL_ "GenSigTimeoutTime" BU_SG_REL_ DACU SG_ 2432638500 ParkBrakeActuationStatus_ISig_4 500;
BA_REL_ "GenSigFirstTimeoutTime" BU_SG_REL_ TECU SG_ 2432638500 ParkBrakeActuationStatus_ISig_4 3000;
BA_REL_ "GenSigTimeoutTime" BU_SG_REL_ TECU SG_ 2432638500 ParkBrakeActuationStatus_ISig_4 500;
BA_REL_ "GenSigFirstTimeoutTime" BU_SG_REL_ BBM SG_ 2432638500 ParkBrakeActuationStatus_ISig_4 3000;
BA_REL_ "GenSigTimeoutTime" BU_SG_REL_ BBM SG_ 2432638500 ParkBrakeActuationStatus_ISig_4 500;
BA_REL_ "GenSigFirstTimeoutTime" BU_SG_REL_ HMIIOM SG_ 2432638500 ParkBrakeActuationStatus_ISig_4 3000;
BA_REL_ "GenSigTimeoutTime" BU_SG_REL_ HMIIOM SG_ 2432638500 ParkBrakeActuationStatus_ISig_4 500;
BA_REL_ "GenSigFirstTimeoutTime" BU_SG_REL_ EMS SG_ 2432638500 EnginePreheat_rqst 3000;
BA_REL_ "GenSigTimeoutTime" BU_SG_REL_ EMS SG_ 2432638500 EnginePreheat_rqst 120;
BA_REL_ "GenSigFirstTimeoutTime" BU_SG_REL_ EMS SG_ 2432638500 AcceleratorPedalPositionBackup 3000;
BA_REL_ "GenSigTimeoutTime" BU_SG_REL_ EMS SG_ 2432638500 AcceleratorPedalPositionBackup 120;
BA_REL_ "GenSigFirstTimeoutTime" BU_SG_REL_ TECU SG_ 2432638500 AcceleratorPedalPositionBackup 3000;
BA_REL_ "GenSigTimeoutTime" BU_SG_REL_ TECU SG_ 2432638500 AcceleratorPedalPositionBackup 120;
BA_REL_ "GenSigFirstTimeoutTime" BU_SG_REL_ VGGSECUSystem SG_ 2432638500 KeyPosition_ISig_4 3000;
BA_REL_ "GenSigTimeoutTime" BU_SG_REL_ VGGSECUSystem SG_ 2432638500 KeyPosition_ISig_4 120;
BA_REL_ "GenSigFirstTimeoutTime" BU_SG_REL_ CIOM SG_ 2432638500 KeyPosition_ISig_4 3000;
BA_REL_ "GenSigTimeoutTime" BU_SG_REL_ CIOM SG_ 2432638500 KeyPosition_ISig_4 120;
BA_REL_ "GenSigFirstTimeoutTime" BU_SG_REL_ HMIIOM SG_ 2432638500 KeyPosition_ISig_4 3000;
BA_REL_ "GenSigTimeoutTime" BU_SG_REL_ HMIIOM SG_ 2432638500 KeyPosition_ISig_4 120;
BA_REL_ "GenSigFirstTimeoutTime" BU_SG_REL_ HMIIOM SG_ 2432638500 GearSplit_Status_ISig_4 3000;
BA_REL_ "GenSigTimeoutTime" BU_SG_REL_ HMIIOM SG_ 2432638500 GearSplit_Status_ISig_4 500;
BA_REL_ "GenSigFirstTimeoutTime" BU_SG_REL_ BBM SG_ 2432638500 GearSplit_Status_ISig_4 3000;
BA_REL_ "GenSigTimeoutTime" BU_SG_REL_ BBM SG_ 2432638500 GearSplit_Status_ISig_4 500;
BA_REL_ "GenSigFirstTimeoutTime" BU_SG_REL_ CIOM SG_ 2432638500 FerryFunctionSwitchChangeACK_ISi 3000;
BA_REL_ "GenSigTimeoutTime" BU_SG_REL_ CIOM SG_ 2432638500 FerryFunctionSwitchChangeACK_ISi 120;
BA_REL_ "GenSigFirstTimeoutTime" BU_SG_REL_ HMIIOM SG_ 2432638500 DirectionIndication_cmd_ISig_4 3000;
BA_REL_ "GenSigTimeoutTime" BU_SG_REL_ HMIIOM SG_ 2432638500 DirectionIndication_cmd_ISig_4 120;
BA_REL_ "GenSigFirstTimeoutTime" BU_SG_REL_ HMIIOM SG_ 2432638500 IdleShutdownWarning_ISig_4 3000;
BA_REL_ "GenSigTimeoutTime" BU_SG_REL_ HMIIOM SG_ 2432638500 IdleShutdownWarning_ISig_4 120;
BA_REL_ "GenSigFirstTimeoutTime" BU_SG_REL_ CIOM SG_ 2432638500 BackToDriveReqACK_ISig_4 3000;
BA_REL_ "GenSigTimeoutTime" BU_SG_REL_ CIOM SG_ 2432638500 BackToDriveReqACK_ISig_4 120;
BA_REL_ "GenSigFirstTimeoutTime" BU_SG_REL_ EMS SG_ 2432638500 EngineSystemPowerDownRequest_ISi 3000;
BA_REL_ "GenSigTimeoutTime" BU_SG_REL_ EMS SG_ 2432638500 EngineSystemPowerDownRequest_ISi 120;
BA_REL_ "GenSigFirstTimeoutTime" BU_SG_REL_ HMIIOM SG_ 2432638500 EngineSystemPowerDownRequest_ISi 3000;
BA_REL_ "GenSigTimeoutTime" BU_SG_REL_ HMIIOM SG_ 2432638500 EngineSystemPowerDownRequest_ISi 120;
BA_REL_ "GenSigFirstTimeoutTime" BU_SG_REL_ EMS SG_ 2511149823 FireAlertCFCSpeedLimit_rqst 3000;
BA_REL_ "GenSigTimeoutTime" BU_SG_REL_ EMS SG_ 2511149823 FireAlertCFCSpeedLimit_rqst 600;
BA_REL_ "GenSigFirstTimeoutTime" BU_SG_REL_ VMCU SG_ 2511149823 ESCReqSilentMode_CtrlTrimValue 3000;
BA_REL_ "GenSigTimeoutTime" BU_SG_REL_ VMCU SG_ 2511149823 ESCReqSilentMode_CtrlTrimValue 600;
BA_REL_ "GenSigFirstTimeoutTime" BU_SG_REL_ VMCU SG_ 2511149823 ESCReqSilentMode_CtrlTrimMode 3000;
BA_REL_ "GenSigTimeoutTime" BU_SG_REL_ VMCU SG_ 2511149823 ESCReqSilentMode_CtrlTrimMode 600;
BA_REL_ "GenSigFirstTimeoutTime" BU_SG_REL_ VMCU SG_ 2511149823 ESCReqSilentMode_CtrlTrimStat 3000;
BA_REL_ "GenSigTimeoutTime" BU_SG_REL_ VMCU SG_ 2511149823 ESCReqSilentMode_CtrlTrimStat 600;
BA_REL_ "GenSigFirstTimeoutTime" BU_SG_REL_ EMS SG_ 2511149823 SilentModeCFCSpeedLimit_rqst 3000;
BA_REL_ "GenSigTimeoutTime" BU_SG_REL_ EMS SG_ 2511149823 SilentModeCFCSpeedLimit_rqst 600;
BA_REL_ "GenSigFirstTimeoutTime" BU_SG_REL_ VMCU SG_ 2511149823 ESCReqSilentMode_CtrlTrimReq 3000;
BA_REL_ "GenSigTimeoutTime" BU_SG_REL_ VMCU SG_ 2511149823 ESCReqSilentMode_CtrlTrimReq 600;
BA_REL_ "GenSigFirstTimeoutTime" BU_SG_REL_ HMIIOM SG_ 2549028632 OilLevelDrvInstr_IncorrEngSpe_IS 12000;
BA_REL_ "GenSigTimeoutTime" BU_SG_REL_ HMIIOM SG_ 2549028632 OilLevelDrvInstr_IncorrEngSpe_IS 3000;
BA_REL_ "GenSigFirstTimeoutTime" BU_SG_REL_ HMIIOM SG_ 2549028632 OilLevelDrvInstr_StopVehicle_ISi 12000;
BA_REL_ "GenSigTimeoutTime" BU_SG_REL_ HMIIOM SG_ 2549028632 OilLevelDrvInstr_StopVehicle_ISi 3000;
BA_REL_ "GenSigFirstTimeoutTime" BU_SG_REL_ HMIIOM SG_ 2549028632 HillDataCtrlTECU_State_ISig_4 12000;
BA_REL_ "GenSigTimeoutTime" BU_SG_REL_ HMIIOM SG_ 2549028632 HillDataCtrlTECU_State_ISig_4 3000;
BA_REL_ "GenSigFirstTimeoutTime" BU_SG_REL_ HMIIOM SG_ 2549028632 OilLevelDrvInstr_Wait60SecTxt_IS 12000;
BA_REL_ "GenSigTimeoutTime" BU_SG_REL_ HMIIOM SG_ 2549028632 OilLevelDrvInstr_Wait60SecTxt_IS 3000;
BA_REL_ "GenSigFirstTimeoutTime" BU_SG_REL_ HMIIOM SG_ 2549028632 ClutchAbuseStatus_ISig_4 12000;
BA_REL_ "GenSigTimeoutTime" BU_SG_REL_ HMIIOM SG_ 2549028632 ClutchAbuseStatus_ISig_4 3000;
BA_REL_ "GenSigFirstTimeoutTime" BU_SG_REL_ HMIIOM SG_ 2549028632 TransmissionSplitboxPTOMode_ISig 12000;
BA_REL_ "GenSigTimeoutTime" BU_SG_REL_ HMIIOM SG_ 2549028632 TransmissionSplitboxPTOMode_ISig 3000;
BA_REL_ "GenSigFirstTimeoutTime" BU_SG_REL_ VMCU SG_ 2549028632 SchwungStatus 12000;
BA_REL_ "GenSigTimeoutTime" BU_SG_REL_ VMCU SG_ 2549028632 SchwungStatus 3000;
BA_REL_ "GenSigFirstTimeoutTime" BU_SG_REL_ HMIIOM SG_ 2549028632 ClutchCalibration_stat 12000;
BA_REL_ "GenSigTimeoutTime" BU_SG_REL_ HMIIOM SG_ 2549028632 ClutchCalibration_stat 3000;
BA_REL_ "GenSigFirstTimeoutTime" BU_SG_REL_ HMIIOM SG_ 2549028632 OilLevelDrvInstr_ChangeGearTxt_I 12000;
BA_REL_ "GenSigTimeoutTime" BU_SG_REL_ HMIIOM SG_ 2549028632 OilLevelDrvInstr_ChangeGearTxt_I 3000;
BA_REL_ "GenSigFirstTimeoutTime" BU_SG_REL_ HMIIOM SG_ 2549028632 OilLevelDrvInstr_NotHorizonTxt_I 12000;
BA_REL_ "GenSigTimeoutTime" BU_SG_REL_ HMIIOM SG_ 2549028632 OilLevelDrvInstr_NotHorizonTxt_I 3000;
BA_REL_ "GenSigFirstTimeoutTime" BU_SG_REL_ HMIIOM SG_ 2549028632 ISeeStatus_ISig_4 12000;
BA_REL_ "GenSigTimeoutTime" BU_SG_REL_ HMIIOM SG_ 2549028632 ISeeStatus_ISig_4 3000;
BA_REL_ "GenSigFirstTimeoutTime" BU_SG_REL_ HMIIOM SG_ 2549028632 EcoRollEnabledStatus_ISig_4 12000;
BA_REL_ "GenSigTimeoutTime" BU_SG_REL_ HMIIOM SG_ 2549028632 EcoRollEnabledStatus_ISig_4 3000;
BA_REL_ "GenSigFirstTimeoutTime" BU_SG_REL_ HMIIOM SG_ 2549028632 OilLevelDrvInstr_OilTempTxt_ISig 12000;
BA_REL_ "GenSigTimeoutTime" BU_SG_REL_ HMIIOM SG_ 2549028632 OilLevelDrvInstr_OilTempTxt_ISig 3000;
BA_REL_ "GenSigFirstTimeoutTime" BU_SG_REL_ HMIIOM SG_ 2549028632 HillDataCtrlTECU_AckCnt_ISig_4 12000;
BA_REL_ "GenSigTimeoutTime" BU_SG_REL_ HMIIOM SG_ 2549028632 HillDataCtrlTECU_AckCnt_ISig_4 3000;
BA_REL_ "GenSigFirstTimeoutTime" BU_SG_REL_ HMIIOM SG_ 2515473944 GearShiftingRec_Steps_ISig_4 3000;
BA_REL_ "GenSigTimeoutTime" BU_SG_REL_ HMIIOM SG_ 2515473944 GearShiftingRec_Steps_ISig_4 600;
BA_REL_ "GenSigFirstTimeoutTime" BU_SG_REL_ HMIIOM SG_ 2515473944 GearShiftingRec_Direction_ISig_4 3000;
BA_REL_ "GenSigTimeoutTime" BU_SG_REL_ HMIIOM SG_ 2515473944 GearShiftingRec_Direction_ISig_4 600;
BA_REL_ "GenSigFirstTimeoutTime" BU_SG_REL_ HMIIOM SG_ 2515473944 BrakeInterlockStatus_ISig_4 3000;
BA_REL_ "GenSigTimeoutTime" BU_SG_REL_ HMIIOM SG_ 2515473944 BrakeInterlockStatus_ISig_4 600;
BA_REL_ "GenSigFirstTimeoutTime" BU_SG_REL_ HMIIOM SG_ 2515473944 AutGearSplitPosition_ISig_4 3000;
BA_REL_ "GenSigTimeoutTime" BU_SG_REL_ HMIIOM SG_ 2515473944 AutGearSplitPosition_ISig_4 600;
BA_REL_ "GenSigFirstTimeoutTime" BU_SG_REL_ HMIIOM SG_ 2515473944 TransmissionBrakeMode_ISig_4 3000;
BA_REL_ "GenSigTimeoutTime" BU_SG_REL_ HMIIOM SG_ 2515473944 TransmissionBrakeMode_ISig_4 600;
BA_REL_ "GenSigFirstTimeoutTime" BU_SG_REL_ HMIIOM SG_ 2515473944 AvailableGearsWithLowerRatio_ISi 3000;
BA_REL_ "GenSigTimeoutTime" BU_SG_REL_ HMIIOM SG_ 2515473944 AvailableGearsWithLowerRatio_ISi 600;
BA_REL_ "GenSigFirstTimeoutTime" BU_SG_REL_ VMCU SG_ 2515473944 FuelEcoDrvStatus 3000;
BA_REL_ "GenSigTimeoutTime" BU_SG_REL_ VMCU SG_ 2515473944 FuelEcoDrvStatus 600;
BA_REL_ "GenSigFirstTimeoutTime" BU_SG_REL_ HMIIOM SG_ 2515473944 EcoCruiseStatus_ISig_4 3000;
BA_REL_ "GenSigTimeoutTime" BU_SG_REL_ HMIIOM SG_ 2515473944 EcoCruiseStatus_ISig_4 600;
BA_REL_ "GenSigFirstTimeoutTime" BU_SG_REL_ EMS SG_ 2515473944 EcoCruiseStatus_ISig_4 3000;
BA_REL_ "GenSigTimeoutTime" BU_SG_REL_ EMS SG_ 2515473944 EcoCruiseStatus_ISig_4 600;
BA_REL_ "GenSigFirstTimeoutTime" BU_SG_REL_ HMIIOM SG_ 2515473944 TransmissionDrivingMode_ISig_4 3000;
BA_REL_ "GenSigTimeoutTime" BU_SG_REL_ HMIIOM SG_ 2515473944 TransmissionDrivingMode_ISig_4 600;
BA_REL_ "GenSigFirstTimeoutTime" BU_SG_REL_ VMCU SG_ 2515473944 ClutchWearStatus 3000;
BA_REL_ "GenSigTimeoutTime" BU_SG_REL_ VMCU SG_ 2515473944 ClutchWearStatus 600;
BA_REL_ "GenSigFirstTimeoutTime" BU_SG_REL_ EMS SG_ 2515473944 AutoWheelBrakeInhibited 3000;
BA_REL_ "GenSigTimeoutTime" BU_SG_REL_ EMS SG_ 2515473944 AutoWheelBrakeInhibited 600;
BA_REL_ "GenSigFirstTimeoutTime" BU_SG_REL_ VMCU SG_ 2515473944 DrivingMode_ISig_4 3000;
BA_REL_ "GenSigTimeoutTime" BU_SG_REL_ VMCU SG_ 2515473944 DrivingMode_ISig_4 600;
BA_REL_ "GenSigFirstTimeoutTime" BU_SG_REL_ HMIIOM SG_ 2515473944 DrivingMode_ISig_4 3000;
BA_REL_ "GenSigTimeoutTime" BU_SG_REL_ HMIIOM SG_ 2515473944 DrivingMode_ISig_4 600;
BA_REL_ "GenSigFirstTimeoutTime" BU_SG_REL_ HMIIOM SG_ 2515473944 AutoWheelBrakesDownshiftSugges_I 3000;
BA_REL_ "GenSigTimeoutTime" BU_SG_REL_ HMIIOM SG_ 2515473944 AutoWheelBrakesDownshiftSugges_I 600;
BA_REL_ "GenSigFirstTimeoutTime" BU_SG_REL_ HMIIOM SG_ 2515473944 TransmissionMainOilPress_stat 3000;
BA_REL_ "GenSigTimeoutTime" BU_SG_REL_ HMIIOM SG_ 2515473944 TransmissionMainOilPress_stat 600;
BA_REL_ "GenSigFirstTimeoutTime" BU_SG_REL_ BBM SG_ 2515473944 TransmissionOilTempHigh_ISig_4 3000;
BA_REL_ "GenSigTimeoutTime" BU_SG_REL_ BBM SG_ 2515473944 TransmissionOilTempHigh_ISig_4 600;
BA_REL_ "GenSigFirstTimeoutTime" BU_SG_REL_ HMIIOM SG_ 2515473944 TransmissionOilTempHigh_ISig_4 3000;
BA_REL_ "GenSigTimeoutTime" BU_SG_REL_ HMIIOM SG_ 2515473944 TransmissionOilTempHigh_ISig_4 600;
BA_REL_ "GenSigFirstTimeoutTime" BU_SG_REL_ VMCU SG_ 2515473944 AvailableGearsWithHigherRatio_IS 3000;
BA_REL_ "GenSigTimeoutTime" BU_SG_REL_ VMCU SG_ 2515473944 AvailableGearsWithHigherRatio_IS 600;
BA_REL_ "GenSigFirstTimeoutTime" BU_SG_REL_ HMIIOM SG_ 2515473944 AvailableGearsWithHigherRatio_IS 3000;
BA_REL_ "GenSigTimeoutTime" BU_SG_REL_ HMIIOM SG_ 2515473944 AvailableGearsWithHigherRatio_IS 600;
BA_REL_ "GenSigFirstTimeoutTime" BU_SG_REL_ BBM SG_ 2432636184 Pto1Consent_ISig_4 3000;
BA_REL_ "GenSigTimeoutTime" BU_SG_REL_ BBM SG_ 2432636184 Pto1Consent_ISig_4 150;
BA_REL_ "GenSigFirstTimeoutTime" BU_SG_REL_ VMCU SG_ 2432636184 Pto1Consent_ISig_4 3000;
BA_REL_ "GenSigTimeoutTime" BU_SG_REL_ VMCU SG_ 2432636184 Pto1Consent_ISig_4 150;
BA_REL_ "GenSigFirstTimeoutTime" BU_SG_REL_ BBM SG_ 2432636184 Pto2Consent_ISig_4 3000;
BA_REL_ "GenSigTimeoutTime" BU_SG_REL_ BBM SG_ 2432636184 Pto2Consent_ISig_4 150;
BA_REL_ "GenSigFirstTimeoutTime" BU_SG_REL_ VMCU SG_ 2432636184 Pto2Consent_ISig_4 3000;
BA_REL_ "GenSigTimeoutTime" BU_SG_REL_ VMCU SG_ 2432636184 Pto2Consent_ISig_4 150;
BA_REL_ "GenSigFirstTimeoutTime" BU_SG_REL_ HMIIOM SG_ 2432636184 DirectionGearAllowed 3000;
BA_REL_ "GenSigTimeoutTime" BU_SG_REL_ HMIIOM SG_ 2432636184 DirectionGearAllowed 150;
BA_REL_ "GenSigFirstTimeoutTime" BU_SG_REL_ VMCU SG_ 2432636184 TransmissionSystemPowerDownAck 3000;
BA_REL_ "GenSigTimeoutTime" BU_SG_REL_ VMCU SG_ 2432636184 TransmissionSystemPowerDownAck 150;
BA_REL_ "GenSigFirstTimeoutTime" BU_SG_REL_ HMIIOM SG_ 2432636184 EcoRollActiveStatus_ISig_4 3000;
BA_REL_ "GenSigTimeoutTime" BU_SG_REL_ HMIIOM SG_ 2432636184 EcoRollActiveStatus_ISig_4 150;
BA_REL_ "GenSigFirstTimeoutTime" BU_SG_REL_ VMCU SG_ 2432636184 EcoRollActiveStatus_ISig_4 3000;
BA_REL_ "GenSigTimeoutTime" BU_SG_REL_ VMCU SG_ 2432636184 EcoRollActiveStatus_ISig_4 150;
BA_REL_ "GenSigFirstTimeoutTime" BU_SG_REL_ HMIIOM SG_ 2432636184 TransmissionAirPressureLow_ISig_ 3000;
BA_REL_ "GenSigTimeoutTime" BU_SG_REL_ HMIIOM SG_ 2432636184 TransmissionAirPressureLow_ISig_ 150;
BA_REL_ "GenSigFirstTimeoutTime" BU_SG_REL_ EMS SG_ 2432636184 TransmEngineStop_req 3000;
BA_REL_ "GenSigTimeoutTime" BU_SG_REL_ EMS SG_ 2432636184 TransmEngineStop_req 150;
BA_REL_ "GenSigFirstTimeoutTime" BU_SG_REL_ CIOM SG_ 2432636184 GearBoxUnlockAuth_rqst 3000;
BA_REL_ "GenSigTimeoutTime" BU_SG_REL_ CIOM SG_ 2432636184 GearBoxUnlockAuth_rqst 150;
BA_REL_ "GenSigFirstTimeoutTime" BU_SG_REL_ HMIIOM SG_ 2432636184 RoadInclination_ISig_4 3000;
BA_REL_ "GenSigTimeoutTime" BU_SG_REL_ HMIIOM SG_ 2432636184 RoadInclination_ISig_4 150;
BA_REL_ "GenSigFirstTimeoutTime" BU_SG_REL_ VMCU SG_ 2432636184 RoadInclination_ISig_4 3000;
BA_REL_ "GenSigTimeoutTime" BU_SG_REL_ VMCU SG_ 2432636184 RoadInclination_ISig_4 150;
BA_REL_ "GenSigFirstTimeoutTime" BU_SG_REL_ EMS SG_ 2432636184 RoadInclination_ISig_4 3000;
BA_REL_ "GenSigTimeoutTime" BU_SG_REL_ EMS SG_ 2432636184 RoadInclination_ISig_4 150;
BA_REL_ "GenSigFirstTimeoutTime" BU_SG_REL_ DACU SG_ 2432636184 RoadInclination_ISig_4 3000;
BA_REL_ "GenSigTimeoutTime" BU_SG_REL_ DACU SG_ 2432636184 RoadInclination_ISig_4 150;
BA_REL_ "GenSigFirstTimeoutTime" BU_SG_REL_ EMS SG_ 2432636184 ACC_SGO_TransmissionStatus 3000;
BA_REL_ "GenSigTimeoutTime" BU_SG_REL_ EMS SG_ 2432636184 ACC_SGO_TransmissionStatus 150;
BA_REL_ "GenSigFirstTimeoutTime" BU_SG_REL_ DACU SG_ 2432636184 ACC_SGO_TransmissionStatus 3000;
BA_REL_ "GenSigTimeoutTime" BU_SG_REL_ DACU SG_ 2432636184 ACC_SGO_TransmissionStatus 150;
BA_REL_ "GenSigFirstTimeoutTime" BU_SG_REL_ HMIIOM SG_ 2432636184 ClutchOverloadStatus_ISig_4 3000;
BA_REL_ "GenSigTimeoutTime" BU_SG_REL_ HMIIOM SG_ 2432636184 ClutchOverloadStatus_ISig_4 150;
BA_REL_ "GenSigFirstTimeoutTime" BU_SG_REL_ BBM SG_ 2432636184 ClutchOverloadStatus_ISig_4 3000;
BA_REL_ "GenSigTimeoutTime" BU_SG_REL_ BBM SG_ 2432636184 ClutchOverloadStatus_ISig_4 150;
BA_REL_ "GenSigTimeoutTime" BU_SG_REL_ VMCU SG_ 2564485459 PhysDiagRespSig_F1_53_ISig_4 600;
BA_REL_ "GenSigFirstTimeoutTime" BU_SG_REL_ CIOM SG_ 2564445169 PhysDiagReqSig_53_F1_ISig_4 3000;
BA_REL_ "GenSigTimeoutTime" BU_SG_REL_ CIOM SG_ 2564445169 PhysDiagReqSig_53_F1_ISig_4 600;
BA_REL_ "GenSigFirstTimeoutTime" BU_SG_REL_ VMCU SG_ 2566635616 FasUsrDefinedStorage_rqst_ISig_4 24000;
BA_REL_ "GenSigTimeoutTime" BU_SG_REL_ VMCU SG_ 2566635616 FasUsrDefinedStorage_rqst_ISig_4 6000;
BA_REL_ "GenSigFirstTimeoutTime" BU_SG_REL_ CIOM SG_ 2566635616 ATC_ButtonIndication_ISig_4 24000;
BA_REL_ "GenSigTimeoutTime" BU_SG_REL_ CIOM SG_ 2566635616 ATC_ButtonIndication_ISig_4 6000;
BA_REL_ "GenSigFirstTimeoutTime" BU_SG_REL_ VMCU SG_ 2566635616 FasLowSpeedReturnSetting_rqst_IS 24000;
BA_REL_ "GenSigTimeoutTime" BU_SG_REL_ VMCU SG_ 2566635616 FasLowSpeedReturnSetting_rqst_IS 6000;
BA_REL_ "GenSigFirstTimeoutTime" BU_SG_REL_ VMCU SG_ 2566635616 FasManualOffsetSetting_rqst_ISig 24000;
BA_REL_ "GenSigTimeoutTime" BU_SG_REL_ VMCU SG_ 2566635616 FasManualOffsetSetting_rqst_ISig 6000;
BA_REL_ "GenSigFirstTimeoutTime" BU_SG_REL_ VMCU SG_ 2566635616 FasPersonalSettingsButton_rqst_I 24000;
BA_REL_ "GenSigTimeoutTime" BU_SG_REL_ VMCU SG_ 2566635616 FasPersonalSettingsButton_rqst_I 6000;
BA_REL_ "GenSigFirstTimeoutTime" BU_SG_REL_ VMCU SG_ 2566635616 FasStiffnessCurveSetting_rqst_IS 24000;
BA_REL_ "GenSigTimeoutTime" BU_SG_REL_ VMCU SG_ 2566635616 FasStiffnessCurveSetting_rqst_IS 6000;
BA_REL_ "GenSigFirstTimeoutTime" BU_SG_REL_ CIOM SG_ 2566635616 ESC_ButtonIndication1 24000;
BA_REL_ "GenSigTimeoutTime" BU_SG_REL_ CIOM SG_ 2566635616 ESC_ButtonIndication1 6000;
BA_REL_ "GenSigFirstTimeoutTime" BU_SG_REL_ VMCU SG_ 2566635616 FasStiffStraightSetting_rqst_ISi 24000;
BA_REL_ "GenSigTimeoutTime" BU_SG_REL_ VMCU SG_ 2566635616 FasStiffStraightSetting_rqst_ISi 6000;
BA_REL_ "GenSigFirstTimeoutTime" BU_SG_REL_ VMCU SG_ 2566635616 FasDriver_rqst_ISig_4 24000;
BA_REL_ "GenSigTimeoutTime" BU_SG_REL_ VMCU SG_ 2566635616 FasDriver_rqst_ISig_4 6000;
BA_REL_ "GenSigFirstTimeoutTime" BU_SG_REL_ VMCU SG_ 2566635616 FasDampingSetting_rqst_ISig_4 24000;
BA_REL_ "GenSigTimeoutTime" BU_SG_REL_ VMCU SG_ 2566635616 FasDampingSetting_rqst_ISig_4 6000;
BA_REL_ "GenSigFirstTimeoutTime" BU_SG_REL_ CIOM SG_ 2566635616 ESC_ButtonIndication2_ISig_4 24000;
BA_REL_ "GenSigTimeoutTime" BU_SG_REL_ CIOM SG_ 2566635616 ESC_ButtonIndication2_ISig_4 6000;
BA_REL_ "GenSigFirstTimeoutTime" BU_SG_REL_ CIOM SG_ 2566635616 TCS_ButtonIndication_ISig_4 24000;
BA_REL_ "GenSigTimeoutTime" BU_SG_REL_ CIOM SG_ 2566635616 TCS_ButtonIndication_ISig_4 6000;
BA_REL_ "GenSigFirstTimeoutTime" BU_SG_REL_ CIOM SG_ 2566635616 ABS_ButtonIndication_ISig_4 24000;
BA_REL_ "GenSigTimeoutTime" BU_SG_REL_ CIOM SG_ 2566635616 ABS_ButtonIndication_ISig_4 6000;
BA_REL_ "GenSigFirstTimeoutTime" BU_SG_REL_ CIOM SG_ 2566635360 ESCOff_DeviceIndication_ISig_4 3000;
BA_REL_ "GenSigTimeoutTime" BU_SG_REL_ CIOM SG_ 2566635360 ESCOff_DeviceIndication_ISig_4 600;
BA_REL_ "GenSigFirstTimeoutTime" BU_SG_REL_ VMCU SG_ 2566635360 DHCActiveRequest 3000;
BA_REL_ "GenSigTimeoutTime" BU_SG_REL_ VMCU SG_ 2566635360 DHCActiveRequest 600;
BA_REL_ "GenSigFirstTimeoutTime" BU_SG_REL_ CIOM SG_ 2566635360 RollerBenchGUIDeviceStatus_ISig_ 3000;
BA_REL_ "GenSigTimeoutTime" BU_SG_REL_ CIOM SG_ 2566635360 RollerBenchGUIDeviceStatus_ISig_ 600;
BA_REL_ "GenSigFirstTimeoutTime" BU_SG_REL_ VMCU SG_ 2566635360 DHCSetSpeedAdjustRequest 3000;
BA_REL_ "GenSigTimeoutTime" BU_SG_REL_ VMCU SG_ 2566635360 DHCSetSpeedAdjustRequest 600;
BA_REL_ "GenSigFirstTimeoutTime" BU_SG_REL_ DACU SG_ 2566635360 AutomaticCMenableStatus_ISig_4 3000;
BA_REL_ "GenSigTimeoutTime" BU_SG_REL_ DACU SG_ 2566635360 AutomaticCMenableStatus_ISig_4 600;
BA_REL_ "GenSigFirstTimeoutTime" BU_SG_REL_ VMCU SG_ 2566635360 AFSActiveAllowedInDP_GUIrqst_ISi 3000;
BA_REL_ "GenSigTimeoutTime" BU_SG_REL_ VMCU SG_ 2566635360 AFSActiveAllowedInDP_GUIrqst_ISi 600;
BA_REL_ "GenSigFirstTimeoutTime" BU_SG_REL_ VMCU SG_ 2477212768 DirInd_StalkStatus_4 3000;
BA_REL_ "GenSigTimeoutTime" BU_SG_REL_ VMCU SG_ 2477212768 DirInd_StalkStatus_4 300;
BA_REL_ "GenSigFirstTimeoutTime" BU_SG_REL_ CIOM SG_ 2477212768 SEMMediaSourceAvail_Source04_ISi 3000;
BA_REL_ "GenSigTimeoutTime" BU_SG_REL_ CIOM SG_ 2477212768 SEMMediaSourceAvail_Source04_ISi 300;
BA_REL_ "GenSigFirstTimeoutTime" BU_SG_REL_ CIOM SG_ 2477212768 SEMMediaSourceAvail_Source10_ISi 3000;
BA_REL_ "GenSigTimeoutTime" BU_SG_REL_ CIOM SG_ 2477212768 SEMMediaSourceAvail_Source10_ISi 300;
BA_REL_ "GenSigFirstTimeoutTime" BU_SG_REL_ CIOM SG_ 2477212768 SEMMediaSourceAvail_SInfo_ISig_4 3000;
BA_REL_ "GenSigTimeoutTime" BU_SG_REL_ CIOM SG_ 2477212768 SEMMediaSourceAvail_SInfo_ISig_4 300;
BA_REL_ "GenSigFirstTimeoutTime" BU_SG_REL_ CIOM SG_ 2477212768 SEM_PresetIndicationCmd_ISig_4 3000;
BA_REL_ "GenSigTimeoutTime" BU_SG_REL_ CIOM SG_ 2477212768 SEM_PresetIndicationCmd_ISig_4 300;
BA_REL_ "GenSigFirstTimeoutTime" BU_SG_REL_ CIOM SG_ 2477212768 SEMMediaSourceAvail_Source09_ISi 3000;
BA_REL_ "GenSigTimeoutTime" BU_SG_REL_ CIOM SG_ 2477212768 SEMMediaSourceAvail_Source09_ISi 300;
BA_REL_ "GenSigFirstTimeoutTime" BU_SG_REL_ CIOM SG_ 2477212768 SEMMediaSourceAvail_Source12_ISi 3000;
BA_REL_ "GenSigTimeoutTime" BU_SG_REL_ CIOM SG_ 2477212768 SEMMediaSourceAvail_Source12_ISi 300;
BA_REL_ "GenSigFirstTimeoutTime" BU_SG_REL_ CIOM SG_ 2477212768 SEMMediaSourceAvail_Source07_ISi 3000;
BA_REL_ "GenSigTimeoutTime" BU_SG_REL_ CIOM SG_ 2477212768 SEMMediaSourceAvail_Source07_ISi 300;
BA_REL_ "GenSigFirstTimeoutTime" BU_SG_REL_ VMCU SG_ 2477212768 TripmeterReset_rqst1_ISig_4 3000;
BA_REL_ "GenSigTimeoutTime" BU_SG_REL_ VMCU SG_ 2477212768 TripmeterReset_rqst1_ISig_4 300;
BA_REL_ "GenSigFirstTimeoutTime" BU_SG_REL_ CIOM SG_ 2477212768 SEMMediaSourceAvail_Source03_ISi 3000;
BA_REL_ "GenSigTimeoutTime" BU_SG_REL_ CIOM SG_ 2477212768 SEMMediaSourceAvail_Source03_ISi 300;
BA_REL_ "GenSigFirstTimeoutTime" BU_SG_REL_ CIOM SG_ 2477212768 SEMMediaSourceAvail_Source11_ISi 3000;
BA_REL_ "GenSigTimeoutTime" BU_SG_REL_ CIOM SG_ 2477212768 SEMMediaSourceAvail_Source11_ISi 300;
BA_REL_ "GenSigFirstTimeoutTime" BU_SG_REL_ CIOM SG_ 2477212768 SEM_AudioVolValIndCmd_ISig_4 3000;
BA_REL_ "GenSigTimeoutTime" BU_SG_REL_ CIOM SG_ 2477212768 SEM_AudioVolValIndCmd_ISig_4 300;
BA_REL_ "GenSigFirstTimeoutTime" BU_SG_REL_ CIOM SG_ 2477212768 SEMMediaSourceAvail_Source02_ISi 3000;
BA_REL_ "GenSigTimeoutTime" BU_SG_REL_ CIOM SG_ 2477212768 SEMMediaSourceAvail_Source02_ISi 300;
BA_REL_ "GenSigFirstTimeoutTime" BU_SG_REL_ CIOM SG_ 2477212768 AudioSourceStat_ISig_4 3000;
BA_REL_ "GenSigTimeoutTime" BU_SG_REL_ CIOM SG_ 2477212768 AudioSourceStat_ISig_4 300;
BA_REL_ "GenSigFirstTimeoutTime" BU_SG_REL_ CIOM SG_ 2477212768 SEMMediaSourceAvail_Source06_ISi 3000;
BA_REL_ "GenSigTimeoutTime" BU_SG_REL_ CIOM SG_ 2477212768 SEMMediaSourceAvail_Source06_ISi 300;
BA_REL_ "GenSigFirstTimeoutTime" BU_SG_REL_ CIOM SG_ 2477212768 SEMMediaSourceAvail_Source00_ISi 3000;
BA_REL_ "GenSigTimeoutTime" BU_SG_REL_ CIOM SG_ 2477212768 SEMMediaSourceAvail_Source00_ISi 300;
BA_REL_ "GenSigFirstTimeoutTime" BU_SG_REL_ CIOM SG_ 2477212768 SEMMediaSourceAvail_Source01_ISi 3000;
BA_REL_ "GenSigTimeoutTime" BU_SG_REL_ CIOM SG_ 2477212768 SEMMediaSourceAvail_Source01_ISi 300;
BA_REL_ "GenSigFirstTimeoutTime" BU_SG_REL_ CIOM SG_ 2477212768 SEMMediaSourceAvail_Source08_ISi 3000;
BA_REL_ "GenSigTimeoutTime" BU_SG_REL_ CIOM SG_ 2477212768 SEMMediaSourceAvail_Source08_ISi 300;
BA_REL_ "GenSigFirstTimeoutTime" BU_SG_REL_ CIOM SG_ 2477212768 SEM_AudioMuteStat_ISig_4 3000;
BA_REL_ "GenSigTimeoutTime" BU_SG_REL_ CIOM SG_ 2477212768 SEM_AudioMuteStat_ISig_4 300;
BA_REL_ "GenSigFirstTimeoutTime" BU_SG_REL_ CIOM SG_ 2477212768 SEMMediaSourceAvail_Source13_ISi 3000;
BA_REL_ "GenSigTimeoutTime" BU_SG_REL_ CIOM SG_ 2477212768 SEMMediaSourceAvail_Source13_ISi 300;
BA_REL_ "GenSigFirstTimeoutTime" BU_SG_REL_ CIOM SG_ 2477212768 SEMMediaSourceAvail_Source05_ISi 3000;
BA_REL_ "GenSigTimeoutTime" BU_SG_REL_ CIOM SG_ 2477212768 SEMMediaSourceAvail_Source05_ISi 300;
BA_REL_ "GenSigFirstTimeoutTime" BU_SG_REL_ VMCU SG_ 2565816160 OBDRelDTC_IC_DtcIdB_ISig_4 12000;
BA_REL_ "GenSigTimeoutTime" BU_SG_REL_ VMCU SG_ 2565816160 OBDRelDTC_IC_DtcIdB_ISig_4 3000;
BA_REL_ "GenSigFirstTimeoutTime" BU_SG_REL_ VMCU SG_ 2565816160 OBDRelDTC_IC_FailTB_ISig_4 12000;
BA_REL_ "GenSigTimeoutTime" BU_SG_REL_ VMCU SG_ 2565816160 OBDRelDTC_IC_FailTB_ISig_4 3000;
BA_REL_ "GenSigFirstTimeoutTime" BU_SG_REL_ VMCU SG_ 2565816160 OBDRelDTC_IC_DtcIdA_ISig_4 12000;
BA_REL_ "GenSigTimeoutTime" BU_SG_REL_ VMCU SG_ 2565816160 OBDRelDTC_IC_DtcIdA_ISig_4 3000;
BA_REL_ "GenSigFirstTimeoutTime" BU_SG_REL_ VMCU SG_ 2565816160 OBDRelDTC_IC_EvalStatA_ISig_4 12000;
BA_REL_ "GenSigTimeoutTime" BU_SG_REL_ VMCU SG_ 2565816160 OBDRelDTC_IC_EvalStatA_ISig_4 3000;
BA_REL_ "GenSigFirstTimeoutTime" BU_SG_REL_ VMCU SG_ 2565816160 OBDRelDTC_IC_EvalResultB_ISig_4 12000;
BA_REL_ "GenSigTimeoutTime" BU_SG_REL_ VMCU SG_ 2565816160 OBDRelDTC_IC_EvalResultB_ISig_4 3000;
BA_REL_ "GenSigFirstTimeoutTime" BU_SG_REL_ VMCU SG_ 2565816160 OBDRelDTC_IC_EvalResultA_ISig_4 12000;
BA_REL_ "GenSigTimeoutTime" BU_SG_REL_ VMCU SG_ 2565816160 OBDRelDTC_IC_EvalResultA_ISig_4 3000;
BA_REL_ "GenSigFirstTimeoutTime" BU_SG_REL_ VMCU SG_ 2565816160 OBDRelDTC_IC_DrvngCycleB_ISig_4 12000;
BA_REL_ "GenSigTimeoutTime" BU_SG_REL_ VMCU SG_ 2565816160 OBDRelDTC_IC_DrvngCycleB_ISig_4 3000;
BA_REL_ "GenSigFirstTimeoutTime" BU_SG_REL_ VMCU SG_ 2565816160 OBDRelDTC_IC_DrvngCycleA_ISig_4 12000;
BA_REL_ "GenSigTimeoutTime" BU_SG_REL_ VMCU SG_ 2565816160 OBDRelDTC_IC_DrvngCycleA_ISig_4 3000;
BA_REL_ "GenSigFirstTimeoutTime" BU_SG_REL_ VMCU SG_ 2565816160 OBDRelDTC_IC_EvalStatB_ISig_4 12000;
BA_REL_ "GenSigTimeoutTime" BU_SG_REL_ VMCU SG_ 2565816160 OBDRelDTC_IC_EvalStatB_ISig_4 3000;
BA_REL_ "GenSigFirstTimeoutTime" BU_SG_REL_ VMCU SG_ 2565816160 OBDRelDTC_IC_FailTA_ISig_4 12000;
BA_REL_ "GenSigTimeoutTime" BU_SG_REL_ VMCU SG_ 2565816160 OBDRelDTC_IC_FailTA_ISig_4 3000;
BA_REL_ "GenSigFirstTimeoutTime" BU_SG_REL_ VMCU SG_ 2565848928 OBDRelDTC_HMIIOM_DtcIdB 12000;
BA_REL_ "GenSigTimeoutTime" BU_SG_REL_ VMCU SG_ 2565848928 OBDRelDTC_HMIIOM_DtcIdB 3000;
BA_REL_ "GenSigFirstTimeoutTime" BU_SG_REL_ VMCU SG_ 2565848928 OBDRelDTC_HMIIOM_EvalResultB 12000;
BA_REL_ "GenSigTimeoutTime" BU_SG_REL_ VMCU SG_ 2565848928 OBDRelDTC_HMIIOM_EvalResultB 3000;
BA_REL_ "GenSigFirstTimeoutTime" BU_SG_REL_ VMCU SG_ 2565848928 OBDRelDTC_HMIIOM_EvalStatB 12000;
BA_REL_ "GenSigTimeoutTime" BU_SG_REL_ VMCU SG_ 2565848928 OBDRelDTC_HMIIOM_EvalStatB 3000;
BA_REL_ "GenSigFirstTimeoutTime" BU_SG_REL_ VMCU SG_ 2565848928 OBDRelDTC_HMIIOM_DtcIdA 12000;
BA_REL_ "GenSigTimeoutTime" BU_SG_REL_ VMCU SG_ 2565848928 OBDRelDTC_HMIIOM_DtcIdA 3000;
BA_REL_ "GenSigFirstTimeoutTime" BU_SG_REL_ VMCU SG_ 2565848928 OBDRelDTC_HMIIOM_EvalResultA 12000;
BA_REL_ "GenSigTimeoutTime" BU_SG_REL_ VMCU SG_ 2565848928 OBDRelDTC_HMIIOM_EvalResultA 3000;
BA_REL_ "GenSigFirstTimeoutTime" BU_SG_REL_ VMCU SG_ 2565848928 OBDRelDTC_HMIIOM_DrvngCycleA 12000;
BA_REL_ "GenSigTimeoutTime" BU_SG_REL_ VMCU SG_ 2565848928 OBDRelDTC_HMIIOM_DrvngCycleA 3000;
BA_REL_ "GenSigFirstTimeoutTime" BU_SG_REL_ VMCU SG_ 2565848928 OBDRelDTC_HMIIOM_FailTB 12000;
BA_REL_ "GenSigTimeoutTime" BU_SG_REL_ VMCU SG_ 2565848928 OBDRelDTC_HMIIOM_FailTB 3000;
BA_REL_ "GenSigFirstTimeoutTime" BU_SG_REL_ VMCU SG_ 2565848928 OBDRelDTC_HMIIOM_EvalStatA 12000;
BA_REL_ "GenSigTimeoutTime" BU_SG_REL_ VMCU SG_ 2565848928 OBDRelDTC_HMIIOM_EvalStatA 3000;
BA_REL_ "GenSigFirstTimeoutTime" BU_SG_REL_ VMCU SG_ 2565848928 OBDRelDTC_HMIIOM_FailTA 12000;
BA_REL_ "GenSigTimeoutTime" BU_SG_REL_ VMCU SG_ 2565848928 OBDRelDTC_HMIIOM_FailTA 3000;
BA_REL_ "GenSigFirstTimeoutTime" BU_SG_REL_ VMCU SG_ 2565848928 OBDRelDTC_HMIIOM_DrvngCycleB 12000;
BA_REL_ "GenSigTimeoutTime" BU_SG_REL_ VMCU SG_ 2565848928 OBDRelDTC_HMIIOM_DrvngCycleB 3000;
BA_REL_ "GenSigFirstTimeoutTime" BU_SG_REL_ VMCU SG_ 2565494624 TPMUnmateTrailerReq_ISig_4 12000;
BA_REL_ "GenSigTimeoutTime" BU_SG_REL_ VMCU SG_ 2565494624 TPMUnmateTrailerReq_ISig_4 3000;
BA_REL_ "GenSigFirstTimeoutTime" BU_SG_REL_ VMCU SG_ 2565494624 TPMSetAxleRefPres_Axle4_ISig_4 12000;
BA_REL_ "GenSigTimeoutTime" BU_SG_REL_ VMCU SG_ 2565494624 TPMSetAxleRefPres_Axle4_ISig_4 3000;
BA_REL_ "GenSigFirstTimeoutTime" BU_SG_REL_ VMCU SG_ 2565494624 TPMPosOfWMReq_VehiclePos_ISig_4 12000;
BA_REL_ "GenSigTimeoutTime" BU_SG_REL_ VMCU SG_ 2565494624 TPMPosOfWMReq_VehiclePos_ISig_4 3000;
BA_REL_ "GenSigFirstTimeoutTime" BU_SG_REL_ VMCU SG_ 2565494624 TPMSetAxleRefPres_Axle1_ISig_4 12000;
BA_REL_ "GenSigTimeoutTime" BU_SG_REL_ VMCU SG_ 2565494624 TPMSetAxleRefPres_Axle1_ISig_4 3000;
BA_REL_ "GenSigFirstTimeoutTime" BU_SG_REL_ VMCU SG_ 2565494624 TPMSetAxleRefPres_Axle2_ISig_4 12000;
BA_REL_ "GenSigTimeoutTime" BU_SG_REL_ VMCU SG_ 2565494624 TPMSetAxleRefPres_Axle2_ISig_4 3000;
BA_REL_ "GenSigFirstTimeoutTime" BU_SG_REL_ VMCU SG_ 2565494624 TPMSetAxleRefPres_Axle3_ISig_4 12000;
BA_REL_ "GenSigTimeoutTime" BU_SG_REL_ VMCU SG_ 2565494624 TPMSetAxleRefPres_Axle3_ISig_4 3000;
BA_REL_ "GenSigFirstTimeoutTime" BU_SG_REL_ VMCU SG_ 2565494624 TPMMateTrailerReq_ISig_4 12000;
BA_REL_ "GenSigTimeoutTime" BU_SG_REL_ VMCU SG_ 2565494624 TPMMateTrailerReq_ISig_4 3000;
BA_REL_ "GenSigFirstTimeoutTime" BU_SG_REL_ VMCU SG_ 2565494624 TPMPosOfWMReq_TireId_ISig_4 12000;
BA_REL_ "GenSigTimeoutTime" BU_SG_REL_ VMCU SG_ 2565494624 TPMPosOfWMReq_TireId_ISig_4 3000;
BA_REL_ "GenSigFirstTimeoutTime" BU_SG_REL_ VMCU SG_ 2565494624 TPMSetAxleRefPres_Axle5_ISig_4 12000;
BA_REL_ "GenSigTimeoutTime" BU_SG_REL_ VMCU SG_ 2565494624 TPMSetAxleRefPres_Axle5_ISig_4 3000;
BA_REL_ "GenSigFirstTimeoutTime" BU_SG_REL_ VMCU SG_ 2565494624 TPMSetAxleRefPres_VehiclePos_ISi 12000;
BA_REL_ "GenSigTimeoutTime" BU_SG_REL_ VMCU SG_ 2565494624 TPMSetAxleRefPres_VehiclePos_ISi 3000;
VAL_ 2432645412 LiftAxle2LiftFuncSelected_ISig_4 7 "LiftAxleLiftAutoFuncSelected_NotAvailable" 6 "LiftAxleLiftAutoFuncSelected_Error" 5 "LiftAxleLiftAutoFuncSelected_Reserved" 4 "LiftAxleLiftAutoFuncSelected_UnlimitedLift" 3 "LiftAxleLiftAutoFuncSelected_LiftOverload" 2 "LiftAxleLiftAutoFuncSelected_LiftPlus30" 1 "LiftAxleLiftAutoFuncSelected_Lift" 0 "LiftAxleLiftAutoFuncSelected_NoLift" ;
VAL_ 2432645412 StopLevelChangeAck_ISig_4 3 "StopLevelChangeStatus_NotAvailable" 2 "StopLevelChangeStatus_ErrorIndicator" 1 "StopLevelChangeStatus_LevelChangedStopped" 0 "StopLevelChangeStatus_NoStopRequest" ;
VAL_ 2432645412 HeightAdjustmentAllowed_ISig_4 3 "FalseTrue_NotAvaiable" 2 "FalseTrue_Error" 1 "FalseTrue_True" 0 "FalseTrue_False" ;
VAL_ 2432645412 LiftAxle2UpRequestACK_ISig_4 7 "LiftAxleUpRequestACK_NotAvailable" 6 "LiftAxleUpRequestACK_Error" 5 "LiftAxleUpRequestACK_SystemDeniedVersatile" 4 "LiftAxleUpRequestACK_LiftDeniedPBrakeActive" 3 "LiftAxleUpRequestACK_LiftDeniedRearOverload" 2 "LiftAxleUpRequestACK_LiftDeniedFrontOverload" 1 "LiftAxleUpRequestACK_ChangeAcknowledged" 0 "LiftAxleUpRequestACK_NoAction" ;
VAL_ 2432645412 RideHeightStatus_ISig_4 15 "RideHeightStatus_NotAvailable" 14 "RideHeightStatus_ErrorIndicator" 13 "RideHeightStatus_NotDefined_03" 12 "RideHeightStatus_NotDefined_02" 11 "RideHeightStatus_NotDefined_01" 10 "RideHeightStatus_NotDefined" 9 "RideHeightStatus_AlternativeDrivePosition2" 8 "RideHeightStatus_AlternativeDrivePosition1" 7 "RideHeightStatus_AlternativeDrivePosition" 6 "RideHeightStatus_HighDrivePosition" 5 "RideHeightStatus_LowDrivePosition" 4 "RideHeightStatus_SpeedDependentDrivePositionHighSpeed" 3 "RideHeightStatus_SpeedDependentDrivePositionLowSpeed" 2 "RideHeightStatus_StandardUserDrivePosition" 1 "RideHeightStatus_StandardFactoryDrivePosition" 0 "RideHeightStatus_Inactive" ;
VAL_ 2432645412 RideHeightOutsideTargetRange_ISi 7 "HeightOutsideTargetRange_NotAvailable" 6 "HeightOutsideTargetRange_Error" 5 "HeightOutsideTargetRange_NotDefined_02" 4 "HeightOutsideTargetRange_NotDefined_01" 3 "HeightOutsideTargetRange_NotDefined" 2 "HeightOutsideTargetRange_ToHigh" 1 "HeightOutsideTargetRange_ToLow" 0 "HeightOutsideTargetRange_Inactive" ;
VAL_ 2432645412 LoadDistributionFuncSelected_ISi 15 "LoadDistributionFuncSelected_NotAvaiable" 14 "LoadDistributionFuncSelected_ErrorIndicator" 13 "LoadDistributionFuncSelected_SpareValue_08" 12 "LoadDistributionFuncSelected_SpareValue_07" 11 "LoadDistributionFuncSelected_SpareValue_06" 10 "LoadDistributionFuncSelected_SpareValue_05" 9 "LoadDistributionFuncSelected_SpareValue_04" 8 "LoadDistributionFuncSelected_SpareValue_03" 7 "LoadDistributionFuncSelected_SpareValue_02" 6 "LoadDistributionFuncSelected_MaximumTractionStartingHelp" 5 "LoadDistributionFuncSelected_VariableAxleLoad" 4 "LoadDistributionFuncSelected_NoLoadDistribution" 3 "LoadDistributionFuncSelected_AlternativeLoad" 2 "LoadDistributionFuncSelected_MaximumTractionTractionHelp" 1 "LoadDistributionFuncSelected_OptimisedTraction" 0 "LoadDistributionFuncSelected_NormalLoad" ;
VAL_ 2432645412 RideHeightStorageAck_ISig_4 3 "StorageAck_NotAvaiable" 2 "StorageAck_Error" 1 "StorageAck_ChangeAcknowledged" 0 "StorageAck_TakeNoAction" ;
VAL_ 2432645412 LiftAxle2LowerACK_ISig_4 7 "LiftAxle2LowerACK_NotAvailable" 6 "LiftAxle2LowerACK_Error" 5 "LiftAxle2LowerACK_SystemDeniedVersatile" 4 "LiftAxle2LowerACK_Spare_01" 3 "LiftAxle2LowerACK_Spare" 2 "LiftAxle2LowerACK_LowerDeniedRAS_EC" 1 "LiftAxle2LowerACK_ChangeAcknowledged" 0 "LiftAxle2LowerACK_NoAction" ;
VAL_ 2432645412 LiftAxle1UpRequestACK_ISig_4 7 "LiftAxleUpRequestACK_NotAvailable" 6 "LiftAxleUpRequestACK_Error" 5 "LiftAxleUpRequestACK_SystemDeniedVersatile" 4 "LiftAxleUpRequestACK_LiftDeniedPBrakeActive" 3 "LiftAxleUpRequestACK_LiftDeniedRearOverload" 2 "LiftAxleUpRequestACK_LiftDeniedFrontOverload" 1 "LiftAxleUpRequestACK_ChangeAcknowledged" 0 "LiftAxleUpRequestACK_NoAction" ;
VAL_ 2432645412 LiftAxle1PositionStatus_ISig_4 7 "LiftAxlePositionStatus_NotAvailable" 6 "LiftAxlePositionStatus_Error" 5 "LiftAxlePositionStatus_Reserved_01" 4 "LiftAxlePositionStatus_Reserved" 3 "LiftAxlePositionStatus_Lifting" 2 "LiftAxlePositionStatus_Lowering" 1 "LiftAxlePositionStatus_Lifted" 0 "LiftAxlePositionStatus_Lowered" ;
VAL_ 2432645412 LiftAxle2AutoLiftSelected_ISig_4 3 "FalseTrue_NotAvaiable" 2 "FalseTrue_Error" 1 "FalseTrue_True" 0 "FalseTrue_False" ;
VAL_ 2432645412 LiftAxle1LowerACK_ISig_4 7 "LiftAxle1LowerACK_NotAvailable" 6 "LiftAxle1LowerACK_Error" 5 "LiftAxle1LowerACK_SystemDeniedVersatile" 4 "LiftAxle1LowerACK_Spare_01" 3 "LiftAxle1LowerACK_Spare" 2 "LiftAxle1LowerACK_LowerDeniedRAS_EC" 1 "LiftAxle1LowerACK_ChangeAcknowledged" 0 "LiftAxle1LowerACK_NoAction" ;
VAL_ 2432645412 LiftAxle2PositionStatus_ISig_4 7 "LiftAxlePositionStatus_NotAvailable" 6 "LiftAxlePositionStatus_Error" 5 "LiftAxlePositionStatus_Reserved_01" 4 "LiftAxlePositionStatus_Reserved" 3 "LiftAxlePositionStatus_Lifting" 2 "LiftAxlePositionStatus_Lowering" 1 "LiftAxlePositionStatus_Lifted" 0 "LiftAxlePositionStatus_Lowered" ;
VAL_ 2432645412 LevelControlInformation_ISig_4 15 "LevelControlInformation_NotAvailable" 14 "LevelControlInformation_Error" 13 "LevelControlInformation_Reserved_06" 12 "LevelControlInformation_Reserved_05" 11 "LevelControlInformation_Reserved_04" 10 "LevelControlInformation_Reserved_03" 9 "LevelControlInformation_Reserved_02" 8 "LevelControlInformation_Reserved_01" 7 "LevelControlInformation_Reserved" 6 "LevelControlInformation_LimpHome" 5 "LevelControlInformation_FerryFunction" 4 "LevelControlInformation_KneelingHeight" 3 "LevelControlInformation_DriveHeight" 2 "LevelControlInformation_DockingHeight" 1 "LevelControlInformation_HeightAdjustment" 0 "LevelControlInformation_Prohibit" ;
VAL_ 2432645412 LoadDistributionChangeACK_ISig_4 7 "LoadDistributionChangeACK_NotAvailable" 6 "LoadDistributionChangeACK_Error" 5 "LoadDistributionChangeACK_SystemDeniedVersatile" 4 "LoadDistributionChangeACK_Reserved_2" 3 "LoadDistributionChangeACK_Reserved_1" 2 "LoadDistributionChangeACK_LoadShiftDeniedFALIMOverload" 1 "LoadDistributionChangeACK_ChangeAcknowledged" 0 "LoadDistributionChangeACK_NoAction" ;
VAL_ 2432645412 LiftAxle1AutoLiftSelected_ISig_4 3 "FalseTrue_NotAvaiable" 2 "FalseTrue_Error" 1 "FalseTrue_True" 0 "FalseTrue_False" ;
VAL_ 2432645412 LiftAxle1LiftFuncSelected_ISig_4 7 "LiftAxleLiftAutoFuncSelected_NotAvailable" 6 "LiftAxleLiftAutoFuncSelected_Error" 5 "LiftAxleLiftAutoFuncSelected_Reserved" 4 "LiftAxleLiftAutoFuncSelected_UnlimitedLift" 3 "LiftAxleLiftAutoFuncSelected_LiftOverload" 2 "LiftAxleLiftAutoFuncSelected_LiftPlus30" 1 "LiftAxleLiftAutoFuncSelected_Lift" 0 "LiftAxleLiftAutoFuncSelected_NoLift" ;
VAL_ 2432645412 RampLevelStorageAck_ISig_4 3 "StorageAck_NotAvaiable" 2 "StorageAck_Error" 1 "StorageAck_ChangeAcknowledged" 0 "StorageAck_TakeNoAction" ;
VAL_ 2432645412 LoadDistributionSelected_ISig_4 15 "LoadDistributionSelected_NotAvailable" 14 "LoadDistributionSelected_Error" 13 "LoadDistributionSelected_Reserved_05" 12 "LoadDistributionSelected_Reserved_04" 11 "LoadDistributionSelected_Reserved_03" 10 "LoadDistributionSelected_TractionHelp2" 9 "LoadDistributionSelected_StartingHelp2" 8 "LoadDistributionSelected_VariableAxleLoad" 7 "LoadDistributionSelected_NoLoadDistribution" 6 "LoadDistributionSelected_TractionHelpInterDiff" 5 "LoadDistributionSelected_StartingHelpInterDiff" 4 "LoadDistributionSelected_AlternativeLoad" 3 "LoadDistributionSelected_TractionHelp" 2 "LoadDistributionSelected_StartingHelp" 1 "LoadDistributionSelected_OptimisedTraction" 0 "LoadDistributionSelected_NormalLoad" ;
VAL_ 2432645412 RideHeightFunctionStatus_ISig_4 15 "RideHeightFunction_NotAvailable" 14 "RideHeightFunction_ErrorIndicator" 13 "RideHeightFunction_NotDefined_05" 12 "RideHeightFunction_NotDefined_04" 11 "RideHeightFunction_NotDefined_03" 10 "RideHeightFunction_NotDefined_02" 9 "RideHeightFunction_NotDefined_01" 8 "RideHeightFunction_NotDefined" 7 "RideHeightFunction_AlternativeDrivePosition2" 6 "RideHeightFunction_AlternativeDrivePosition1" 5 "RideHeightFunction_LowDrivePosition" 4 "RideHeightFunction_HighDrivePosition" 3 "RideHeightFunction_SpeedDependentDrivePosition" 2 "RideHeightFunction_AlternativeDrivePosition" 1 "RideHeightFunction_StandardDrivePosition" 0 "RideHeightFunction_Inactive" ;
VAL_ 2432638500 TransmLowRangeSenseSwitch_ISig_4 3 "OffOn_NotAvailable" 2 "OffOn_Error" 1 "OffOn_On" 0 "OffOn_Off" ;
VAL_ 2432638500 TransmSystemPowerDown_rqst 3 "TransmSystemPowerDown_rqst_DontCare" 2 "TransmSystemPowerDown_rqst_NotDefined" 1 "TransmSystemPowerDown_rqst_PowerDownRequestActive" 0 "TransmSystemPowerDown_rqst_PowerDownRequestInactive" ;
VAL_ 2432638500 TransmissionNeutralSwitch_ISig_4 3 "TransmissionNeutralSwitch_NotAvailable" 2 "TransmissionNeutralSwitch_Error" 1 "TransmissionNeutralSwitch_TransmissionInNeutral" 0 "TransmissionNeutralSwitch_TransmissionNotInNeutral" ;
VAL_ 2432638500 SecuredNeutralPosition_ISig_4 3 "SecuredNeutralPosition_NotAvailable" 2 "SecuredNeutralPosition_Error" 1 "SecuredNeutralPosition_SecuredNeutralPosition" 0 "SecuredNeutralPosition_NotInSecuredNeutralPosition" ;
VAL_ 2432638500 EngineStopRequest_ISig_4 3 "Request_NotAvailable" 2 "Request_Error" 1 "Request_RequestActive" 0 "Request_NotRequested" ;
VAL_ 2432638500 DirectionIndicatorLights_rqst_IS 7 "DirectionIndicatorLights_rqst_NotAvailable" 6 "DirectionIndicatorLights_rqst_Error" 5 "DirectionIndicatorLights_rqst_SpareValue_02" 4 "DirectionIndicatorLights_rqst_SpareValue_01" 3 "DirectionIndicatorLights_rqst_SpareValue" 2 "DirectionIndicatorLights_rqst_RightDirectionIndicatorActive" 1 "DirectionIndicatorLights_rqst_LeftDirectionIndicatorActive" 0 "DirectionIndicatorLights_rqst_NotActive" ;
VAL_ 2432638500 ReverseGearEngaged_ISig_4 3 "ReverseGearEngaged_NotAvailable" 2 "ReverseGearEngaged_Error" 1 "ReverseGearEngaged_ReverseGearEngaged" 0 "ReverseGearEngaged_ReverseGearNotEngaged" ;
VAL_ 2432638500 EngineCrankRequest 3 "Request_NotAvailable" 2 "Request_Error" 1 "Request_RequestActive" 0 "Request_NotRequested" ;
VAL_ 2432638500 ParkBrakeActuationStatus_ISig_4 7 "ParkBrakeActuationStatus_NotAvailable" 6 "ParkBrakeActuationStatus_Error" 5 "ParkBrakeActuationStatus_SpareValue_01" 4 "ParkBrakeActuationStatus_SpareValue" 3 "ParkBrakeActuationStatus_AntiCompound" 2 "ParkBrakeActuationStatus_Parked" 1 "ParkBrakeActuationStatus_PartiallyParked" 0 "ParkBrakeActuationStatus_Released" ;
VAL_ 2432638500 EnginePreheat_rqst 3 "Request_NotAvailable" 2 "Request_Error" 1 "Request_RequestActive" 0 "Request_NotRequested" ;
VAL_ 2432638500 KeyPosition_ISig_4 7 "KeyPosition_NotAvailable" 6 "KeyPosition_ErrorIndicator" 5 "KeyPosition_IgnitionKeyInCrankPosition" 4 "KeyPosition_IgnitionKeyInPreheatPosition" 3 "KeyPosition_IgnitionKeyIn15PositionNormalDrivingPosition" 2 "KeyPosition_IgnitionKeyInAccessoryPosition" 1 "KeyPosition_IgnitionKeyInOffPosition" 0 "KeyPosition_KeyOut" ;
VAL_ 2432638500 GearSplit_Status_ISig_4 3 "GearSplit_Status_NotAvailable" 2 "GearSplit_Status_Error" 1 "GearSplit_Status_HighSplit" 0 "GearSplit_Status_LowSplit" ;
VAL_ 2432638500 FerryFunctionSwitchChangeACK_ISi 3 "Ack2Bit_NotAvailable" 2 "Ack2Bit_Error" 1 "Ack2Bit_ChangeAcknowledged" 0 "Ack2Bit_NoAction" ;
VAL_ 2432638500 DirectionIndication_cmd_ISig_4 15 "DirectionIndication_cmd_NotAvailable" 14 "DirectionIndication_cmd_Error" 13 "DirectionIndication_cmd_ActBothTruckTrailerTelltalesFaultInd" 12 "DirectionIndication_cmd_ActBothTruckTelltalesFaultInd" 11 "DirectionIndication_cmd_ActRghtTruckRghtTrailTelltaleFaultInd" 10 "DirectionIndication_cmd_ActLeftTruckLeftTrailTelltaleFaultInd" 9 "DirectionIndication_cmd_ActRghtTruckTelltaleFaultInd" 8 "DirectionIndication_cmd_ActLeftTruckTelltaleFaultInd" 7 "DirectionIndication_cmd_ActivateBothTruckAndTrailer_Hazard" 6 "DirectionIndication_cmd_ActivateBothTruck_Hazard" 5 "DirectionIndication_cmd_ActivateRightTruckAndTrailer" 4 "DirectionIndication_cmd_ActivateLeftTruckAndTrailer" 3 "DirectionIndication_cmd_ActivateRightTruck" 2 "DirectionIndication_cmd_ActivateLeftTruck" 1 "DirectionIndication_cmd_ActivateLow" 0 "DirectionIndication_cmd_Deactivate" ;
VAL_ 2432638500 IdleShutdownWarning_ISig_4 3 "InactiveActive_NotAvailable" 2 "InactiveActive_Error" 1 "InactiveActive_Active" 0 "InactiveActive_Inactive" ;
VAL_ 2432638500 BackToDriveReqACK_ISig_4 3 "BackToDriveReqACK_NotAvailable" 2 "BackToDriveReqACK_Error" 1 "BackToDriveReqACK_ChangeAcknowledged" 0 "BackToDriveReqACK_TakNoAction" ;
VAL_ 2432638500 EngineSystemPowerDownRequest_ISi 3 "Request_NotAvailable" 2 "Request_Error" 1 "Request_RequestActive" 0 "Request_NotRequested" ;
VAL_ 2511149823 ESCReqSilentMode_CtrlTrimMode 15 "CtrlTrimMode_NotAvailable" 14 "CtrlTrimMode_Error" 13 "CtrlTrimMode_Spare_08" 12 "CtrlTrimMode_Spare_07" 11 "CtrlTrimMode_Spare_06" 10 "CtrlTrimMode_Spare_05" 9 "CtrlTrimMode_Spare_04" 8 "CtrlTrimMode_Spare_03" 7 "CtrlTrimMode_Spare_02" 6 "CtrlTrimMode_Spare_01" 5 "CtrlTrimMode_Spare" 4 "CtrlTrimMode_MuddySiteEngineSpeedControl" 3 "CtrlTrimMode_AirManagementEngineSpeedControl" 2 "CtrlTrimMode_IdleAdjust" 1 "CtrlTrimMode_PTOEngineSpeedControl" 0 "CtrlTrimMode_NoRequest" ;
VAL_ 2511149823 ESCReqSilentMode_CtrlTrimStat 7 "CtrlTrimStat_NotAvailable" 6 "CtrlTrimStat_Error" 5 "CtrlTrimStat_Spare_02" 4 "CtrlTrimStat_Spare_01" 3 "CtrlTrimStat_Spare" 2 "CtrlTrimStat_TrimActive" 1 "CtrlTrimStat_ControlActive" 0 "CtrlTrimStat_NoRequestActive" ;
VAL_ 2511149823 ESCReqSilentMode_CtrlTrimReq 7 "CtrlTrimReq_NotAvailable" 6 "CtrlTrimReq_Error" 5 "CtrlTrimReq_Spare_02" 4 "CtrlTrimReq_Spare_01" 3 "CtrlTrimReq_Spare" 2 "CtrlTrimReq_TrimRampDown" 1 "CtrlTrimReq_TrimRampUp" 0 "CtrlTrimReq_NoRamp" ;
VAL_ 2549028632 OilLevelDrvInstr_IncorrEngSpe_IS 3 "DisplayText_NotAvailable" 2 "DisplayText_Error" 1 "DisplayText_DisplayText" 0 "DisplayText_DoNotDisplayText" ;
VAL_ 2549028632 OilLevelDrvInstr_StopVehicle_ISi 3 "DisplayText_NotAvailable" 2 "DisplayText_Error" 1 "DisplayText_DisplayText" 0 "DisplayText_DoNotDisplayText" ;
VAL_ 2549028632 HillDataCtrlTECU_State_ISig_4 7 "HillDataState_NotAvailable" 6 "HillDataState_Error" 5 "HillDataState_Spare_03" 4 "HillDataState_Spare_02" 3 "HillDataState_Spare_01" 2 "HillDataState_Receive" 1 "HillDataState_Request" 0 "HillDataState_Idle" ;
VAL_ 2549028632 OilLevelDrvInstr_Wait60SecTxt_IS 3 "DisplayText_NotAvailable" 2 "DisplayText_Error" 1 "DisplayText_DisplayText" 0 "DisplayText_DoNotDisplayText" ;
VAL_ 2549028632 ClutchAbuseStatus_ISig_4 3 "ClutchAbuseStatus_NotAvailable" 2 "ClutchAbuseStatus_Error" 1 "ClutchAbuseStatus_ClutchAbused" 0 "ClutchAbuseStatus_ClutchNotAbused" ;
VAL_ 2549028632 TransmissionSplitboxPTOMode_ISig 7 "TransmissionSplitboxPTOMode_NotAvailable" 6 "TransmissionSplitboxPTOMode_Error" 5 "TransmissionSplitboxPTOMode_Spare3" 4 "TransmissionSplitboxPTOMode_Spare2" 3 "TransmissionSplitboxPTOMode_Spare1" 2 "TransmissionSplitboxPTOMode_Running" 1 "TransmissionSplitboxPTOMode_Standby" 0 "TransmissionSplitboxPTOMode_Inactive" ;
VAL_ 2549028632 SchwungStatus 3 "InactiveActive_NotAvailable" 2 "InactiveActive_Error" 1 "InactiveActive_Active" 0 "InactiveActive_Inactive" ;
VAL_ 2549028632 ClutchCalibration_stat 3 "InactiveActive_NotAvailable" 2 "InactiveActive_Error" 1 "InactiveActive_Active" 0 "InactiveActive_Inactive" ;
VAL_ 2549028632 OilLevelDrvInstr_ChangeGearTxt_I 3 "DisplayText_NotAvailable" 2 "DisplayText_Error" 1 "DisplayText_DisplayText" 0 "DisplayText_DoNotDisplayText" ;
VAL_ 2549028632 OilLevelDrvInstr_NotHorizonTxt_I 3 "DisplayText_NotAvailable" 2 "DisplayText_Error" 1 "DisplayText_DisplayText" 0 "DisplayText_DoNotDisplayText" ;
VAL_ 2549028632 ISeeStatus_ISig_4 7 "ISeeStatus_NotAvailable" 6 "ISeeStatus_Error" 5 "ISeeStatus_Spare2" 4 "ISeeStatus_Spare1" 3 "ISeeStatus_EnabledAndActive" 2 "ISeeStatus_EnabledButInactive" 1 "ISeeStatus_Disabled" 0 "ISeeStatus_Off" ;
VAL_ 2549028632 EcoRollEnabledStatus_ISig_4 3 "DisableEnable_NotAvailable" 2 "DisableEnable_Error" 1 "DisableEnable_Enable" 0 "DisableEnable_Disable" ;
VAL_ 2549028632 OilLevelDrvInstr_OilTempTxt_ISig 3 "DisplayText_NotAvailable" 2 "DisplayText_Error" 1 "DisplayText_DisplayText" 0 "DisplayText_DoNotDisplayText" ;
VAL_ 2515473944 GearShiftingRec_Steps_ISig_4 7 "GearShiftingSteps_NotAvailable" 6 "GearShiftingSteps_Error" 5 "GearShiftingSteps_6step" 4 "GearShiftingSteps_5step" 3 "GearShiftingSteps_4step" 2 "GearShiftingSteps_3step" 1 "GearShiftingSteps_2step" 0 "GearShiftingSteps_1step" ;
VAL_ 2515473944 GearShiftingRec_Direction_ISig_4 7 "GearShiftingDirection_NotAvailable" 6 "GearShiftingDirection_Error" 5 "GearShiftingDirection_Spare3" 4 "GearShiftingDirection_Spare2" 3 "GearShiftingDirection_Spare1" 2 "GearShiftingDirection_Down" 1 "GearShiftingDirection_Up" 0 "GearShiftingDirection_NoShiftRecommendation" ;
VAL_ 2515473944 BrakeInterlockStatus_ISig_4 3 "OffOn_NotAvailable" 2 "OffOn_Error" 1 "OffOn_On" 0 "OffOn_Off" ;
VAL_ 2515473944 AutGearSplitPosition_ISig_4 7 "GearSplitPosition_NotAvailable" 6 "GearSplitPosition_Error" 5 "GearSplitPosition_Spare2" 4 "GearSplitPosition_Spare1" 3 "GearSplitPosition_Crawler" 2 "GearSplitPosition_NoSplit" 1 "GearSplitPosition_HighSplit" 0 "GearSplitPosition_LowSplit" ;
VAL_ 2515473944 TransmissionBrakeMode_ISig_4 3 "InactiveActive_NotAvailable" 2 "InactiveActive_Error" 1 "InactiveActive_Active" 0 "InactiveActive_Inactive" ;
VAL_ 2515473944 FuelEcoDrvStatus 3 "InactiveActive_NotAvailable" 2 "InactiveActive_Error" 1 "InactiveActive_Active" 0 "InactiveActive_Inactive" ;
VAL_ 2515473944 EcoCruiseStatus_ISig_4 7 "EcoCruiseStatus_NotAvailable" 6 "EcoCruiseStatus_Error" 5 "EcoCruiseStatus_Spare02" 4 "EcoCruiseStatus_Spare01" 3 "EcoCruiseStatus_Spare" 2 "EcoCruiseStatus_TemporarilyInactive" 1 "EcoCruiseStatus_Active" 0 "EcoCruiseStatus_Inactive" ;
VAL_ 2515473944 TransmissionDrivingMode_ISig_4 7 "TransmissionDrivingMode_NotAvailable" 6 "TransmissionDrivingMode_Spare" 5 "TransmissionDrivingMode_Dynamometer" 4 "TransmissionDrivingMode_HeavyDuty" 3 "TransmissionDrivingMode_PowerPlus" 2 "TransmissionDrivingMode_Power" 1 "TransmissionDrivingMode_EconomyPlus" 0 "TransmissionDrivingMode_Economy" ;
VAL_ 2515473944 AutoWheelBrakeInhibited 3 "InhibitedStatus_NotAvailable" 2 "InhibitedStatus_Error" 1 "InhibitedStatus_Inhibited" 0 "InhibitedStatus_NotInhibited" ;
VAL_ 2515473944 AutoWheelBrakesDownshiftSugges_I 3 "DownshiftSuggest_NotAvailable" 2 "DownshiftSuggest_Error" 1 "DownshiftSuggest_SuggestDownshift" 0 "DownshiftSuggest_NoSuggestion" ;
VAL_ 2515473944 TransmissionMainOilPress_stat 3 "TransmissionMainOilPress_stat_NotAvailable" 2 "TransmissionMainOilPress_stat_Error" 1 "TransmissionMainOilPress_stat_LowPressure" 0 "TransmissionMainOilPress_stat_Ok" ;
VAL_ 2515473944 TransmissionOilTempHigh_ISig_4 7 "TransmissionOilTempHigh_NotAvailable" 6 "TransmissionOilTempHigh_ErrorIndicator" 5 "TransmissionOilTempHigh_SpareValue_02" 4 "TransmissionOilTempHigh_SpareValue_01" 3 "TransmissionOilTempHigh_SpareValue" 2 "TransmissionOilTempHigh_ActiveVeryHighTemp" 1 "TransmissionOilTempHigh_ActiveHighTemp" 0 "TransmissionOilTempHigh_Inactive" ;
VAL_ 2432636184 Pto1Consent_ISig_4 3 "PtoConsent_NotAvailable" 2 "PtoConsent_Error" 1 "PtoConsent_ConsentGivenPTODriveMayBeEngaged" 0 "PtoConsent_ConsentNotGivenPTODriveShouldNotBeEngaged" ;
VAL_ 2432636184 Pto2Consent_ISig_4 3 "PtoConsent_NotAvailable" 2 "PtoConsent_Error" 1 "PtoConsent_ConsentGivenPTODriveMayBeEngaged" 0 "PtoConsent_ConsentNotGivenPTODriveShouldNotBeEngaged" ;
VAL_ 2432636184 DirectionGearAllowed 7 "DirectionGearAllowed_NotAvailable" 6 "DirectionGearAllowed_Error" 5 "DirectionGearAllowed_NotUsed_01" 4 "DirectionGearAllowed_NotUsed" 3 "DirectionGearAllowed_ForwardOrReverseGearAllowed" 2 "DirectionGearAllowed_ReverseGearAllowed" 1 "DirectionGearAllowed_ForwardGearAllowed" 0 "DirectionGearAllowed_NoChangePossible" ;
VAL_ 2432636184 TransmissionSystemPowerDownAck 3 "TransmissionSystemPowerDownAck_DontCare" 2 "TransmissionSystemPowerDownAck_NotDefined" 1 "TransmissionSystemPowerDownAck_OKToPowerDownTECU" 0 "TransmissionSystemPowerDownAck_NotOKToPowerDownTECU" ;
VAL_ 2432636184 EcoRollActiveStatus_ISig_4 3 "InactiveActive_NotAvailable" 2 "InactiveActive_Error" 1 "InactiveActive_Active" 0 "InactiveActive_Inactive" ;
VAL_ 2432636184 TransmissionAirPressureLow_ISig_ 3 "TransmissionAirPressureLow_NotAvailable" 2 "TransmissionAirPressureLow_Error" 1 "TransmissionAirPressureLow_AirPressureLow" 0 "TransmissionAirPressureLow_AirPressureOk" ;
VAL_ 2432636184 TransmEngineStop_req 3 "InactiveActive_NotAvailable" 2 "InactiveActive_Error" 1 "InactiveActive_Active" 0 "InactiveActive_Inactive" ;
VAL_ 2432636184 GearBoxUnlockAuth_rqst 3 "GearBoxUnlockAuth_rqst_NotAvaiable" 2 "GearBoxUnlockAuth_rqst_Error" 1 "GearBoxUnlockAuth_rqst_GearEngagementRequested" 0 "GearBoxUnlockAuth_rqst_GearEngagementNotRequested" ;
VAL_ 2432636184 ACC_SGO_TransmissionStatus 7 "ACC_SGO_TransmissionStatus_NotAvailable" 6 "ACC_SGO_TransmissionStatus_Error" 5 "ACC_SGO_TransmissionStatus_Spare2" 4 "ACC_SGO_TransmissionStatus_ReadyForTakeOff" 3 "ACC_SGO_TransmissionStatus_LowestPossibleSpeedReached" 2 "ACC_SGO_TransmissionStatus_Normal" 1 "ACC_SGO_TransmissionStatus_Take_off_InProgress" 0 "ACC_SGO_TransmissionStatus_ACC_SGO_CanNotBeSupported" ;
VAL_ 2432636184 ClutchOverloadStatus_ISig_4 3 "ClutchOverloadStatus_NotAvailable" 2 "ClutchOverloadStatus_Error" 1 "ClutchOverloadStatus_Overloaded" 0 "ClutchOverloadStatus_NotOverloaded" ;
VAL_ 2566635616 FasUsrDefinedStorage_rqst_ISig_4 3 "FasUsrDefinedStorage_NotAvailable" 2 "FasUsrDefinedStorage_Error" 1 "FasUsrDefinedStorage_StoreUserDefinedSetting" 0 "FasUsrDefinedStorage_DoNotStoreUserDefinedSetting" ;
VAL_ 2566635616 ATC_ButtonIndication_ISig_4 3 "DeviceIndication_SpareValue" 2 "DeviceIndication_Blink" 1 "DeviceIndication_On" 0 "DeviceIndication_Off" ;
VAL_ 2566635616 FasPersonalSettingsButton_rqst_I 7 "FasPersSettingsButton_NotAvailable" 6 "FasPersSettingsButton_Error" 5 "FasPersSettingsButton_Spare" 4 "FasPersSettingsButton_UserDefinedButton" 3 "FasPersSettingsButton_PresetButtonHeavy" 2 "FasPersSettingsButton_PresetButtonFirm" 1 "FasPersSettingsButton_PresetButtonLight" 0 "FasPersSettingsButton_PresetButtonDefault" ;
VAL_ 2566635616 ESC_ButtonIndication1 3 "DeviceIndication_SpareValue" 2 "DeviceIndication_Blink" 1 "DeviceIndication_On" 0 "DeviceIndication_Off" ;
VAL_ 2566635616 FasDriver_rqst_ISig_4 15 "FasDriver_NotAvailable" 14 "FasDriver_Error" 13 "FasDriver_Spare3" 12 "FasDriver_Spare2" 11 "FasDriver_Spare1" 10 "FasDriver_Driver10" 9 "FasDriver_Driver9" 8 "FasDriver_Driver8" 7 "FasDriver_Driver7" 6 "FasDriver_Driver6" 5 "FasDriver_Driver5" 4 "FasDriver_Driver4" 3 "FasDriver_Driver3" 2 "FasDriver_Driver2" 1 "FasDriver_Driver1" 0 "FasDriver_DefaultDriver" ;
VAL_ 2566635616 ESC_ButtonIndication2_ISig_4 3 "DeviceIndication_SpareValue" 2 "DeviceIndication_Blink" 1 "DeviceIndication_On" 0 "DeviceIndication_Off" ;
VAL_ 2566635616 TCS_ButtonIndication_ISig_4 3 "DeviceIndication_SpareValue" 2 "DeviceIndication_Blink" 1 "DeviceIndication_On" 0 "DeviceIndication_Off" ;
VAL_ 2566635616 ABS_ButtonIndication_ISig_4 3 "DeviceIndication_SpareValue" 2 "DeviceIndication_Blink" 1 "DeviceIndication_On" 0 "DeviceIndication_Off" ;
VAL_ 2566635360 ESCOff_DeviceIndication_ISig_4 3 "DeviceIndication_SpareValue" 2 "DeviceIndication_Blink" 1 "DeviceIndication_On" 0 "DeviceIndication_Off" ;
VAL_ 2566635360 DHCActiveRequest 3 "OffOn_NotAvailable" 2 "OffOn_Error" 1 "OffOn_On" 0 "OffOn_Off" ;
VAL_ 2566635360 RollerBenchGUIDeviceStatus_ISig_ 3 "OffOn_NotAvailable" 2 "OffOn_Error" 1 "OffOn_On" 0 "OffOn_Off" ;
VAL_ 2566635360 DHCSetSpeedAdjustRequest 7 "SpeedAdjustRequest_NotAvailable" 6 "SpeedAdjustRequest_Error" 5 "SpeedAdjustRequest_Spare2" 4 "SpeedAdjustRequest_Spare1" 3 "SpeedAdjustRequest_Decrease" 2 "SpeedAdjustRequest_Increase" 1 "SpeedAdjustRequest_Set" 0 "SpeedAdjustRequest_NoRequest" ;
VAL_ 2566635360 AutomaticCMenableStatus_ISig_4 3 "OffOn_NotAvailable" 2 "OffOn_Error" 1 "OffOn_On" 0 "OffOn_Off" ;
VAL_ 2566635360 AFSActiveAllowedInDP_GUIrqst_ISi 3 "InactiveActive_NotAvailable" 2 "InactiveActive_Error" 1 "InactiveActive_Active" 0 "InactiveActive_Inactive" ;
VAL_ 2499772256 MediaSourcesListRsp_SInfo_ISig_4 3 "SignalInfo2bitType_NotAvailable" 2 "SignalInfo2bitType_ErrorIndication" 1 "SignalInfo2bitType_Spare" 0 "SignalInfo2bitType_Valid" ;
VAL_ 2477212768 DirInd_StalkStatus_4 7 "DirInd_StalkStatus_NotAvailable" 6 "DirInd_StalkStatus_Error" 5 "DirInd_StalkStatus_Spare" 4 "DirInd_StalkStatus_RightTemporaryTurningIndication" 3 "DirInd_StalkStatus_LeftTemporaryTurningIndication" 2 "DirInd_StalkStatus_RightTurningIndication" 1 "DirInd_StalkStatus_LeftTurningIndication" 0 "DirInd_StalkStatus_NeutralRestingPositon" ;
VAL_ 2477212768 SEMMediaSourceAvail_Source04_ISi 1 "Bitfield1BitType_True" 0 "Bitfield1BitType_False" ;
VAL_ 2477212768 SEMMediaSourceAvail_Source10_ISi 1 "Bitfield1BitType_True" 0 "Bitfield1BitType_False" ;
VAL_ 2477212768 SEMMediaSourceAvail_SInfo_ISig_4 3 "SignalInfo2bitType_NotAvailable" 2 "SignalInfo2bitType_ErrorIndication" 1 "SignalInfo2bitType_Spare" 0 "SignalInfo2bitType_Valid" ;
VAL_ 2477212768 SEMMediaSourceAvail_Source09_ISi 1 "Bitfield1BitType_True" 0 "Bitfield1BitType_False" ;
VAL_ 2477212768 SEMMediaSourceAvail_Source12_ISi 1 "Bitfield1BitType_True" 0 "Bitfield1BitType_False" ;
VAL_ 2477212768 SEMMediaSourceAvail_Source07_ISi 1 "Bitfield1BitType_True" 0 "Bitfield1BitType_False" ;
VAL_ 2477212768 TripmeterReset_rqst1_ISig_4 7 "TripmeterReset_rqst_NotAvailable" 6 "TripmeterReset_rqst_ErrorIndicator" 5 "TripmeterReset_rqst_SpareValue_02" 4 "TripmeterReset_rqst_SpareValue_01" 3 "TripmeterReset_rqst_SpareValue" 2 "TripmeterReset_rqst_Inactive" 1 "TripmeterReset_rqst_Tripcounter2Reset" 0 "TripmeterReset_rqst_Tripcounter1Reset" ;
VAL_ 2477212768 SEMMediaSourceAvail_Source03_ISi 1 "Bitfield1BitType_True" 0 "Bitfield1BitType_False" ;
VAL_ 2477212768 SEMMediaSourceAvail_Source11_ISi 1 "Bitfield1BitType_True" 0 "Bitfield1BitType_False" ;
VAL_ 2477212768 SEMMediaSourceAvail_Source02_ISi 1 "Bitfield1BitType_True" 0 "Bitfield1BitType_False" ;
VAL_ 2477212768 AudioSourceStat_ISig_4 15 "AudioSource_NotAvailable" 14 "AudioSource_Error" 13 "AudioSource_Source13" 12 "AudioSource_Source12" 11 "AudioSource_Source11" 10 "AudioSource_Source10" 9 "AudioSource_Source09" 8 "AudioSource_Source08" 7 "AudioSource_Source07" 6 "AudioSource_Source06" 5 "AudioSource_Source05" 4 "AudioSource_Source04" 3 "AudioSource_Source03" 2 "AudioSource_Source02" 1 "AudioSource_Source01" 0 "AudioSource_Source00" ;
VAL_ 2477212768 SEMMediaSourceAvail_Source06_ISi 1 "Bitfield1BitType_True" 0 "Bitfield1BitType_False" ;
VAL_ 2477212768 SEMMediaSourceAvail_Source00_ISi 1 "Bitfield1BitType_True" 0 "Bitfield1BitType_False" ;
VAL_ 2477212768 SEMMediaSourceAvail_Source01_ISi 1 "Bitfield1BitType_True" 0 "Bitfield1BitType_False" ;
VAL_ 2477212768 SEMMediaSourceAvail_Source08_ISi 1 "Bitfield1BitType_True" 0 "Bitfield1BitType_False" ;
VAL_ 2477212768 SEM_AudioMuteStat_ISig_4 7 "AudioMute_NotAvailable" 6 "AudioMute_ErrorIndication" 5 "AudioMute_Spare_03" 4 "AudioMute_Spare_02" 3 "AudioMute_Spare_01" 2 "AudioMute_Spare" 1 "AudioMute_Mute" 0 "AudioMute_Off" ;
VAL_ 2477212768 SEMMediaSourceAvail_Source13_ISi 1 "Bitfield1BitType_True" 0 "Bitfield1BitType_False" ;
VAL_ 2477212768 SEMMediaSourceAvail_Source05_ISi 1 "Bitfield1BitType_True" 0 "Bitfield1BitType_False" ;
VAL_ 2565816160 OBDRelDTC_IC_EvalStatA_ISig_4 3 "DTCEvalStatA_NotAvailable" 2 "DTCEvalStatA_Error" 1 "DTCEvalStatA_Complete" 0 "DTCEvalStatA_Incomplete" ;
VAL_ 2565816160 OBDRelDTC_IC_EvalResultB_ISig_4 3 "DTCEvalResultB_NotAvailable" 2 "DTCEvalResultB_Error" 1 "DTCEvalResultB_Passed" 0 "DTCEvalResultB_Failed" ;
VAL_ 2565816160 OBDRelDTC_IC_EvalResultA_ISig_4 3 "DTCEvalResultA_NotAvailable" 2 "DTCEvalResultA_Error" 1 "DTCEvalResultA_Passed" 0 "DTCEvalResultA_Failed" ;
VAL_ 2565816160 OBDRelDTC_IC_DrvngCycleB_ISig_4 3 "DrivingCycleLSBB_NotAvailable" 2 "DrivingCycleLSBB_Error" 1 "DrivingCycleLSBB_Value1" 0 "DrivingCycleLSBB_Value0" ;
VAL_ 2565816160 OBDRelDTC_IC_DrvngCycleA_ISig_4 3 "DrivingCycleLSBA_NotAvailable" 2 "DrivingCycleLSBA_Error" 1 "DrivingCycleLSBA_Value1" 0 "DrivingCycleLSBA_Value0" ;
VAL_ 2565816160 OBDRelDTC_IC_EvalStatB_ISig_4 3 "DTCEvalStatB_NotAvailable" 2 "DTCEvalStatB_Error" 1 "DTCEvalStatB_Complete" 0 "DTCEvalStatB_Incomplete" ;
VAL_ 2565848928 OBDRelDTC_HMIIOM_EvalResultB 3 "DTCEvalResultB_NotAvailable" 2 "DTCEvalResultB_Error" 1 "DTCEvalResultB_Passed" 0 "DTCEvalResultB_Failed" ;
VAL_ 2565848928 OBDRelDTC_HMIIOM_EvalStatB 3 "DTCEvalStatB_NotAvailable" 2 "DTCEvalStatB_Error" 1 "DTCEvalStatB_Complete" 0 "DTCEvalStatB_Incomplete" ;
VAL_ 2565848928 OBDRelDTC_HMIIOM_EvalResultA 3 "DTCEvalResultA_NotAvailable" 2 "DTCEvalResultA_Error" 1 "DTCEvalResultA_Passed" 0 "DTCEvalResultA_Failed" ;
VAL_ 2565848928 OBDRelDTC_HMIIOM_DrvngCycleA 3 "DrivingCycleLSBA_NotAvailable" 2 "DrivingCycleLSBA_Error" 1 "DrivingCycleLSBA_Value1" 0 "DrivingCycleLSBA_Value0" ;
VAL_ 2565848928 OBDRelDTC_HMIIOM_EvalStatA 3 "DTCEvalStatA_NotAvailable" 2 "DTCEvalStatA_Error" 1 "DTCEvalStatA_Complete" 0 "DTCEvalStatA_Incomplete" ;
VAL_ 2565848928 OBDRelDTC_HMIIOM_DrvngCycleB 3 "DrivingCycleLSBB_NotAvailable" 2 "DrivingCycleLSBB_Error" 1 "DrivingCycleLSBB_Value1" 0 "DrivingCycleLSBB_Value0" ;
VAL_ 2565494624 TPMUnmateTrailerReq_ISig_4 3 "Request_NotAvailable" 2 "Request_Error" 1 "Request_RequestActive" 0 "Request_NotRequested" ;
VAL_ 2565494624 TPMPosOfWMReq_VehiclePos_ISig_4 7 "TPMVehiclePos_NotAvailable" 6 "TPMVehiclePos_Error" 5 "TPMVehiclePos_Trailer5Vehicle" 4 "TPMVehiclePos_Trailer4Vehicle" 3 "TPMVehiclePos_Trailer3Vehicle" 2 "TPMVehiclePos_Trailer2Vehicle" 1 "TPMVehiclePos_Trailer1Vehicle" 0 "TPMVehiclePos_TruckVehicle" ;
VAL_ 2565494624 TPMMateTrailerReq_ISig_4 3 "Request_NotAvailable" 2 "Request_Error" 1 "Request_RequestActive" 0 "Request_NotRequested" ;
VAL_ 2565494624 TPMSetAxleRefPres_VehiclePos_ISi 7 "TPMVehiclePos_NotAvailable" 6 "TPMVehiclePos_Error" 5 "TPMVehiclePos_Trailer5Vehicle" 4 "TPMVehiclePos_Trailer4Vehicle" 3 "TPMVehiclePos_Trailer3Vehicle" 2 "TPMVehiclePos_Trailer2Vehicle" 1 "TPMVehiclePos_Trailer1Vehicle" 0 "TPMVehiclePos_TruckVehicle" ;
SIG_GROUP_ 2511149823 ESCReqSilentMode_sg 1 : ESCReqSilentMode_CtrlTrimValue ESCReqSilentMode_CtrlTrimMode ESCReqSilentMode_CtrlTrimStat ESCReqSilentMode_CtrlTrimReq;
SIG_GROUP_ 2549028632 OilLevelDrvInstr_sg_ISig_4 1 : OilLevelDrvInstr_IncorrEngSpe_IS OilLevelDrvInstr_StopVehicle_ISi OilLevelDrvInstr_Wait60SecTxt_IS OilLevelDrvInstr_ChangeGearTxt_I OilLevelDrvInstr_NotHorizonTxt_I OilLevelDrvInstr_OilTempTxt_ISig;
SIG_GROUP_ 2549028632 HillDataCtrlTECU_sg_ISig_4 1 : HillDataCtrlTECU_State_ISig_4 HillDataCtrlTECU_AckCnt_ISig_4;
SIG_GROUP_ 2515473944 GearShiftingRec_sg_ISig_4 1 : GearShiftingRec_Steps_ISig_4 GearShiftingRec_Direction_ISig_4;
SIG_GROUP_ 2499772256 MediaSourcesListRsp_sg_ISig_4 1 : MediaSourcesListRsp_SrcAttrib_IS MediaSourcesListRsp_SInfo_ISig_4 MediaSourcesListRsp_Name_ISig_4 MediaSourcesListRsp_PCI_ISig_4 MediaSourcesListRsp_ItemID_ISig_;
SIG_GROUP_ 2477212768 SEMMediaSourceAvail_sg_ISig_4 1 : SEMMediaSourceAvail_Source04_ISi SEMMediaSourceAvail_Source10_ISi SEMMediaSourceAvail_SInfo_ISig_4 SEMMediaSourceAvail_Source09_ISi SEMMediaSourceAvail_Source12_ISi SEMMediaSourceAvail_Source07_ISi SEMMediaSourceAvail_Source03_ISi SEMMediaSourceAvail_Source11_ISi SEMMediaSourceAvail_Source02_ISi SEMMediaSourceAvail_Source06_ISi SEMMediaSourceAvail_Source00_ISi SEMMediaSourceAvail_Source01_ISi SEMMediaSourceAvail_Source08_ISi SEMMediaSourceAvail_Source13_ISi SEMMediaSourceAvail_Source05_ISi;
SIG_GROUP_ 2565816160 OBDRelDTC_IC_sg_ISig_4 1 : OBDRelDTC_IC_DtcIdB_ISig_4 OBDRelDTC_IC_FailTB_ISig_4 OBDRelDTC_IC_DtcIdA_ISig_4 OBDRelDTC_IC_EvalStatA_ISig_4 OBDRelDTC_IC_EvalResultB_ISig_4 OBDRelDTC_IC_EvalResultA_ISig_4 OBDRelDTC_IC_DrvngCycleB_ISig_4 OBDRelDTC_IC_DrvngCycleA_ISig_4 OBDRelDTC_IC_EvalStatB_ISig_4 OBDRelDTC_IC_FailTA_ISig_4;
SIG_GROUP_ 2565848928 OBDRelDTC_HMIIOM_sg 1 : OBDRelDTC_HMIIOM_DtcIdB OBDRelDTC_HMIIOM_EvalResultB OBDRelDTC_HMIIOM_EvalStatB OBDRelDTC_HMIIOM_DtcIdA OBDRelDTC_HMIIOM_EvalResultA OBDRelDTC_HMIIOM_DrvngCycleA OBDRelDTC_HMIIOM_FailTB OBDRelDTC_HMIIOM_EvalStatA OBDRelDTC_HMIIOM_FailTA OBDRelDTC_HMIIOM_DrvngCycleB;
SIG_GROUP_ 2565494624 TPMPosOfWMReq_sg_ISig_4 1 : TPMPosOfWMReq_VehiclePos_ISig_4 TPMPosOfWMReq_TireId_ISig_4;
SIG_GROUP_ 2565494624 TPMSetAxleRefPres_sg_ISig_4 1 : TPMSetAxleRefPres_Axle4_ISig_4 TPMSetAxleRefPres_Axle1_ISig_4 TPMSetAxleRefPres_Axle2_ISig_4 TPMSetAxleRefPres_Axle3_ISig_4 TPMSetAxleRefPres_Axle5_ISig_4 TPMSetAxleRefPres_VehiclePos_ISi;
